[part 19 of 22: packages /TPConfig to /ComponentTypes]
AUTOSAR XML (schema 4-3-0)
package /TPConfig
  can tp config CanTPConfig_E3V_K2CANFD: communication-cluster=E3V_K2CANFD, can-tp-ecu=SAM
    33 x can tp address:
      TA_0x17FC00A5: tp-address=402391205
      TA_0x17FC030E: tp-address=402391822
      TA_0x17FC1601: tp-address=402396673
      TA_0x17FC176E: tp-address=402397038
      TA_0x17FE00A5: tp-address=402522277
      TA_0x17FE030E: tp-address=402522894
      TA_0x17FE1601: tp-address=402527745
      TA_0x17FE176E: tp-address=402528110
      TA_0x1C40000E: tp-address=473956366
      TA_0x1C40002C: tp-address=473956396
      TA_0x1C400031: tp-address=473956401
      TA_0x1C4000A5: tp-address=473956517
      TA_0x1C40020E: tp-address=473956878
      TA_0x1C40022C: tp-address=473956908
      TA_0x1C400231: tp-address=473956913
      TA_0x1C4002A5: tp-address=473957029
      TA_0x1C410000: tp-address=474021888
      TA_0x1C410200: tp-address=474022400
      TA_0x1C42000E: tp-address=474087438
      TA_0x1C42002C: tp-address=474087468
      TA_0x1C420031: tp-address=474087473
      TA_0x1C4200A5: tp-address=474087589
      TA_0x1C42020E: tp-address=474087950
      TA_0x1C42022C: tp-address=474087980
      TA_0x1C420231: tp-address=474087985
      TA_0x1C4202A5: tp-address=474088101
      TA_0x700: tp-address=1792
      TA_0x70E: tp-address=1806
      TA_0x72C: tp-address=1836
      TA_0x731: tp-address=1841
      TA_0x778: tp-address=1912
      TA_0x796: tp-address=1942
      TA_0x79B: tp-address=1947
    9 x can tp channel, all with channel-mode=HALF-DUPLEX-MODE:
      TPC_E3V_K2CANFD_XIX_TPCHType_CANFD_ISO_Diagnose_XIX_0x1C40000E_XIX_0x1C42000E_XIX_Physical: channel-id=292018242
      TPC_E3V_K2CANFD_XIX_TPCHType_CANFD_ISO_Diagnose_XIX_0x1C410000_XIX_Functional: channel-id=1297027718
      TPC_E3V_K2CANFD_XIX_TPCHType_CANFD_OBDC_Diagnose_XIX_0x1C40020E_XIX_0x1C42020E_XIX_Physical: channel-id=1588766103
      TPC_E3V_K2CANFD_XIX_TPCHType_CANFD_OBDC_Diagnose_XIX_0x1C410200_XIX_Functional: channel-id=763241601
      TPC_E3V_K2CANFD_XIX_TPCHType_CANHS_Flash_DIA_XIX_0x17FC1601_XIX_0x17FE1601_XIX_Physical: channel-id=602316840
      TPC_E3V_K2CANFD_XIX_TPCHType_CANHS_Flash_DIA_XIX_0x17FC176E_XIX_0x17FE176E_XIX_Physical: channel-id=421749768
      TPC_E3V_K2CANFD_XIX_TPCHType_CANHS_FoD_Master_XIX_0x17FC030E_XIX_0x17FE030E_XIX_Physical: channel-id=1065783997
      TPC_E3V_K2CANFD_XIX_TPCHType_CANHS_ISO_Diagnose_XIX_0x700_XIX_Functional: channel-id=299429439
      TPC_E3V_K2CANFD_XIX_TPCHType_CANHS_ISO_Diagnose_XIX_0x70E_XIX_0x778_XIX_Physical: channel-id=794831463
    can-tp-connection addressing-format=STANDARD, can-tp-channel=TPC_E3V_K2CANFD_XIX_TPCHType_CANFD_ISO_Diagnose_XIX_0x1C40000E_XIX_0x1C42000E_XIX_Physical, cancellation=true, data-pdu=ISOx_BCM1_Req_FD_XIX_E3V_K2CANFD, flow-control-pdu=ISOx_BCM1_Resp_FD_XIX_E3V_K2CANFD, max-block-size=15, padding-activation=true, receiver=TPN_BCM1_XIX_E3V_K2CANFD_XIX_474087438, ta-type=PHYSICAL, timeout-br=0.1, timeout-bs=1.0, timeout-cr=1.0, timeout-cs=0.2, tp-sdu=DCM_E3V_K2CANFD_XIX_TPCHType_CANFD_ISO_Diagnose_XIX_0x1C40000E_XIX_0x1C42000E_XIX_Physical, transmitter=TPN_Gateway_XIX_E3V_K2CANFD_XIX_473956366:
      ident TPCN_E3V_K2CANFD_XIX_TPCHType_CANFD_ISO_Diagnose_XIX_0x1C40000E_Gateway_XIX_0x1C42000E_BCM1_XIX_Physical
    can-tp-connection addressing-format=STANDARD, can-tp-channel=TPC_E3V_K2CANFD_XIX_TPCHType_CANFD_ISO_Diagnose_XIX_0x1C410000_XIX_Functional, cancellation=true, data-pdu=ISOx_Funkt_Req_All_FD_XIX_E3V_K2CANFD, max-block-size=15, multicast=TA_0x1C410000, padding-activation=true, receiver=[TPN_ELV_XIX_E3V_K2CANFD_XIX_474087473, TPN_MFG_XIX_E3V_K2CANFD_XIX_474087468, TPN_BCM1_XIX_E3V_K2CANFD_XIX_474087438, TPN_WLC1_XIX_E3V_K2CANFD_XIX_474087589], ta-type=FUNCTIONAL, timeout-br=0.1, timeout-bs=1.0, timeout-cr=1.0, timeout-cs=0.2, tp-sdu=DCM_E3V_K2CANFD_XIX_TPCHType_CANFD_ISO_Diagnose_XIX_0x1C410000_XIX_Functional, transmitter=TPN_Gateway_XIX_E3V_K2CANFD_XIX_473956366:
      ident TPCN_E3V_K2CANFD_XIX_TPCHType_CANFD_ISO_Diagnose_XIX_0x1C410000_Gateway_XIX_Functional
    can-tp-connection addressing-format=STANDARD, can-tp-channel=TPC_E3V_K2CANFD_XIX_TPCHType_CANFD_ISO_Diagnose_XIX_0x1C40000E_XIX_0x1C42000E_XIX_Physical, cancellation=true, data-pdu=ISOx_BCM1_Resp_FD_XIX_E3V_K2CANFD, flow-control-pdu=ISOx_BCM1_Req_FD_XIX_E3V_K2CANFD, max-block-size=15, padding-activation=true, receiver=TPN_Gateway_XIX_E3V_K2CANFD_XIX_473956366, ta-type=PHYSICAL, timeout-br=0.1, timeout-bs=1.0, timeout-cr=1.0, timeout-cs=0.2, tp-sdu=DCM_E3V_K2CANFD_XIX_TPCHType_CANFD_ISO_Diagnose_XIX_0x1C42000E_XIX_0x1C40000E_XIX_Physical, transmitter=TPN_BCM1_XIX_E3V_K2CANFD_XIX_474087438:
      ident TPCN_E3V_K2CANFD_XIX_TPCHType_CANFD_ISO_Diagnose_XIX_0x1C42000E_BCM1_XIX_0x1C40000E_Gateway_XIX_Physical
    can-tp-connection addressing-format=STANDARD, can-tp-channel=TPC_E3V_K2CANFD_XIX_TPCHType_CANFD_OBDC_Diagnose_XIX_0x1C40020E_XIX_0x1C42020E_XIX_Physical, cancellation=true, data-pdu=OBDC_BCM1_Req_FD_XIX_E3V_K2CANFD, flow-control-pdu=OBDC_BCM1_Resp_FD_XIX_E3V_K2CANFD, max-block-size=15, padding-activation=true, receiver=TPN_BCM1_XIX_E3V_K2CANFD_XIX_474087950, ta-type=PHYSICAL, timeout-br=0.1, timeout-bs=1.0, timeout-cr=1.0, timeout-cs=0.2, tp-sdu=DCM_E3V_K2CANFD_XIX_TPCHType_CANFD_OBDC_Diagnose_XIX_0x1C40020E_XIX_0x1C42020E_XIX_Physical, transmitter=TPN_Gateway_XIX_E3V_K2CANFD_XIX_473956878:
      ident TPCN_E3V_K2CANFD_XIX_TPCHType_CANFD_OBDC_Diagnose_XIX_0x1C40020E_Gateway_XIX_0x1C42020E_BCM1_XIX_Physical
    can-tp-connection addressing-format=STANDARD, can-tp-channel=TPC_E3V_K2CANFD_XIX_TPCHType_CANFD_OBDC_Diagnose_XIX_0x1C410200_XIX_Functional, cancellation=true, data-pdu=OBDC_Funktionaler_Req_All_FD_XIX_E3V_K2CANFD, max-block-size=15, multicast=TA_0x1C410200, padding-activation=true, receiver=[TPN_ELV_XIX_E3V_K2CANFD_XIX_474087985, TPN_MFG_XIX_E3V_K2CANFD_XIX_474087980, TPN_BCM1_XIX_E3V_K2CANFD_XIX_474087950, TPN_WLC1_XIX_E3V_K2CANFD_XIX_474088101], ta-type=FUNCTIONAL, timeout-br=0.1, timeout-bs=1.0, timeout-cr=1.0, timeout-cs=0.2, tp-sdu=DCM_E3V_K2CANFD_XIX_TPCHType_CANFD_OBDC_Diagnose_XIX_0x1C410200_XIX_Functional, transmitter=TPN_Gateway_XIX_E3V_K2CANFD_XIX_473956878:
      ident TPCN_E3V_K2CANFD_XIX_TPCHType_CANFD_OBDC_Diagnose_XIX_0x1C410200_Gateway_XIX_Functional
    can-tp-connection addressing-format=STANDARD, can-tp-channel=TPC_E3V_K2CANFD_XIX_TPCHType_CANFD_OBDC_Diagnose_XIX_0x1C40020E_XIX_0x1C42020E_XIX_Physical, cancellation=true, data-pdu=OBDC_BCM1_Resp_FD_XIX_E3V_K2CANFD, flow-control-pdu=OBDC_BCM1_Req_FD_XIX_E3V_K2CANFD, max-block-size=15, padding-activation=true, receiver=TPN_Gateway_XIX_E3V_K2CANFD_XIX_473956878, ta-type=PHYSICAL, timeout-br=0.1, timeout-bs=1.0, timeout-cr=1.0, timeout-cs=0.2, tp-sdu=DCM_E3V_K2CANFD_XIX_TPCHType_CANFD_OBDC_Diagnose_XIX_0x1C42020E_XIX_0x1C40020E_XIX_Physical, transmitter=TPN_BCM1_XIX_E3V_K2CANFD_XIX_474087950:
      ident TPCN_E3V_K2CANFD_XIX_TPCHType_CANFD_OBDC_Diagnose_XIX_0x1C42020E_BCM1_XIX_0x1C40020E_Gateway_XIX_Physical
    can-tp-connection addressing-format=STANDARD, can-tp-channel=TPC_E3V_K2CANFD_XIX_TPCHType_CANHS_Flash_DIA_XIX_0x17FC1601_XIX_0x17FE1601_XIX_Physical, cancellation=true, data-pdu=DIA_WWS_Req_XIX_E3V_K2CANFD, flow-control-pdu=DIA_WWS_Resp_XIX_E3V_K2CANFD, max-block-size=15, padding-activation=true, receiver=TPN_BCM1_XIX_E3V_K2CANFD_XIX_402527745, ta-type=PHYSICAL, timeout-br=0.1, timeout-bs=1.0, timeout-cr=1.0, timeout-cs=0.2, tp-sdu=DCM_E3V_K2CANFD_XIX_TPCHType_CANHS_Flash_DIA_XIX_0x17FC1601_XIX_0x17FE1601_XIX_Physical, transmitter=TPN_Gateway_XIX_E3V_K2CANFD_XIX_402396673:
      ident TPCN_E3V_K2CANFD_XIX_TPCHType_CANHS_Flash_DIA_XIX_0x17FC1601_Gateway_XIX_0x17FE1601_BCM1_XIX_Physical
    can-tp-connection addressing-format=STANDARD, can-tp-channel=TPC_E3V_K2CANFD_XIX_TPCHType_CANHS_Flash_DIA_XIX_0x17FC176E_XIX_0x17FE176E_XIX_Physical, cancellation=true, data-pdu=DIA_WWS2_Req_XIX_E3V_K2CANFD, flow-control-pdu=DIA_WWS2_Resp_XIX_E3V_K2CANFD, max-block-size=15, padding-activation=true, receiver=TPN_BCM1_XIX_E3V_K2CANFD_XIX_402528110, ta-type=PHYSICAL, timeout-br=0.1, timeout-bs=1.0, timeout-cr=1.0, timeout-cs=0.2, tp-sdu=DCM_E3V_K2CANFD_XIX_TPCHType_CANHS_Flash_DIA_XIX_0x17FC176E_XIX_0x17FE176E_XIX_Physical, transmitter=TPN_Gateway_XIX_E3V_K2CANFD_XIX_402397038:
      ident TPCN_E3V_K2CANFD_XIX_TPCHType_CANHS_Flash_DIA_XIX_0x17FC176E_Gateway_XIX_0x17FE176E_BCM1_XIX_Physical
    can-tp-connection addressing-format=STANDARD, can-tp-channel=TPC_E3V_K2CANFD_XIX_TPCHType_CANHS_Flash_DIA_XIX_0x17FC1601_XIX_0x17FE1601_XIX_Physical, cancellation=true, data-pdu=DIA_WWS_Resp_XIX_E3V_K2CANFD, flow-control-pdu=DIA_WWS_Req_XIX_E3V_K2CANFD, max-block-size=15, padding-activation=true, receiver=TPN_Gateway_XIX_E3V_K2CANFD_XIX_402396673, ta-type=PHYSICAL, timeout-br=0.1, timeout-bs=1.0, timeout-cr=1.0, timeout-cs=0.2, tp-sdu=DCM_E3V_K2CANFD_XIX_TPCHType_CANHS_Flash_DIA_XIX_0x17FE1601_XIX_0x17FC1601_XIX_Physical, transmitter=TPN_BCM1_XIX_E3V_K2CANFD_XIX_402527745:
      ident TPCN_E3V_K2CANFD_XIX_TPCHType_CANHS_Flash_DIA_XIX_0x17FE1601_BCM1_XIX_0x17FC1601_Gateway_XIX_Physical
    can-tp-connection addressing-format=STANDARD, can-tp-channel=TPC_E3V_K2CANFD_XIX_TPCHType_CANHS_Flash_DIA_XIX_0x17FC176E_XIX_0x17FE176E_XIX_Physical, cancellation=true, data-pdu=DIA_WWS2_Resp_XIX_E3V_K2CANFD, flow-control-pdu=DIA_WWS2_Req_XIX_E3V_K2CANFD, max-block-size=15, padding-activation=true, receiver=TPN_Gateway_XIX_E3V_K2CANFD_XIX_402397038, ta-type=PHYSICAL, timeout-br=0.1, timeout-bs=1.0, timeout-cr=1.0, timeout-cs=0.2, tp-sdu=DCM_E3V_K2CANFD_XIX_TPCHType_CANHS_Flash_DIA_XIX_0x17FE176E_XIX_0x17FC176E_XIX_Physical, transmitter=TPN_BCM1_XIX_E3V_K2CANFD_XIX_402528110:
      ident TPCN_E3V_K2CANFD_XIX_TPCHType_CANHS_Flash_DIA_XIX_0x17FE176E_BCM1_XIX_0x17FC176E_Gateway_XIX_Physical
    can-tp-connection addressing-format=STANDARD, can-tp-channel=TPC_E3V_K2CANFD_XIX_TPCHType_CANHS_FoD_Master_XIX_0x17FC030E_XIX_0x17FE030E_XIX_Physical, cancellation=true, data-pdu=FoD_BCM1_Req_XIX_E3V_K2CANFD, flow-control-pdu=FoD_BCM1_Resp_XIX_E3V_K2CANFD, max-block-size=15, padding-activation=true, receiver=TPN_BCM1_XIX_E3V_K2CANFD_XIX_402522894, ta-type=PHYSICAL, timeout-br=0.1, timeout-bs=1.0, timeout-cr=1.0, timeout-cs=0.2, tp-sdu=SOK_E3V_K2CANFD_XIX_TPCHType_CANHS_FoD_Master_XIX_0x17FC030E_XIX_0x17FE030E_XIX_Physical, transmitter=TPN_Gateway_XIX_E3V_K2CANFD_XIX_402391822:
      ident TPCN_E3V_K2CANFD_XIX_TPCHType_CANHS_FoD_Master_XIX_0x17FC030E_Gateway_XIX_0x17FE030E_BCM1_XIX_Physical
    can-tp-connection addressing-format=STANDARD, can-tp-channel=TPC_E3V_K2CANFD_XIX_TPCHType_CANHS_FoD_Master_XIX_0x17FC030E_XIX_0x17FE030E_XIX_Physical, cancellation=true, data-pdu=FoD_BCM1_Resp_XIX_E3V_K2CANFD, flow-control-pdu=FoD_BCM1_Req_XIX_E3V_K2CANFD, max-block-size=15, padding-activation=true, receiver=TPN_Gateway_XIX_E3V_K2CANFD_XIX_402391822, ta-type=PHYSICAL, timeout-br=0.1, timeout-bs=1.0, timeout-cr=1.0, timeout-cs=0.2, tp-sdu=SOK_E3V_K2CANFD_XIX_TPCHType_CANHS_FoD_Master_XIX_0x17FE030E_XIX_0x17FC030E_XIX_Physical, transmitter=TPN_BCM1_XIX_E3V_K2CANFD_XIX_402522894:
      ident TPCN_E3V_K2CANFD_XIX_TPCHType_CANHS_FoD_Master_XIX_0x17FE030E_BCM1_XIX_0x17FC030E_Gateway_XIX_Physical
    can-tp-connection addressing-format=STANDARD, can-tp-channel=TPC_E3V_K2CANFD_XIX_TPCHType_CANHS_ISO_Diagnose_XIX_0x700_XIX_Functional, cancellation=true, data-pdu=ISO_Funktionaler_Req_All_XIX_E3V_K2CANFD, max-block-size=15, multicast=TA_0x700, padding-activation=true, receiver=[TPN_ELV_XIX_E3V_K2CANFD_XIX_1947, TPN_MFG_XIX_E3V_K2CANFD_XIX_1942, TPN_BCM1_XIX_E3V_K2CANFD_XIX_1912, TPN_WLC1_XIX_E3V_K2CANFD_XIX_402522277], ta-type=FUNCTIONAL, timeout-br=0.1, timeout-bs=1.0, timeout-cr=1.0, timeout-cs=0.2, tp-sdu=DCM_E3V_K2CANFD_XIX_TPCHType_CANHS_ISO_Diagnose_XIX_0x700_XIX_Functional, transmitter=TPN_Gateway_XIX_E3V_K2CANFD_XIX_1806:
      ident TPCN_E3V_K2CANFD_XIX_TPCHType_CANHS_ISO_Diagnose_XIX_0x700_Gateway_XIX_Functional
    can-tp-connection addressing-format=STANDARD, can-tp-channel=TPC_E3V_K2CANFD_XIX_TPCHType_CANHS_ISO_Diagnose_XIX_0x70E_XIX_0x778_XIX_Physical, cancellation=true, data-pdu=ISO_BCM1_Req_XIX_E3V_K2CANFD, flow-control-pdu=ISO_BCM1_Resp_XIX_E3V_K2CANFD, max-block-size=15, padding-activation=true, receiver=TPN_BCM1_XIX_E3V_K2CANFD_XIX_1912, ta-type=PHYSICAL, timeout-br=0.1, timeout-bs=1.0, timeout-cr=1.0, timeout-cs=0.2, tp-sdu=DCM_E3V_K2CANFD_XIX_TPCHType_CANHS_ISO_Diagnose_XIX_0x70E_XIX_0x778_XIX_Physical, transmitter=TPN_Gateway_XIX_E3V_K2CANFD_XIX_1806:
      ident TPCN_E3V_K2CANFD_XIX_TPCHType_CANHS_ISO_Diagnose_XIX_0x70E_Gateway_XIX_0x778_BCM1_XIX_Physical
    can-tp-connection addressing-format=STANDARD, can-tp-channel=TPC_E3V_K2CANFD_XIX_TPCHType_CANHS_ISO_Diagnose_XIX_0x70E_XIX_0x778_XIX_Physical, cancellation=true, data-pdu=ISO_BCM1_Resp_XIX_E3V_K2CANFD, flow-control-pdu=ISO_BCM1_Req_XIX_E3V_K2CANFD, max-block-size=15, padding-activation=true, receiver=TPN_Gateway_XIX_E3V_K2CANFD_XIX_1806, ta-type=PHYSICAL, timeout-br=0.1, timeout-bs=1.0, timeout-cr=1.0, timeout-cs=0.2, tp-sdu=DCM_E3V_K2CANFD_XIX_TPCHType_CANHS_ISO_Diagnose_XIX_0x778_XIX_0x70E_XIX_Physical, transmitter=TPN_BCM1_XIX_E3V_K2CANFD_XIX_1912:
      ident TPCN_E3V_K2CANFD_XIX_TPCHType_CANHS_ISO_Diagnose_XIX_0x778_BCM1_XIX_0x70E_Gateway_XIX_Physical
    30 x can tp node, all with max-fc-wait=15, st-min=0.005, timeout-ar=1.0, timeout-as=1.0:
      TPN_ELV_XIX_E3V_K2CANFD_XIX_1947: tp-address=TA_0x79B
      TPN_ELV_XIX_E3V_K2CANFD_XIX_474087473: tp-address=TA_0x1C420031
      TPN_ELV_XIX_E3V_K2CANFD_XIX_474087985: tp-address=TA_0x1C420231
      TPN_Gateway_XIX_E3V_K2CANFD_XIX_1806: tp-address=TA_0x70E
      TPN_Gateway_XIX_E3V_K2CANFD_XIX_1836: tp-address=TA_0x72C
      TPN_Gateway_XIX_E3V_K2CANFD_XIX_1841: tp-address=TA_0x731
      TPN_Gateway_XIX_E3V_K2CANFD_XIX_402391205: tp-address=TA_0x17FC00A5
      TPN_Gateway_XIX_E3V_K2CANFD_XIX_402391822: tp-address=TA_0x17FC030E
      TPN_Gateway_XIX_E3V_K2CANFD_XIX_402396673: tp-address=TA_0x17FC1601
      TPN_Gateway_XIX_E3V_K2CANFD_XIX_402397038: tp-address=TA_0x17FC176E
      TPN_Gateway_XIX_E3V_K2CANFD_XIX_473956366: tp-address=TA_0x1C40000E
      TPN_Gateway_XIX_E3V_K2CANFD_XIX_473956396: tp-address=TA_0x1C40002C
      TPN_Gateway_XIX_E3V_K2CANFD_XIX_473956401: tp-address=TA_0x1C400031
      TPN_Gateway_XIX_E3V_K2CANFD_XIX_473956517: tp-address=TA_0x1C4000A5
      TPN_Gateway_XIX_E3V_K2CANFD_XIX_473956878: tp-address=TA_0x1C40020E
      TPN_Gateway_XIX_E3V_K2CANFD_XIX_473956908: tp-address=TA_0x1C40022C
      TPN_Gateway_XIX_E3V_K2CANFD_XIX_473956913: tp-address=TA_0x1C400231
      TPN_Gateway_XIX_E3V_K2CANFD_XIX_473957029: tp-address=TA_0x1C4002A5
      TPN_MFG_XIX_E3V_K2CANFD_XIX_1942: tp-address=TA_0x796
      TPN_MFG_XIX_E3V_K2CANFD_XIX_474087468: tp-address=TA_0x1C42002C
      TPN_MFG_XIX_E3V_K2CANFD_XIX_474087980: tp-address=TA_0x1C42022C
      TPN_BCM1_XIX_E3V_K2CANFD_XIX_1912: connector=CN_E3V_K2CANFD, tp-address=TA_0x778
      TPN_BCM1_XIX_E3V_K2CANFD_XIX_402522894: connector=CN_E3V_K2CANFD, tp-address=TA_0x17FE030E
      TPN_BCM1_XIX_E3V_K2CANFD_XIX_402527745: connector=CN_E3V_K2CANFD, tp-address=TA_0x17FE1601
      TPN_BCM1_XIX_E3V_K2CANFD_XIX_402528110: connector=CN_E3V_K2CANFD, tp-address=TA_0x17FE176E
      TPN_BCM1_XIX_E3V_K2CANFD_XIX_474087438: connector=CN_E3V_K2CANFD, tp-address=TA_0x1C42000E
      TPN_BCM1_XIX_E3V_K2CANFD_XIX_474087950: connector=CN_E3V_K2CANFD, tp-address=TA_0x1C42020E
      TPN_WLC1_XIX_E3V_K2CANFD_XIX_402522277: tp-address=TA_0x17FE00A5
      TPN_WLC1_XIX_E3V_K2CANFD_XIX_474087589: tp-address=TA_0x1C4200A5
      TPN_WLC1_XIX_E3V_K2CANFD_XIX_474088101: tp-address=TA_0x1C4202A5
  6 x lin tp config:
    LinTPConfig_E3V_SAM_LIN1: communication-cluster=E3V_SAM_LIN1
      4 x tp address:
        TA_0x0: tp-address=0
        TA_0x2: tp-address=2
        TA_0x59: tp-address=89
        TA_0xB: tp-address=11
      lin-tp-connection data-pdu=MasterReq_XIX_E3V_SAM_LIN1, flow-control=SlaveResp_XIX_E3V_SAM_LIN1, lin-tp-n-sdu=DCM_E3V_SAM_LIN1_XIX_TPCHType_LIN_Diagnose_XIX_0x0_XIX_0x2_XIX_Physical, receiver=TPN_RLF_XIX_E3V_SAM_LIN1_XIX_2, timeout-as=1.0, timeout-cr=1.0, transmitter=TPN_SAM_XIX_E3V_SAM_LIN1_XIX_0:
        ident TPCN_E3V_SAM_LIN1_XIX_TPCHType_LIN_Diagnose_XIX_0x0_BCM1_XIX_0x2_RLS_XIX_Physical
      lin-tp-connection data-pdu=SlaveResp_XIX_E3V_SAM_LIN1, flow-control=MasterReq_XIX_E3V_SAM_LIN1, lin-tp-n-sdu=DCM_E3V_SAM_LIN1_XIX_TPCHType_LIN_Diagnose_XIX_0x2_XIX_0x0_XIX_Physical, receiver=TPN_SAM_XIX_E3V_SAM_LIN1_XIX_0, timeout-as=1.0, timeout-cr=1.0, transmitter=TPN_RLF_XIX_E3V_SAM_LIN1_XIX_2:
        ident TPCN_E3V_SAM_LIN1_XIX_TPCHType_LIN_Diagnose_XIX_0x2_RLS_XIX_0x0_BCM1_XIX_Physical
      lin-tp-connection data-pdu=MasterReq_XIX_E3V_SAM_LIN1, flow-control=SlaveResp_XIX_E3V_SAM_LIN1, lin-tp-n-sdu=DCM_E3V_SAM_LIN1_XIX_TPCHType_LIN_Diagnose_XIX_0x0_XIX_0x59_XIX_Physical, receiver=TPN_WWS2_XIX_E3V_SAM_LIN1_XIX_89, timeout-as=1.0, timeout-cr=1.0, transmitter=TPN_SAM_XIX_E3V_SAM_LIN1_XIX_0:
        ident TPCN_E3V_SAM_LIN1_XIX_TPCHType_LIN_Diagnose_XIX_0x0_BCM1_XIX_0x59_WWS2_XIX_Physical
      lin-tp-connection data-pdu=SlaveResp_XIX_E3V_SAM_LIN1, flow-control=MasterReq_XIX_E3V_SAM_LIN1, lin-tp-n-sdu=DCM_E3V_SAM_LIN1_XIX_TPCHType_LIN_Diagnose_XIX_0x59_XIX_0x0_XIX_Physical, receiver=TPN_SAM_XIX_E3V_SAM_LIN1_XIX_0, timeout-as=1.0, timeout-cr=1.0, transmitter=TPN_WWS2_XIX_E3V_SAM_LIN1_XIX_89:
        ident TPCN_E3V_SAM_LIN1_XIX_TPCHType_LIN_Diagnose_XIX_0x59_WWS2_XIX_0x0_BCM1_XIX_Physical
      lin-tp-connection data-pdu=MasterReq_XIX_E3V_SAM_LIN1, flow-control=SlaveResp_XIX_E3V_SAM_LIN1, lin-tp-n-sdu=DCM_E3V_SAM_LIN1_XIX_TPCHType_LIN_Diagnose_XIX_0x0_XIX_0xB_XIX_Physical, receiver=TPN_WWS_XIX_E3V_SAM_LIN1_XIX_11, timeout-as=1.0, timeout-cr=1.0, transmitter=TPN_SAM_XIX_E3V_SAM_LIN1_XIX_0:
        ident TPCN_E3V_SAM_LIN1_XIX_TPCHType_LIN_Diagnose_XIX_0x0_BCM1_XIX_0xB_WWS_XIX_Physical
      lin-tp-connection data-pdu=SlaveResp_XIX_E3V_SAM_LIN1, flow-control=MasterReq_XIX_E3V_SAM_LIN1, lin-tp-n-sdu=DCM_E3V_SAM_LIN1_XIX_TPCHType_LIN_Diagnose_XIX_0xB_XIX_0x0_XIX_Physical, receiver=TPN_SAM_XIX_E3V_SAM_LIN1_XIX_0, timeout-as=1.0, timeout-cr=1.0, transmitter=TPN_WWS_XIX_E3V_SAM_LIN1_XIX_11:
        ident TPCN_E3V_SAM_LIN1_XIX_TPCHType_LIN_Diagnose_XIX_0xB_WWS_XIX_0x0_BCM1_XIX_Physical
      4 x lin tp node, all with p-2-max=2.0, p-2-timing=0.5:
        TPN_SAM_XIX_E3V_SAM_LIN1_XIX_0: connector=CN_E3V_SAM_LIN1, tp-address=LinTPConfig_E3V_SAM_LIN1/TA_0x0
        TPN_RLF_XIX_E3V_SAM_LIN1_XIX_2: tp-address=TA_0x2
        TPN_WWS2_XIX_E3V_SAM_LIN1_XIX_89: tp-address=TA_0x59
        TPN_WWS_XIX_E3V_SAM_LIN1_XIX_11: tp-address=TA_0xB
    LinTPConfig_E3V_SAM_LIN6: communication-cluster=E3V_SAM_LIN6
      tp address TA_0x0: tp-address=0
      tp address TA_0x1C: tp-address=28
      lin-tp-connection data-pdu=MasterReq_XIX_E3V_SAM_LIN6, flow-control=SlaveResp_XIX_E3V_SAM_LIN6, lin-tp-n-sdu=DCM_E3V_SAM_LIN6_XIX_TPCHType_LIN_Diagnose_XIX_0x0_XIX_0x1C_XIX_Physical, receiver=TPN_LIN_SMLS_XIX_E3V_SAM_LIN6_XIX_28, timeout-as=1.0, timeout-cr=1.0, transmitter=TPN_SAM_XIX_E3V_SAM_LIN6_XIX_0:
        ident TPCN_E3V_SAM_LIN6_XIX_TPCHType_LIN_Diagnose_XIX_0x0_BCM1_XIX_0x1C_LIN_SMLS_XIX_Physical
      lin-tp-connection data-pdu=SlaveResp_XIX_E3V_SAM_LIN6, flow-control=MasterReq_XIX_E3V_SAM_LIN6, lin-tp-n-sdu=DCM_E3V_SAM_LIN6_XIX_TPCHType_LIN_Diagnose_XIX_0x1C_XIX_0x0_XIX_Physical, receiver=TPN_SAM_XIX_E3V_SAM_LIN6_XIX_0, timeout-as=1.0, timeout-cr=1.0, transmitter=TPN_LIN_SMLS_XIX_E3V_SAM_LIN6_XIX_28:
        ident TPCN_E3V_SAM_LIN6_XIX_TPCHType_LIN_Diagnose_XIX_0x1C_LIN_SMLS_XIX_0x0_BCM1_XIX_Physical
      lin tp node TPN_SAM_XIX_E3V_SAM_LIN6_XIX_0: connector=CN_E3V_SAM_LIN6, p-2-max=2.0, p-2-timing=0.5, tp-address=LinTPConfig_E3V_SAM_LIN6/TA_0x0
      lin tp node TPN_LIN_SMLS_XIX_E3V_SAM_LIN6_XIX_28: p-2-max=2.0, p-2-timing=0.5, tp-address=TA_0x1C
    LinTPConfig_E3V_SAM_LIN3: communication-cluster=E3V_SAM_LIN3
      tp address TA_0x0: tp-address=0
      tp address TA_0x5E: tp-address=94
      tp address TA_0x1E: tp-address=30
      lin-tp-connection data-pdu=MasterReq_XIX_E3V_SAM_LIN3, flow-control=SlaveResp_XIX_E3V_SAM_LIN3, lin-tp-n-sdu=DCM_E3V_SAM_LIN3_XIX_TPCHType_LIN_Diagnose_XIX_0x0_XIX_0x5E_XIX_Physical, receiver=TPN_LINDa_XIX_E3V_SAM_LIN3_XIX_94, timeout-as=1.0, timeout-cr=1.0, transmitter=TPN_SAM_XIX_E3V_SAM_LIN3_XIX_0:
        ident TPCN_E3V_SAM_LIN3_XIX_TPCHType_LIN_Diagnose_XIX_0x0_BCM1_XIX_0x5E_Dachkonsole_XIX_Physical
      lin-tp-connection data-pdu=SlaveResp_XIX_E3V_SAM_LIN3, flow-control=MasterReq_XIX_E3V_SAM_LIN3, lin-tp-n-sdu=DCM_E3V_SAM_LIN3_XIX_TPCHType_LIN_Diagnose_XIX_0x5E_XIX_0x0_XIX_Physical, receiver=TPN_SAM_XIX_E3V_SAM_LIN3_XIX_0, timeout-as=1.0, timeout-cr=1.0, transmitter=TPN_LINDa_XIX_E3V_SAM_LIN3_XIX_94:
        ident TPCN_E3V_SAM_LIN3_XIX_TPCHType_LIN_Diagnose_XIX_0x5E_Dachkonsole_XIX_0x0_BCM1_XIX_Physical
      lin-tp-connection data-pdu=MasterReq_XIX_E3V_SAM_LIN3, flow-control=SlaveResp_XIX_E3V_SAM_LIN3, lin-tp-n-sdu=DCM_E3V_SAM_LIN3_XIX_TPCHType_LIN_Diagnose_XIX_0x0_XIX_0x1E_XIX_Physical, receiver=TPN_FS_XIX_E3V_SAM_LIN3_XIX_30, timeout-as=1.0, timeout-cr=1.0, transmitter=TPN_SAM_XIX_E3V_SAM_LIN3_XIX_0:
        ident TPCN_E3V_SAM_LIN3_XIX_TPCHType_LIN_Diagnose_XIX_0x0_BCM1_XIX_0x1E_FS_XIX_Physical
      lin-tp-connection data-pdu=SlaveResp_XIX_E3V_SAM_LIN3, flow-control=MasterReq_XIX_E3V_SAM_LIN3, lin-tp-n-sdu=DCM_E3V_SAM_LIN3_XIX_TPCHType_LIN_Diagnose_XIX_0x1E_XIX_0x0_XIX_Physical, receiver=TPN_SAM_XIX_E3V_SAM_LIN3_XIX_0, timeout-as=1.0, timeout-cr=1.0, transmitter=TPN_FS_XIX_E3V_SAM_LIN3_XIX_30:
        ident TPCN_E3V_SAM_LIN3_XIX_TPCHType_LIN_Diagnose_XIX_0x1E_FS_XIX_0x0_BCM1_XIX_Physical
      lin tp node TPN_SAM_XIX_E3V_SAM_LIN3_XIX_0: connector=CN_E3V_SAM_LIN3, p-2-max=2.0, p-2-timing=0.5, tp-address=LinTPConfig_E3V_SAM_LIN3/TA_0x0
      lin tp node TPN_LINDa_XIX_E3V_SAM_LIN3_XIX_94: p-2-max=2.0, p-2-timing=0.5, tp-address=TA_0x5E
      lin tp node TPN_FS_XIX_E3V_SAM_LIN3_XIX_30: p-2-max=2.0, p-2-timing=0.5, tp-address=TA_0x1E
    LinTPConfig_E3V_SAM_LIN11: communication-cluster=E3V_SAM_LIN11
      4 x tp address:
        TA_0x0: tp-address=0
        TA_0x1D: tp-address=29
        TA_0x6C: tp-address=108
        TA_0x4E: tp-address=78
      lin-tp-connection data-pdu=MasterReq_XIX_E3V_SAM_LIN11, flow-control=SlaveResp_XIX_E3V_SAM_LIN11, lin-tp-n-sdu=DCM_E3V_SAM_LIN11_XIX_TPCHType_LIN_Diagnose_XIX_0x0_XIX_0x1D_XIX_Physical, receiver=TPN_LiSi_XIX_E3V_SAM_LIN11_XIX_29, timeout-as=1.0, timeout-cr=1.0, transmitter=TPN_SAM_XIX_E3V_SAM_LIN11_XIX_0:
        ident TPCN_E3V_SAM_LIN11_XIX_TPCHType_LIN_Diagnose_XIX_0x0_BCM1_XIX_0x1D_LDS_XIX_Physical
      lin-tp-connection data-pdu=SlaveResp_XIX_E3V_SAM_LIN11, flow-control=MasterReq_XIX_E3V_SAM_LIN11, lin-tp-n-sdu=DCM_E3V_SAM_LIN11_XIX_TPCHType_LIN_Diagnose_XIX_0x1D_XIX_0x0_XIX_Physical, receiver=TPN_SAM_XIX_E3V_SAM_LIN11_XIX_0, timeout-as=1.0, timeout-cr=1.0, transmitter=TPN_LiSi_XIX_E3V_SAM_LIN11_XIX_29:
        ident TPCN_E3V_SAM_LIN11_XIX_TPCHType_LIN_Diagnose_XIX_0x1D_LDS_XIX_0x0_BCM1_XIX_Physical
      lin-tp-connection data-pdu=MasterReq_XIX_E3V_SAM_LIN11, flow-control=SlaveResp_XIX_E3V_SAM_LIN11, lin-tp-n-sdu=DCM_E3V_SAM_LIN11_XIX_TPCHType_LIN_Diagnose_XIX_0x0_XIX_0x6C_XIX_Physical, receiver=TPN_DiETa_XIX_E3V_SAM_LIN11_XIX_108, timeout-as=1.0, timeout-cr=1.0, transmitter=TPN_SAM_XIX_E3V_SAM_LIN11_XIX_0:
        ident TPCN_E3V_SAM_LIN11_XIX_TPCHType_LIN_Diagnose_XIX_0x0_BCM1_XIX_0x6C_SL_1_XIX_Physical
      lin-tp-connection data-pdu=SlaveResp_XIX_E3V_SAM_LIN11, flow-control=MasterReq_XIX_E3V_SAM_LIN11, lin-tp-n-sdu=DCM_E3V_SAM_LIN11_XIX_TPCHType_LIN_Diagnose_XIX_0x6C_XIX_0x0_XIX_Physical, receiver=TPN_SAM_XIX_E3V_SAM_LIN11_XIX_0, timeout-as=1.0, timeout-cr=1.0, transmitter=TPN_DiETa_XIX_E3V_SAM_LIN11_XIX_108:
        ident TPCN_E3V_SAM_LIN11_XIX_TPCHType_LIN_Diagnose_XIX_0x6C_SL_1_XIX_0x0_BCM1_XIX_Physical
      lin-tp-connection data-pdu=MasterReq_XIX_E3V_SAM_LIN11, flow-control=SlaveResp_XIX_E3V_SAM_LIN11, lin-tp-n-sdu=DCM_E3V_SAM_LIN11_XIX_TPCHType_LIN_Diagnose_XIX_0x0_XIX_0x4E_XIX_Physical, receiver=TPN_SL_2_MEB_XIX_E3V_SAM_LIN11_XIX_78, timeout-as=1.0, timeout-cr=1.0, transmitter=TPN_SAM_XIX_E3V_SAM_LIN11_XIX_0:
        ident TPCN_E3V_SAM_LIN11_XIX_TPCHType_LIN_Diagnose_XIX_0x0_BCM1_XIX_0x4E_SL_2_XIX_Physical
      lin-tp-connection data-pdu=SlaveResp_XIX_E3V_SAM_LIN11, flow-control=MasterReq_XIX_E3V_SAM_LIN11, lin-tp-n-sdu=DCM_E3V_SAM_LIN11_XIX_TPCHType_LIN_Diagnose_XIX_0x4E_XIX_0x0_XIX_Physical, receiver=TPN_SAM_XIX_E3V_SAM_LIN11_XIX_0, timeout-as=1.0, timeout-cr=1.0, transmitter=TPN_SL_2_MEB_XIX_E3V_SAM_LIN11_XIX_78:
        ident TPCN_E3V_SAM_LIN11_XIX_TPCHType_LIN_Diagnose_XIX_0x4E_SL_2_XIX_0x0_BCM1_XIX_Physical
      4 x lin tp node, all with p-2-max=2.0, p-2-timing=0.5:
        TPN_SAM_XIX_E3V_SAM_LIN11_XIX_0: connector=CN_E3V_SAM_LIN11, tp-address=LinTPConfig_E3V_SAM_LIN11/TA_0x0
        TPN_LiSi_XIX_E3V_SAM_LIN11_XIX_29: tp-address=TA_0x1D
        TPN_DiETa_XIX_E3V_SAM_LIN11_XIX_108: tp-address=TA_0x6C
        TPN_SL_2_MEB_XIX_E3V_SAM_LIN11_XIX_78: tp-address=TA_0x4E
    LinTPConfig_E3V_SAM_LIN4: communication-cluster=E3V_SAM_LIN4
      8 x tp address:
        TA_0x0: tp-address=0
        TA_0x15: tp-address=21
        TA_0x17: tp-address=23
        TA_0xD: tp-address=13
        TA_0xF: tp-address=15
        TA_0x41: tp-address=65
        TA_0x40: tp-address=64
        TA_0x1: tp-address=1
      lin-tp-connection data-pdu=MasterReq_XIX_E3V_SAM_LIN4, flow-control=SlaveResp_XIX_E3V_SAM_LIN4, lin-tp-n-sdu=DCM_E3V_SAM_LIN4_XIX_TPCHType_LIN_Diagnose_XIX_0x0_XIX_0x15_XIX_Physical, receiver=TPN_LLR_LL1_XIX_E3V_SAM_LIN4_XIX_21, timeout-as=1.0, timeout-cr=1.0, transmitter=TPN_SAM_XIX_E3V_SAM_LIN4_XIX_0:
        ident TPCN_E3V_SAM_LIN4_XIX_TPCHType_LIN_Diagnose_XIX_0x0_BCM1_XIX_0x15_LLR_LL1_XIX_Physical
      lin-tp-connection data-pdu=SlaveResp_XIX_E3V_SAM_LIN4, flow-control=MasterReq_XIX_E3V_SAM_LIN4, lin-tp-n-sdu=DCM_E3V_SAM_LIN4_XIX_TPCHType_LIN_Diagnose_XIX_0x15_XIX_0x0_XIX_Physical, receiver=TPN_SAM_XIX_E3V_SAM_LIN4_XIX_0, timeout-as=1.0, timeout-cr=1.0, transmitter=TPN_LLR_LL1_XIX_E3V_SAM_LIN4_XIX_21:
        ident TPCN_E3V_SAM_LIN4_XIX_TPCHType_LIN_Diagnose_XIX_0x15_LLR_LL1_XIX_0x0_BCM1_XIX_Physical
      lin-tp-connection data-pdu=MasterReq_XIX_E3V_SAM_LIN4, flow-control=SlaveResp_XIX_E3V_SAM_LIN4, lin-tp-n-sdu=DCM_E3V_SAM_LIN4_XIX_TPCHType_LIN_Diagnose_XIX_0x0_XIX_0x17_XIX_Physical, receiver=TPN_LLR_LS1_XIX_E3V_SAM_LIN4_XIX_23, timeout-as=1.0, timeout-cr=1.0, transmitter=TPN_SAM_XIX_E3V_SAM_LIN4_XIX_0:
        ident TPCN_E3V_SAM_LIN4_XIX_TPCHType_LIN_Diagnose_XIX_0x0_BCM1_XIX_0x17_LLR_LS1_XIX_Physical
      lin-tp-connection data-pdu=SlaveResp_XIX_E3V_SAM_LIN4, flow-control=MasterReq_XIX_E3V_SAM_LIN4, lin-tp-n-sdu=DCM_E3V_SAM_LIN4_XIX_TPCHType_LIN_Diagnose_XIX_0x17_XIX_0x0_XIX_Physical, receiver=TPN_SAM_XIX_E3V_SAM_LIN4_XIX_0, timeout-as=1.0, timeout-cr=1.0, transmitter=TPN_LLR_LS1_XIX_E3V_SAM_LIN4_XIX_23:
        ident TPCN_E3V_SAM_LIN4_XIX_TPCHType_LIN_Diagnose_XIX_0x17_LLR_LS1_XIX_0x0_BCM1_XIX_Physical
      lin-tp-connection data-pdu=MasterReq_XIX_E3V_SAM_LIN4, flow-control=SlaveResp_XIX_E3V_SAM_LIN4, lin-tp-n-sdu=DCM_E3V_SAM_LIN4_XIX_TPCHType_LIN_Diagnose_XIX_0x0_XIX_0xD_XIX_Physical, receiver=TPN_LLR_RL1_XIX_E3V_SAM_LIN4_XIX_13, timeout-as=1.0, timeout-cr=1.0, transmitter=TPN_SAM_XIX_E3V_SAM_LIN4_XIX_0:
        ident TPCN_E3V_SAM_LIN4_XIX_TPCHType_LIN_Diagnose_XIX_0x0_BCM1_XIX_0xD_LLR_RL1_XIX_Physical
      lin-tp-connection data-pdu=SlaveResp_XIX_E3V_SAM_LIN4, flow-control=MasterReq_XIX_E3V_SAM_LIN4, lin-tp-n-sdu=DCM_E3V_SAM_LIN4_XIX_TPCHType_LIN_Diagnose_XIX_0xD_XIX_0x0_XIX_Physical, receiver=TPN_SAM_XIX_E3V_SAM_LIN4_XIX_0, timeout-as=1.0, timeout-cr=1.0, transmitter=TPN_LLR_RL1_XIX_E3V_SAM_LIN4_XIX_13:
        ident TPCN_E3V_SAM_LIN4_XIX_TPCHType_LIN_Diagnose_XIX_0xD_LLR_RL1_XIX_0x0_BCM1_XIX_Physical
      lin-tp-connection data-pdu=MasterReq_XIX_E3V_SAM_LIN4, flow-control=SlaveResp_XIX_E3V_SAM_LIN4, lin-tp-n-sdu=DCM_E3V_SAM_LIN4_XIX_TPCHType_LIN_Diagnose_XIX_0x0_XIX_0xF_XIX_Physical, receiver=TPN_LLR_RS1_XIX_E3V_SAM_LIN4_XIX_15, timeout-as=1.0, timeout-cr=1.0, transmitter=TPN_SAM_XIX_E3V_SAM_LIN4_XIX_0:
        ident TPCN_E3V_SAM_LIN4_XIX_TPCHType_LIN_Diagnose_XIX_0x0_BCM1_XIX_0xF_LLR_RS1_XIX_Physical
      lin-tp-connection data-pdu=SlaveResp_XIX_E3V_SAM_LIN4, flow-control=MasterReq_XIX_E3V_SAM_LIN4, lin-tp-n-sdu=DCM_E3V_SAM_LIN4_XIX_TPCHType_LIN_Diagnose_XIX_0xF_XIX_0x0_XIX_Physical, receiver=TPN_SAM_XIX_E3V_SAM_LIN4_XIX_0, timeout-as=1.0, timeout-cr=1.0, transmitter=TPN_LLR_RS1_XIX_E3V_SAM_LIN4_XIX_15:
        ident TPCN_E3V_SAM_LIN4_XIX_TPCHType_LIN_Diagnose_XIX_0xF_LLR_RS1_XIX_0x0_BCM1_XIX_Physical
      lin-tp-connection data-pdu=MasterReq_XIX_E3V_SAM_LIN4, flow-control=SlaveResp_XIX_E3V_SAM_LIN4, lin-tp-n-sdu=DCM_E3V_SAM_LIN4_XIX_TPCHType_LIN_Diagnose_XIX_0x0_XIX_0x41_XIX_Physical, receiver=TPN_SPR_BFS_XIX_E3V_SAM_LIN4_XIX_65, timeout-as=1.0, timeout-cr=1.0, transmitter=TPN_SAM_XIX_E3V_SAM_LIN4_XIX_0:
        ident TPCN_E3V_SAM_LIN4_XIX_TPCHType_LIN_Diagnose_XIX_0x0_BCM1_XIX_0x41_SPR_BFS_XIX_Physical
      lin-tp-connection data-pdu=SlaveResp_XIX_E3V_SAM_LIN4, flow-control=MasterReq_XIX_E3V_SAM_LIN4, lin-tp-n-sdu=DCM_E3V_SAM_LIN4_XIX_TPCHType_LIN_Diagnose_XIX_0x41_XIX_0x0_XIX_Physical, receiver=TPN_SAM_XIX_E3V_SAM_LIN4_XIX_0, timeout-as=1.0, timeout-cr=1.0, transmitter=TPN_SPR_BFS_XIX_E3V_SAM_LIN4_XIX_65:
        ident TPCN_E3V_SAM_LIN4_XIX_TPCHType_LIN_Diagnose_XIX_0x41_SPR_BFS_XIX_0x0_BCM1_XIX_Physical
      lin-tp-connection data-pdu=MasterReq_XIX_E3V_SAM_LIN4, flow-control=SlaveResp_XIX_E3V_SAM_LIN4, lin-tp-n-sdu=DCM_E3V_SAM_LIN4_XIX_TPCHType_LIN_Diagnose_XIX_0x0_XIX_0x40_XIX_Physical, receiver=TPN_SPR_FS_XIX_E3V_SAM_LIN4_XIX_64, timeout-as=1.0, timeout-cr=1.0, transmitter=TPN_SAM_XIX_E3V_SAM_LIN4_XIX_0:
        ident TPCN_E3V_SAM_LIN4_XIX_TPCHType_LIN_Diagnose_XIX_0x0_BCM1_XIX_0x40_SPR_FS_XIX_Physical
      lin-tp-connection data-pdu=SlaveResp_XIX_E3V_SAM_LIN4, flow-control=MasterReq_XIX_E3V_SAM_LIN4, lin-tp-n-sdu=DCM_E3V_SAM_LIN4_XIX_TPCHType_LIN_Diagnose_XIX_0x40_XIX_0x0_XIX_Physical, receiver=TPN_SAM_XIX_E3V_SAM_LIN4_XIX_0, timeout-as=1.0, timeout-cr=1.0, transmitter=TPN_SPR_FS_XIX_E3V_SAM_LIN4_XIX_64:
        ident TPCN_E3V_SAM_LIN4_XIX_TPCHType_LIN_Diagnose_XIX_0x40_SPR_FS_XIX_0x0_BCM1_XIX_Physical
      lin-tp-connection data-pdu=MasterReq_XIX_E3V_SAM_LIN4, flow-control=SlaveResp_XIX_E3V_SAM_LIN4, lin-tp-n-sdu=DCM_E3V_SAM_LIN4_XIX_TPCHType_LIN_Diagnose_XIX_0x0_XIX_0x1_XIX_Physical, receiver=TPN_UGDO_S_XIX_E3V_SAM_LIN4_XIX_1, timeout-as=1.0, timeout-cr=1.0, transmitter=TPN_SAM_XIX_E3V_SAM_LIN4_XIX_0:
        ident TPCN_E3V_SAM_LIN4_XIX_TPCHType_LIN_Diagnose_XIX_0x0_BCM1_XIX_0x1_UGDO_XIX_Physical
      lin-tp-connection data-pdu=SlaveResp_XIX_E3V_SAM_LIN4, flow-control=MasterReq_XIX_E3V_SAM_LIN4, lin-tp-n-sdu=DCM_E3V_SAM_LIN4_XIX_TPCHType_LIN_Diagnose_XIX_0x1_XIX_0x0_XIX_Physical, receiver=TPN_SAM_XIX_E3V_SAM_LIN4_XIX_0, timeout-as=1.0, timeout-cr=1.0, transmitter=TPN_UGDO_S_XIX_E3V_SAM_LIN4_XIX_1:
        ident TPCN_E3V_SAM_LIN4_XIX_TPCHType_LIN_Diagnose_XIX_0x1_UGDO_XIX_0x0_BCM1_XIX_Physical
      8 x lin tp node, all with p-2-max=2.0, p-2-timing=0.5:
        TPN_SAM_XIX_E3V_SAM_LIN4_XIX_0: connector=CN_E3V_SAM_LIN4, tp-address=LinTPConfig_E3V_SAM_LIN4/TA_0x0
        TPN_LLR_LL1_XIX_E3V_SAM_LIN4_XIX_21: tp-address=TA_0x15
        TPN_LLR_LS1_XIX_E3V_SAM_LIN4_XIX_23: tp-address=TA_0x17
        TPN_LLR_RL1_XIX_E3V_SAM_LIN4_XIX_13: tp-address=TA_0xD
        TPN_LLR_RS1_XIX_E3V_SAM_LIN4_XIX_15: tp-address=TA_0xF
        TPN_SPR_BFS_XIX_E3V_SAM_LIN4_XIX_65: tp-address=TA_0x41
        TPN_SPR_FS_XIX_E3V_SAM_LIN4_XIX_64: tp-address=TA_0x40
        TPN_UGDO_S_XIX_E3V_SAM_LIN4_XIX_1: tp-address=TA_0x1
    LinTPConfig_E3V_SAM_LIN12: communication-cluster=E3V_SAM_LIN12
      tp address TA_0x0: tp-address=0
      tp address TA_0x53: tp-address=83
      tp address TA_0x52: tp-address=82
      lin-tp-connection data-pdu=MasterReq_XIX_E3V_SAM_LIN12, flow-control=SlaveResp_XIX_E3V_SAM_LIN12, lin-tp-n-sdu=DCM_E3V_SAM_LIN12_XIX_TPCHType_LIN_Diagnose_XIX_0x0_XIX_0x53_XIX_Physical, receiver=TPN_FHSG_HBFS_XIX_E3V_SAM_LIN12_XIX_83, timeout-as=1.0, timeout-cr=1.0, transmitter=TPN_SAM_XIX_E3V_SAM_LIN12_XIX_0:
        ident TPCN_E3V_SAM_LIN12_XIX_TPCHType_LIN_Diagnose_XIX_0x0_BCM1_XIX_0x53_FHSG_HBFS_XIX_Physical
      lin-tp-connection data-pdu=SlaveResp_XIX_E3V_SAM_LIN12, flow-control=MasterReq_XIX_E3V_SAM_LIN12, lin-tp-n-sdu=DCM_E3V_SAM_LIN12_XIX_TPCHType_LIN_Diagnose_XIX_0x53_XIX_0x0_XIX_Physical, receiver=TPN_SAM_XIX_E3V_SAM_LIN12_XIX_0, timeout-as=1.0, timeout-cr=1.0, transmitter=TPN_FHSG_HBFS_XIX_E3V_SAM_LIN12_XIX_83:
        ident TPCN_E3V_SAM_LIN12_XIX_TPCHType_LIN_Diagnose_XIX_0x53_FHSG_HBFS_XIX_0x0_BCM1_XIX_Physical
      lin-tp-connection data-pdu=MasterReq_XIX_E3V_SAM_LIN12, flow-control=SlaveResp_XIX_E3V_SAM_LIN12, lin-tp-n-sdu=DCM_E3V_SAM_LIN12_XIX_TPCHType_LIN_Diagnose_XIX_0x0_XIX_0x52_XIX_Physical, receiver=TPN_FHSG_HFS_XIX_E3V_SAM_LIN12_XIX_82, timeout-as=1.0, timeout-cr=1.0, transmitter=TPN_SAM_XIX_E3V_SAM_LIN12_XIX_0:
        ident TPCN_E3V_SAM_LIN12_XIX_TPCHType_LIN_Diagnose_XIX_0x0_BCM1_XIX_0x52_FHSG_HFS_XIX_Physical
      lin-tp-connection data-pdu=SlaveResp_XIX_E3V_SAM_LIN12, flow-control=MasterReq_XIX_E3V_SAM_LIN12, lin-tp-n-sdu=DCM_E3V_SAM_LIN12_XIX_TPCHType_LIN_Diagnose_XIX_0x52_XIX_0x0_XIX_Physical, receiver=TPN_SAM_XIX_E3V_SAM_LIN12_XIX_0, timeout-as=1.0, timeout-cr=1.0, transmitter=TPN_FHSG_HFS_XIX_E3V_SAM_LIN12_XIX_82:
        ident TPCN_E3V_SAM_LIN12_XIX_TPCHType_LIN_Diagnose_XIX_0x52_FHSG_HFS_XIX_0x0_BCM1_XIX_Physical
      lin tp node TPN_SAM_XIX_E3V_SAM_LIN12_XIX_0: connector=CN_E3V_SAM_LIN12, p-2-max=2.0, p-2-timing=0.5, tp-address=LinTPConfig_E3V_SAM_LIN12/TA_0x0
      lin tp node TPN_FHSG_HBFS_XIX_E3V_SAM_LIN12_XIX_83: p-2-max=2.0, p-2-timing=0.5, tp-address=TA_0x53
      lin tp node TPN_FHSG_HFS_XIX_E3V_SAM_LIN12_XIX_82: p-2-max=2.0, p-2-timing=0.5, tp-address=TA_0x52
package /SecureCommunication
  secure communication props set SecureCommunicationPropsSet
    secure communication authentication props SecureCommunicationAuthenticationProps_XIX_32: category=VW_PROFILE, auth-algorithm=SipHash24, auth-info-tx-length=32
    secure communication authentication props SecureCommunicationAuthenticationProps_Aes128_XIX_32: category=VW_PROFILE, auth-algorithm=AES128, auth-info-tx-length=32
    secure communication authentication props SecureCommunicationAuthenticationProps_XIX_64: category=VW_PROFILE, auth-algorithm=SipHash24, auth-info-tx-length=64
    secure communication freshness props SecureCommunicationFreshnessProps: category=VW_PROFILE, freshness-value-length=64, freshness-value-tx-length=0
package /DiagnosticServices
  5 x diagnostic connection:
    DC_SAM_XIX_TPCHType_CANFD_ISO_Diagnose: functional-request=TPCN_E3V_K2CANFD_XIX_TPCHType_CANFD_ISO_Diagnose_XIX_0x1C410000_Gateway_XIX_Functional, physical-request=TPCN_E3V_K2CANFD_XIX_TPCHType_CANFD_ISO_Diagnose_XIX_0x1C40000E_Gateway_XIX_0x1C42000E_BCM1_XIX_Physical, response=TPCN_E3V_K2CANFD_XIX_TPCHType_CANFD_ISO_Diagnose_XIX_0x1C42000E_BCM1_XIX_0x1C40000E_Gateway_XIX_Physical
    DC_SAM_XIX_TPCHType_CANFD_OBDC_Diagnose: functional-request=TPCN_E3V_K2CANFD_XIX_TPCHType_CANFD_OBDC_Diagnose_XIX_0x1C410200_Gateway_XIX_Functional, physical-request=TPCN_E3V_K2CANFD_XIX_TPCHType_CANFD_OBDC_Diagnose_XIX_0x1C40020E_Gateway_XIX_0x1C42020E_BCM1_XIX_Physical, response=TPCN_E3V_K2CANFD_XIX_TPCHType_CANFD_OBDC_Diagnose_XIX_0x1C42020E_BCM1_XIX_0x1C40020E_Gateway_XIX_Physical
    DC_SAM_XIX_TPCHType_CANHS_Flash_DIA: physical-request=TPCN_E3V_K2CANFD_XIX_TPCHType_CANHS_Flash_DIA_XIX_0x17FC1601_Gateway_XIX_0x17FE1601_BCM1_XIX_Physical, response=TPCN_E3V_K2CANFD_XIX_TPCHType_CANHS_Flash_DIA_XIX_0x17FE1601_BCM1_XIX_0x17FC1601_Gateway_XIX_Physical
    DC_SAM_XIX_TPCHType_CANHS_ISO_Diagnose: functional-request=TPCN_E3V_K2CANFD_XIX_TPCHType_CANHS_ISO_Diagnose_XIX_0x700_Gateway_XIX_Functional, physical-request=TPCN_E3V_K2CANFD_XIX_TPCHType_CANHS_ISO_Diagnose_XIX_0x70E_Gateway_XIX_0x778_BCM1_XIX_Physical, response=TPCN_E3V_K2CANFD_XIX_TPCHType_CANHS_ISO_Diagnose_XIX_0x778_BCM1_XIX_0x70E_Gateway_XIX_Physical
    DC_SAM_XIX_TPCHType_LIN_Diagnose: physical-request=TPCN_E3V_SAM_LIN11_XIX_TPCHType_LIN_Diagnose_XIX_0x0_BCM1_XIX_0x1D_LDS_XIX_Physical, response=TPCN_E3V_SAM_LIN11_XIX_TPCHType_LIN_Diagnose_XIX_0x1D_LDS_XIX_0x0_BCM1_XIX_Physical
  diagnostic service table DST_SAM: ecu-instance=SAM
    diagnostic-connections:
      DC_SAM_XIX_TPCHType_CANFD_ISO_Diagnose
      DC_SAM_XIX_TPCHType_CANFD_OBDC_Diagnose
      DC_SAM_XIX_TPCHType_CANHS_Flash_DIA
      DC_SAM_XIX_TPCHType_CANHS_ISO_Diagnose
      DC_SAM_XIX_TPCHType_LIN_Diagnose
package /Interfaces
  1599 x sender receiver interface:
    IF_AAG_Anhaenger_erkannt
      data DE_AAG_Anhaenger_erkannt: type=boolean
    IF_AAG_ORUData
      data DE_AAG_ORUData: type=uint64
    IF_AAG_ORUDataIndex
      data DE_AAG_ORUDataIndex: type=uint8
    IF_AB_Belegung_VB
      data DE_AB_Belegung_VB: type=uint8
    IF_AB_Crash_Int
      data DE_AB_Crash_Int: type=uint8
    IF_AB_Deaktivierung_HV
      data DE_AB_Deaktivierung_HV: type=uint8
    IF_AB_Front_Crash
      data DE_AB_Front_Crash: type=boolean
    IF_AB_Gurtschloss_BF
      data DE_AB_Gurtschloss_BF: type=uint8
    IF_AB_Gurtschloss_FA
      data DE_AB_Gurtschloss_FA: type=uint8
    IF_AB_Heck_Crash
      data DE_AB_Heck_Crash: type=boolean
    IF_AB_Rollover_Crash
      data DE_AB_Rollover_Crash: type=boolean
    IF_AB_SB_Crash
      data DE_AB_SB_Crash: type=boolean
    IF_AB_SF_Crash
      data DE_AB_SF_Crash: type=boolean
    IF_ADecu1_01_BZ
      data DE_ADecu1_01_BZ: type=uint8
    IF_ADecu1_01_CRC
      data DE_ADecu1_01_CRC: type=uint8
    IF_ADecu1_ORUData
      data DE_ADecu1_ORUData: type=uint64
    IF_ADecu1_ORUDataIndex
      data DE_ADecu1_ORUDataIndex: type=uint8
    IF_ADecu2_01_BZ
      data DE_ADecu2_01_BZ: type=uint8
    IF_ADecu2_01_CRC
      data DE_ADecu2_01_CRC: type=uint8
    IF_ADecu2_ORUData
      data DE_ADecu2_ORUData: type=uint64
    IF_ADecu2_ORUDataIndex
      data DE_ADecu2_ORUDataIndex: type=uint8
    IF_Airbag_01_BZ
      data DE_Airbag_01_BZ: type=uint8
    IF_Airbag_01_CRC
      data DE_Airbag_01_CRC: type=uint8
    IF_Airbag_02_alt
      data DE_Airbag_02_alt: type=boolean
    IF_Airbag_02_BZ
      data DE_Airbag_02_BZ: type=uint8
    IF_Airbag_02_CRC
      data DE_Airbag_02_CRC: type=uint8
    IF_Airbag_ORUData
      data DE_Airbag_ORUData: type=uint64
    IF_Airbag_ORUDataIndex
      data DE_Airbag_ORUDataIndex: type=uint8
    IF_AMBEX_CH_aktiv
      data DE_AMBEX_CH_aktiv: type=boolean
    IF_AMBEX_CH_Trigger
      data DE_AMBEX_CH_Trigger: type=boolean
    IF_Ambex_DLI_InszStatus
      data DE_Ambex_DLI_InszStatus: type=uint8
    IF_Ambex_DLI_Soll_Horizontal_L
      data DE_Ambex_DLI_Soll_Horizontal_L: type=uint16
    IF_Ambex_DLI_Soll_Horizontal_R
      data DE_Ambex_DLI_Soll_Horizontal_R: type=uint16
    IF_Ambex_DLI_Soll_Vertikal_L
      data DE_Ambex_DLI_Soll_Vertikal_L: type=uint16
    IF_Ambex_DLI_Soll_Vertikal_R
      data DE_Ambex_DLI_Soll_Vertikal_R: type=uint16
    IF_Ambex_KY_Anforderung_Zonenortung
      data DE_Ambex_KY_Anforderung_Zonenortung: type=boolean
    IF_AMBEX_LH_aktiv
      data DE_AMBEX_LH_aktiv: type=boolean
    IF_AMBEX_LH_Trigger
      data DE_AMBEX_LH_Trigger: type=boolean
    IF_Ambex_SAL_Abl_Vorne
      data DE_Ambex_SAL_Abl_Vorne: type=boolean
    IF_Ambex_SAL_animprofil
      data DE_Ambex_SAL_animprofil: type=uint8
    IF_Ambex_SAL_Bgr_Vorne
      data DE_Ambex_SAL_Bgr_Vorne: type=boolean
    IF_Ambex_SAL_Design1
      data DE_Ambex_SAL_Design1: type=boolean
    IF_AMBEX_SAL_Design10_L
      data DE_AMBEX_SAL_Design10_L: type=boolean
    IF_AMBEX_SAL_Design10_R
      data DE_AMBEX_SAL_Design10_R: type=boolean
    IF_AMBEX_SAL_Design11_L
      data DE_AMBEX_SAL_Design11_L: type=boolean
    IF_AMBEX_SAL_Design11_R
      data DE_AMBEX_SAL_Design11_R: type=boolean
    IF_AMBEX_SAL_Design12_L
      data DE_AMBEX_SAL_Design12_L: type=boolean
    IF_AMBEX_SAL_Design12_R
      data DE_AMBEX_SAL_Design12_R: type=boolean
    IF_Ambex_SAL_Design2
      data DE_Ambex_SAL_Design2: type=boolean
    IF_AMBEX_SAL_Design3
      data DE_AMBEX_SAL_Design3: type=boolean
    IF_AMBEX_SAL_Design4
      data DE_AMBEX_SAL_Design4: type=boolean
    IF_AMBEX_SAL_Design5
      data DE_AMBEX_SAL_Design5: type=boolean
    IF_AMBEX_SAL_Design6
      data DE_AMBEX_SAL_Design6: type=boolean
    IF_AMBEX_SAL_Design7
      data DE_AMBEX_SAL_Design7: type=boolean
    IF_AMBEX_SAL_Design8
      data DE_AMBEX_SAL_Design8: type=boolean
    IF_AMBEX_SAL_Design9
      data DE_AMBEX_SAL_Design9: type=boolean
    IF_Ambex_SAL_Kzl
      data DE_Ambex_SAL_Kzl: type=boolean
    IF_Ambex_SAL_Schlusslicht
      data DE_Ambex_SAL_Schlusslicht: type=boolean
    IF_Anlernen_LLR_li
      data DE_Anlernen_LLR_li: type=boolean
    IF_Anlernen_LLR_re
      data DE_Anlernen_LLR_re: type=boolean
    IF_APS_Taster
      data DE_APS_Taster: type=uint8
    IF_ASW_Warnung_aktiv_BFS
      data DE_ASW_Warnung_aktiv_BFS: type=boolean
    IF_ASW_Warnung_aktiv_FS
      data DE_ASW_Warnung_aktiv_FS: type=boolean
    IF_ASW_Warnung_aktiv_HBFS
      data DE_ASW_Warnung_aktiv_HBFS: type=boolean
    IF_ASW_Warnung_aktiv_HFS
      data DE_ASW_Warnung_aktiv_HFS: type=boolean
    IF_Aussentemp_gef
      data DE_Aussentemp_gef: type=uint8
    IF_BAPe_Data_Byte_1
      data DE_BAPe_Data_Byte_1: type=uint8
    IF_BAPe_Data_Byte_2
      data DE_BAPe_Data_Byte_2: type=uint8
    IF_BAPe_Data_Byte_3
      data DE_BAPe_Data_Byte_3: type=uint8
    IF_BAPe_Data_Byte_4
      data DE_BAPe_Data_Byte_4: type=uint8
    IF_BAPe_Data_Byte_5
      data DE_BAPe_Data_Byte_5: type=uint8
    IF_BAPe_Data_Byte_6
      data DE_BAPe_Data_Byte_6: type=uint8
    IF_BAPe_FCT_ID
      data DE_BAPe_FCT_ID: type=uint8
    IF_BAPe_LSG_ID1
      data DE_BAPe_LSG_ID1: type=uint8
    IF_BAPe_LSG_ID2
      data DE_BAPe_LSG_ID2: type=uint8
    IF_BAPe_Opcode
      data DE_BAPe_Opcode: type=uint8
    IF_BAPe_Segment
      data DE_BAPe_Segment: type=boolean
    IF_BAPs_Data_Byte_1
      data DE_BAPs_Data_Byte_1: type=uint8
    IF_BAPs_Data_Byte_2
      data DE_BAPs_Data_Byte_2: type=uint8
    IF_BAPs_Data_Byte_3
      data DE_BAPs_Data_Byte_3: type=uint8
    IF_BAPs_Data_Byte_4
      data DE_BAPs_Data_Byte_4: type=uint8
    IF_BAPs_Data_Byte_5
      data DE_BAPs_Data_Byte_5: type=uint8
    IF_BAPs_Data_Byte_6
      data DE_BAPs_Data_Byte_6: type=uint8
    IF_BAPs_FCT_ID
      data DE_BAPs_FCT_ID: type=uint8
    IF_BAPs_LSG_ID1
      data DE_BAPs_LSG_ID1: type=uint8
    IF_BAPs_LSG_ID2
      data DE_BAPs_LSG_ID2: type=uint8
    IF_BAPs_Opcode
      data DE_BAPs_Opcode: type=uint8
    IF_BAPs_Segment
      data DE_BAPs_Segment: type=boolean
    IF_BCM1_Abschaltstufe
      data DE_BCM1_Abschaltstufe: type=boolean
    IF_BCM1_Aussen_Temp_ungef
      data DE_BCM1_Aussen_Temp_ungef: type=uint8
    IF_BCM1_CH_LH_aktiv
      data DE_BCM1_CH_LH_aktiv: type=boolean
    IF_BCM1_EasyEntry_Status
      data DE_BCM1_EasyEntry_Status: type=boolean
    IF_BCM1_FStatus_Aussentemp_ungef
      data DE_BCM1_FStatus_Aussentemp_ungef: type=boolean
    IF_BCM1_KD_Fehler
      data DE_BCM1_KD_Fehler: type=boolean
    IF_BCM1_MH_Schalter
      data DE_BCM1_MH_Schalter: type=boolean
    IF_BCM1_Nachlauftyp
      data DE_BCM1_Nachlauftyp: type=uint8
    IF_BCM1_Nebelschluss_Fzg_Anf
      data DE_BCM1_Nebelschluss_Fzg_Anf: type=boolean
    IF_BCM1_OBD_FStatus_ATemp
      data DE_BCM1_OBD_FStatus_ATemp: type=uint8
    IF_BCM1_Parklicht_li_Anf
      data DE_BCM1_Parklicht_li_Anf: type=boolean
    IF_BCM1_Parklicht_re_Anf
      data DE_BCM1_Parklicht_re_Anf: type=boolean
    IF_BCM1_Schlusslicht_Anf
      data DE_BCM1_Schlusslicht_Anf: type=boolean
    IF_BCM1_SRA_aktiv
      data DE_BCM1_SRA_aktiv: type=boolean
    IF_BCM1_Standlicht_Anf
      data DE_BCM1_Standlicht_Anf: type=boolean
    IF_BCM1_Transport_Mode
      data DE_BCM1_Transport_Mode: type=boolean
    IF_BCM1_Umfeldleuchten_Anf
      data DE_BCM1_Umfeldleuchten_Anf: type=boolean
    IF_BCM1_Warnblink_Taster
      data DE_BCM1_Warnblink_Taster: type=boolean
    IF_BCM_01_BZ
      data DE_BCM_01_BZ: type=uint8
    IF_BCM_01_CRC
      data DE_BCM_01_CRC: type=uint8
    IF_BCM_BFS_aktive_MuFu_Fkt
      data DE_BCM_BFS_aktive_MuFu_Fkt: type=uint8
    IF_BCM_BFS_Fernsteuerung_aktiv
      data DE_BCM_BFS_Fernsteuerung_aktiv: type=boolean
    IF_BCM_BFS_Lordose_ab
      data DE_BCM_BFS_Lordose_ab: type=boolean
    IF_BCM_BFS_Lordose_auf
      data DE_BCM_BFS_Lordose_auf: type=boolean
    IF_BCM_BFS_Lordose_vor
      data DE_BCM_BFS_Lordose_vor: type=boolean
    IF_BCM_BFS_Lordose_zurueck
      data DE_BCM_BFS_Lordose_zurueck: type=boolean
    IF_BCM_BFS_Massage_Dauer
      data DE_BCM_BFS_Massage_Dauer: type=uint8
    IF_BCM_BFS_Massage_Intens_Lehne
      data DE_BCM_BFS_Massage_Intens_Lehne: type=uint8
    IF_BCM_BFS_Massage_Intens_Sitz
      data DE_BCM_BFS_Massage_Intens_Sitz: type=uint8
    IF_BCM_BFS_Massage_Intensitaet
      data DE_BCM_BFS_Massage_Intensitaet: type=uint8
    IF_BCM_BFS_Massage_Prg
      data DE_BCM_BFS_Massage_Prg: type=uint8
    IF_BCM_BFS_Massage_Prg_erweitert
      data DE_BCM_BFS_Massage_Prg_erweitert: type=uint8
    IF_BCM_BFS_Massage_Taster
      data DE_BCM_BFS_Massage_Taster: type=boolean
    IF_BCM_BFS_Memory_Abbruch
      data DE_BCM_BFS_Memory_Abbruch: type=boolean
    IF_BCM_BFS_Memory_Pos
      data DE_BCM_BFS_Memory_Pos: type=uint8
    IF_BCM_BFS_Memory_Save_Recall
      data DE_BCM_BFS_Memory_Save_Recall: type=boolean
    IF_BCM_BFS_MSG_Status
      data DE_BCM_BFS_MSG_Status: type=boolean
    IF_BCM_BFS_Multif_Taster
      data DE_BCM_BFS_Multif_Taster: type=boolean
    IF_BCM_BFS_Pneumatik_Verstellung
      data DE_BCM_BFS_Pneumatik_Verstellung: type=boolean
    IF_BCM_BFS_PreCrash
      data DE_BCM_BFS_PreCrash: type=boolean
    IF_BCM_BFS_Programmwippe
      data DE_BCM_BFS_Programmwippe: type=boolean
    IF_BCM_BFS_SW_eng
      data DE_BCM_BFS_SW_eng: type=boolean
    IF_BCM_BFS_SW_weit
      data DE_BCM_BFS_SW_weit: type=boolean
    IF_BCM_BFS_Wellness_Status
      data DE_BCM_BFS_Wellness_Status: type=boolean
    IF_BCM_BFT_geoeffnet_plaus
      data DE_BCM_BFT_geoeffnet_plaus: type=boolean
    IF_BCM_Bremsbelag_Sensor
      data DE_BCM_Bremsbelag_Sensor: type=boolean
    IF_BCM_Bremsbelag_Sensor_CND
      data DE_BCM_Bremsbelag_Sensor_CND: type=boolean
    IF_BCM_Bremsbelag_Sensor_NAR
      data DE_BCM_Bremsbelag_Sensor_NAR: type=boolean
    IF_BCM_Bremsbelag_Sensor_Rdw
      data DE_BCM_Bremsbelag_Sensor_Rdw: type=uint8
    IF_BCM_Bremsfluessigkeit_Sensor
      data DE_BCM_Bremsfluessigkeit_Sensor: type=boolean
    IF_BCM_Drehwinkel_HL
      data DE_BCM_Drehwinkel_HL: type=uint16
    IF_BCM_Drehwinkel_VL
      data DE_BCM_Drehwinkel_VL: type=uint16
    IF_BCM_Drehwinkelsensortausch_HL
      data DE_BCM_Drehwinkelsensortausch_HL: type=uint8
    IF_BCM_Drehwinkelsensortausch_VL
      data DE_BCM_Drehwinkelsensortausch_VL: type=uint8
    IF_BCM_Eco_Charisma_Taste
      data DE_BCM_Eco_Charisma_Taste: type=boolean
    IF_BCM_Fehlerspeicher_loeschen
      data DE_BCM_Fehlerspeicher_loeschen: type=boolean
    IF_BCM_FH_Freigabe
      data DE_BCM_FH_Freigabe: type=boolean
    IF_BCM_FS_aktive_MuFu_Fkt
      data DE_BCM_FS_aktive_MuFu_Fkt: type=uint8
    IF_BCM_FS_Lordose_ab
      data DE_BCM_FS_Lordose_ab: type=boolean
    IF_BCM_FS_Lordose_auf
      data DE_BCM_FS_Lordose_auf: type=boolean
    IF_BCM_FS_Lordose_vor
      data DE_BCM_FS_Lordose_vor: type=boolean
    IF_BCM_FS_Lordose_zurueck
      data DE_BCM_FS_Lordose_zurueck: type=boolean
    IF_BCM_FS_Massage_Dauer
      data DE_BCM_FS_Massage_Dauer: type=uint8
    IF_BCM_FS_Massage_Intens_Lehne
      data DE_BCM_FS_Massage_Intens_Lehne: type=uint8
    IF_BCM_FS_Massage_Intens_Sitz
      data DE_BCM_FS_Massage_Intens_Sitz: type=uint8
    IF_BCM_FS_Massage_Intensitaet
      data DE_BCM_FS_Massage_Intensitaet: type=uint8
    IF_BCM_FS_Massage_Prg
      data DE_BCM_FS_Massage_Prg: type=uint8
    IF_BCM_FS_Massage_Prg_erweitert
      data DE_BCM_FS_Massage_Prg_erweitert: type=uint8
    IF_BCM_FS_Massage_Taster
      data DE_BCM_FS_Massage_Taster: type=boolean
    IF_BCM_FS_Memory_Abbruch
      data DE_BCM_FS_Memory_Abbruch: type=boolean
    IF_BCM_FS_Memory_Pos
      data DE_BCM_FS_Memory_Pos: type=uint8
    IF_BCM_FS_Memory_Save_Recall
      data DE_BCM_FS_Memory_Save_Recall: type=boolean
    IF_BCM_FS_MSG_Status
      data DE_BCM_FS_MSG_Status: type=boolean
    IF_BCM_FS_Multif_Taster
      data DE_BCM_FS_Multif_Taster: type=boolean
    IF_BCM_FS_Pneumatik_Verstellung
      data DE_BCM_FS_Pneumatik_Verstellung: type=boolean
    IF_BCM_FS_PreCrash
      data DE_BCM_FS_PreCrash: type=boolean
    IF_BCM_FS_Programmwippe
      data DE_BCM_FS_Programmwippe: type=boolean
    IF_BCM_FS_SW_eng
      data DE_BCM_FS_SW_eng: type=boolean
    IF_BCM_FS_SW_weit
      data DE_BCM_FS_SW_weit: type=boolean
    IF_BCM_FS_Wellness_Status
      data DE_BCM_FS_Wellness_Status: type=boolean
    IF_BCM_FT_geoeffnet_plaus
      data DE_BCM_FT_geoeffnet_plaus: type=boolean
    IF_BCM_Kennung_RL_Fzg
      data DE_BCM_Kennung_RL_Fzg: type=boolean
    IF_BCM_KiSi_Umschalt_gesperrt
      data DE_BCM_KiSi_Umschalt_gesperrt: type=boolean
    IF_BCM_Komfortfkt_Freigabe
      data DE_BCM_Komfortfkt_Freigabe: type=boolean
    IF_BCM_Kuehlmittel_Sensor
      data DE_BCM_Kuehlmittel_Sensor: type=boolean
    IF_BCM_LINDa_Toggle
      data DE_BCM_LINDa_Toggle: type=boolean
    IF_BCM_LRH_Taster
      data DE_BCM_LRH_Taster: type=boolean
    IF_BCM_P_Mode_aktiv
      data DE_BCM_P_Mode_aktiv: type=boolean
    IF_BCM_P_Mode_FH_Kl15_aus_aktiv
      data DE_BCM_P_Mode_FH_Kl15_aus_aktiv: type=boolean
    IF_BCM_P_Mode_FH_Reversierschwelle
      data DE_BCM_P_Mode_FH_Reversierschwelle: type=boolean
    IF_BCM_RACE_Mode_aktiv
      data DE_BCM_RACE_Mode_aktiv: type=boolean
    IF_BCM_RGB_Adressierungsart
      data DE_BCM_RGB_Adressierungsart: type=boolean
    IF_BCM_RGB_Bewertung_Dimmzeit
      data DE_BCM_RGB_Bewertung_Dimmzeit: type=boolean
    IF_BCM_RGB_Blau
      data DE_BCM_RGB_Blau: type=uint8
    IF_BCM_RGB_Dimmrampe
      data DE_BCM_RGB_Dimmrampe: type=uint8
    IF_BCM_RGB_Dimmzeit_Zeitbasis
      data DE_BCM_RGB_Dimmzeit_Zeitbasis: type=boolean
    IF_BCM_RGB_Gruen
      data DE_BCM_RGB_Gruen: type=uint8
    IF_BCM_RGB_Gueltigkeit
      data DE_BCM_RGB_Gueltigkeit: type=boolean
    IF_BCM_RGB_Intensitaet
      data DE_BCM_RGB_Intensitaet: type=uint8
    IF_BCM_RGB_Normierung_Intensitaet
      data DE_BCM_RGB_Normierung_Intensitaet: type=boolean
    IF_BCM_RGB_Rot
      data DE_BCM_RGB_Rot: type=uint8
    IF_BCM_RGB_Slave_Adresse
      data DE_BCM_RGB_Slave_Adresse: type=uint16
    IF_BCM_RGB_Sonderfunktion
      data DE_BCM_RGB_Sonderfunktion: type=uint8
    IF_BCM_Rueckfahrlicht_Anf
      data DE_BCM_Rueckfahrlicht_Anf: type=boolean
    IF_BCM_SBE
      data DE_BCM_SBE: type=uint8
    IF_BCM_SGT_Pumpe_BFS
      data DE_BCM_SGT_Pumpe_BFS: type=boolean
    IF_BCM_SGT_Pumpe_FS
      data DE_BCM_SGT_Pumpe_FS: type=boolean
    IF_BCM_SPR_Nachregelung_Freigabe
      data DE_BCM_SPR_Nachregelung_Freigabe: type=boolean
    IF_BCM_Systemfunkionstest_BFS
      data DE_BCM_Systemfunkionstest_BFS: type=boolean
    IF_BCM_Systemfunkionstest_FS
      data DE_BCM_Systemfunkionstest_FS: type=boolean
    IF_BCM_Tankklappensteller_Fehler
      data DE_BCM_Tankklappensteller_Fehler: type=boolean
    IF_BCM_Waschwasser_Sensor
      data DE_BCM_Waschwasser_Sensor: type=boolean
    IF_BCM_Wischer_Parklage
      data DE_BCM_Wischer_Parklage: type=boolean
    IF_Bel_DiETa_Car
      data DE_Bel_DiETa_Car: type=uint8
    IF_Bel_DiETa_Lock_Unlock
      data DE_Bel_DiETa_Lock_Unlock: type=uint8
    IF_Bel_DiETa_Mode
      data DE_Bel_DiETa_Mode: type=uint8
    IF_Bel_DiETa_Parken
      data DE_Bel_DiETa_Parken: type=uint8
    IF_Bel_DiETa_Warnblinken
      data DE_Bel_DiETa_Warnblinken: type=boolean
    IF_Bel_LiSi_Defrost
      data DE_Bel_LiSi_Defrost: type=boolean
    IF_Bel_LiSi_FSH
      data DE_Bel_LiSi_FSH: type=boolean
    IF_Bel_LiSi_HSH
      data DE_Bel_LiSi_HSH: type=boolean
    IF_BFS_MMB_glob_stop
      data DE_BFS_MMB_glob_stop: type=boolean
    IF_BFS_MMB_storage
      data DE_BFS_MMB_storage: type=uint8
    IF_BFS_MMB_tast
      data DE_BFS_MMB_tast: type=boolean
    IF_BFS_MMB_tipp
      data DE_BFS_MMB_tipp: type=boolean
    IF_BH_Blinker_Fehler
      data DE_BH_Blinker_Fehler: type=boolean
    IF_BH_Blinker_li
      data DE_BH_Blinker_li: type=boolean
    IF_BH_Blinker_li_invers
      data DE_BH_Blinker_li_invers: type=boolean
    IF_BH_Blinker_re
      data DE_BH_Blinker_re: type=boolean
    IF_BH_Blinker_re_invers
      data DE_BH_Blinker_re_invers: type=boolean
    IF_BH_Fernlicht
      data DE_BH_Fernlicht: type=boolean
    IF_BH_Lichthupe
      data DE_BH_Lichthupe: type=boolean
    IF_BM_Warnblinken
      data DE_BM_Warnblinken: type=boolean
    IF_BM_WBT_Beleuchtung
      data DE_BM_WBT_Beleuchtung: type=boolean
    IF_BM_ZV_auf
      data DE_BM_ZV_auf: type=boolean
    IF_BM_ZV_zu
      data DE_BM_ZV_zu: type=boolean
    IF_BMCe_ORUData
      data DE_BMCe_ORUData: type=uint64
    IF_BMCe_ORUDataIndex
      data DE_BMCe_ORUDataIndex: type=uint8
    IF_BMS_KundenWarnung
      data DE_BMS_KundenWarnung: type=uint8
    IF_BRL_Bremslicht_Schalter
      data DE_BRL_Bremslicht_Schalter: type=boolean
    IF_BT_FH_Bew_hoch
      data DE_BT_FH_Bew_hoch: type=boolean
    IF_BT_FH_Bew_tief
      data DE_BT_FH_Bew_tief: type=boolean
    IF_BT_Oben_Block_erw
      data DE_BT_Oben_Block_erw: type=boolean
    IF_BT_Sp_Blk_def
      data DE_BT_Sp_Blk_def: type=boolean
    IF_BT_Tuer_geoeffnet
      data DE_BT_Tuer_geoeffnet: type=boolean
    IF_BT_Unten_Block_erw
      data DE_BT_Unten_Block_erw: type=boolean
    IF_CHA_Fahrer_Umschaltung
      data DE_CHA_Fahrer_Umschaltung: type=boolean
    IF_CHA_Ziel_FahrPr_AMB
      data DE_CHA_Ziel_FahrPr_AMB: type=uint8
    IF_CPDFct_FlashAndHonk
      data DE_CPDFct_FlashAndHonk: type=uint8
    IF_DCDC_HR_ORUData
      data DE_DCDC_HR_ORUData: type=uint64
    IF_DCDC_HR_ORUDataIndex
      data DE_DCDC_HR_ORUDataIndex: type=uint8
    IF_DCDC_NV_ORUDataIndex
      data DE_DCDC_NV_ORUDataIndex: type=uint8
    IF_DCDC_ORUData
      data DE_DCDC_ORUData: type=uint64
    IF_Deaktivierung_RS
      data DE_Deaktivierung_RS: type=boolean
    IF_DGN_Verlernzaehler
      data DE_DGN_Verlernzaehler: type=uint8
    IF_DI_KL_58xd
      data DE_DI_KL_58xd: type=uint8
    IF_DI_KL_58xs
      data DE_DI_KL_58xs: type=uint8
    IF_DI_KL_58xt
      data DE_DI_KL_58xt: type=uint8
    IF_DiETa_Car
      data DE_DiETa_Car: type=uint8
    IF_DiETa_Defrost_Taste
      data DE_DiETa_Defrost_Taste: type=uint8
    IF_DiETa_FAS_Stufe
      data DE_DiETa_FAS_Stufe: type=uint8
    IF_DiETa_FSH_Taste
      data DE_DiETa_FSH_Taste: type=uint8
    IF_DiETa_HSH_Taste
      data DE_DiETa_HSH_Taste: type=uint8
    IF_DiETa_Klima
      data DE_DiETa_Klima: type=uint8
    IF_DiETa_Lock_Unlock_Taste
      data DE_DiETa_Lock_Unlock_Taste: type=uint8
    IF_DiETa_Mode
      data DE_DiETa_Mode: type=uint8
    IF_DiETa_Parken
      data DE_DiETa_Parken: type=uint8
    IF_DiETa_ResponseError
      data DE_DiETa_ResponseError: type=boolean
    IF_DiETa_Status
      data DE_DiETa_Status: type=uint8
    IF_DiETa_Warnblink_Taste
      data DE_DiETa_Warnblink_Taste: type=uint8
    IF_DLI_Ambex_RefStatus
      data DE_DLI_Ambex_RefStatus: type=uint8
    IF_DRB1_01_BZ
      data DE_DRB1_01_BZ: type=uint8
    IF_DRB1_01_CRC
      data DE_DRB1_01_CRC: type=uint8
    IF_DRB1_ORUData
      data DE_DRB1_ORUData: type=uint64
    IF_DRB1_ORUDataIndex
      data DE_DRB1_ORUDataIndex: type=uint8
    IF_DRB2_01_BZ
      data DE_DRB2_01_BZ: type=uint8
    IF_DRB2_01_CRC
      data DE_DRB2_01_CRC: type=uint8
    IF_DRB2_ORUData
      data DE_DRB2_ORUData: type=uint64
    IF_DRB2_ORUDataIndex
      data DE_DRB2_ORUDataIndex: type=uint8
    IF_EA_Fahrzeughupe_Anf
      data DE_EA_Fahrzeughupe_Anf: type=boolean
    IF_EA_Innenraumlicht_Anf
      data DE_EA_Innenraumlicht_Anf: type=boolean
    IF_EBKV_2Box_ORUDataIndex
      data DE_EBKV_2Box_ORUDataIndex: type=uint8
    IF_EBKV_ORUData
      data DE_EBKV_ORUData: type=uint64
    IF_eFuse1_ORUData
      data DE_eFuse1_ORUData: type=uint64
    IF_eFuse1_ORUDataIndex
      data DE_eFuse1_ORUDataIndex: type=uint8
    IF_eFuse3_ORUData
      data DE_eFuse3_ORUData: type=uint64
    IF_eFuse3_ORUDataIndex
      data DE_eFuse3_ORUDataIndex: type=uint8
    IF_EM1_HYB_13_BZ
      data DE_EM1_HYB_13_BZ: type=uint8
    IF_EM1_HYB_13_CRC
      data DE_EM1_HYB_13_CRC: type=uint8
    IF_EM2_HYB_13_BZ
      data DE_EM2_HYB_13_BZ: type=uint8
    IF_EM2_HYB_13_CRC
      data DE_EM2_HYB_13_CRC: type=uint8
    IF_Empfindlichkeit_LS
      data DE_Empfindlichkeit_LS: type=uint8
    IF_Empfindlichkeit_RS
      data DE_Empfindlichkeit_RS: type=uint8
    IF_EPB_Status_02
      data DE_EPB_Status_02: type=uint8
    IF_EPH_ORUData
      data DE_EPH_ORUData: type=uint64
    IF_EPH_ORUDataIndex
      data DE_EPH_ORUDataIndex: type=uint8
    IF_eRWK_AD_oeffnen_Anf
      data DE_eRWK_AD_oeffnen_Anf: type=boolean
    IF_eRWK_AD_schliessen_Anf
      data DE_eRWK_AD_schliessen_Anf: type=boolean
    IF_ESC_Bremsfluessigkeits_Sensor
      data DE_ESC_Bremsfluessigkeits_Sensor: type=boolean
    IF_ESC_ORUData
      data DE_ESC_ORUData: type=uint64
    IF_ESC_ORUDataIndex
      data DE_ESC_ORUDataIndex: type=uint8
    IF_ESC_v_Signal_Qualifier_High_Low
      data DE_ESC_v_Signal_Qualifier_High_Low: type=uint8
    IF_ESP_21_BZ
      data DE_ESP_21_BZ: type=uint8
    IF_ESP_21_CRC
      data DE_ESP_21_CRC: type=uint8
    IF_ESP_Laengsbeschl
      data DE_ESP_Laengsbeschl: type=uint16
    IF_ESP_m_Raddrehz
      data DE_ESP_m_Raddrehz: type=uint16
    IF_ESP_QBit_v_Signal
      data DE_ESP_QBit_v_Signal: type=boolean
    IF_ESP_Querbeschleunigung
      data DE_ESP_Querbeschleunigung: type=uint8
    IF_ESP_Status_Bremsentemp_02
      data DE_ESP_Status_Bremsentemp_02: type=uint8
    IF_ESP_v_Signal
      data DE_ESP_v_Signal: type=uint16
    IF_ESP_v_Signal_8Bit
      data DE_ESP_v_Signal_8Bit: type=uint8
    IF_Fahrerdisplay_Kombi_ORUData
      data DE_Fahrerdisplay_Kombi_ORUData: type=uint64
    IF_Fahrerdisplay_Kombi_ORUDataIndex
      data DE_Fahrerdisplay_Kombi_ORUDataIndex: type=uint8
    IF_FAS_Profile_Taster
      data DE_FAS_Profile_Taster: type=uint8
    IF_FAS_Taster
      data DE_FAS_Taster: type=boolean
    IF_FAS_Taster_Fehler
      data DE_FAS_Taster_Fehler: type=boolean
    IF_FASFrontradar_ORUData
      data DE_FASFrontradar_ORUData: type=uint64
    IF_FASFrontradar_ORUDataIndex
      data DE_FASFrontradar_ORUDataIndex: type=uint8
    IF_FFB_HDF_Taste
      data DE_FFB_HDF_Taste: type=boolean
    IF_FH_HBFS_hoch
      data DE_FH_HBFS_hoch: type=boolean
    IF_FH_HBFS_tief
      data DE_FH_HBFS_tief: type=boolean
    IF_FH_HFS_hoch
      data DE_FH_HFS_hoch: type=boolean
    IF_FH_HFS_tief
      data DE_FH_HFS_tief: type=boolean
    IF_FHSG_MST_Architektur
      data DE_FHSG_MST_Architektur: type=boolean
    IF_FHSG_MST_Aussentemp_ungefiltert
      data DE_FHSG_MST_Aussentemp_ungefiltert: type=uint8
    IF_FHSG_MST_BT_Blockerwartung
      data DE_FHSG_MST_BT_Blockerwartung: type=boolean
    IF_FHSG_MST_Crashfall_erkannt
      data DE_FHSG_MST_Crashfall_erkannt: type=boolean
    IF_FHSG_MST_FH_HBFS_AutoHoch
      data DE_FHSG_MST_FH_HBFS_AutoHoch: type=boolean
    IF_FHSG_MST_FH_HBFS_AutoTief
      data DE_FHSG_MST_FH_HBFS_AutoTief: type=boolean
    IF_FHSG_MST_FH_HBFS_ManHoch
      data DE_FHSG_MST_FH_HBFS_ManHoch: type=boolean
    IF_FHSG_MST_FH_HBFS_ManTief
      data DE_FHSG_MST_FH_HBFS_ManTief: type=boolean
    IF_FHSG_MST_FH_HFS_AutoHoch
      data DE_FHSG_MST_FH_HFS_AutoHoch: type=boolean
    IF_FHSG_MST_FH_HFS_AutoTief
      data DE_FHSG_MST_FH_HFS_AutoTief: type=boolean
    IF_FHSG_MST_FH_HFS_ManHoch
      data DE_FHSG_MST_FH_HFS_ManHoch: type=boolean
    IF_FHSG_MST_FH_HFS_ManTief
      data DE_FHSG_MST_FH_HFS_ManTief: type=boolean
    IF_FHSG_MST_FH_KomfortHoch
      data DE_FHSG_MST_FH_KomfortHoch: type=boolean
    IF_FHSG_MST_FH_Komforttief
      data DE_FHSG_MST_FH_Komforttief: type=boolean
    IF_FHSG_MST_FT_Blockerwartung
      data DE_FHSG_MST_FT_Blockerwartung: type=boolean
    IF_FHSG_MST_FT_FH_H_Kisi_ein
      data DE_FHSG_MST_FT_FH_H_Kisi_ein: type=boolean
    IF_FHSG_MST_HBFS_Blockerwartung
      data DE_FHSG_MST_HBFS_Blockerwartung: type=boolean
    IF_FHSG_MST_HFS_Blockerwartung
      data DE_FHSG_MST_HFS_Blockerwartung: type=boolean
    IF_FHSG_MST_Lenkigkeit
      data DE_FHSG_MST_Lenkigkeit: type=boolean
    IF_FHSG_MST_Precrash
      data DE_FHSG_MST_Precrash: type=boolean
    IF_FHSG_void_1
      data DE_FHSG_void_1: type=uint8
    IF_FHSG_void_3
      data DE_FHSG_void_3: type=uint8
    IF_FHSG_void_4
      data DE_FHSG_void_4: type=uint8
    IF_FHSG_void_5
      data DE_FHSG_void_5: type=uint8
    IF_FHSG_void_6
      data DE_FHSG_void_6: type=uint8
    IF_FHSG_void_7
      data DE_FHSG_void_7: type=uint8
    IF_FHSG_void_8
      data DE_FHSG_void_8: type=boolean
    IF_FoD_Transmission_Info
      data DE_FoD_Transmission_Info: type=uint8
    IF_Fronthaube_geoeffnet
      data DE_Fronthaube_geoeffnet: type=boolean
    IF_FS_Luftfeuchte_rel
      data DE_FS_Luftfeuchte_rel: type=uint8
    IF_FS_MMB_glob_stop
      data DE_FS_MMB_glob_stop: type=boolean
    IF_FS_MMB_storage
      data DE_FS_MMB_storage: type=uint8
    IF_FS_MMB_tast
      data DE_FS_MMB_tast: type=boolean
    IF_FS_MMB_tipp
      data DE_FS_MMB_tipp: type=boolean
    IF_FS_ResponseError
      data DE_FS_ResponseError: type=boolean
    IF_FS_Taupunkt
      data DE_FS_Taupunkt: type=uint16
    IF_FS_Temp_Scheibe
      data DE_FS_Temp_Scheibe: type=uint16
    IF_FS_Temp_Sensor
      data DE_FS_Temp_Sensor: type=uint8
    IF_FT_FH_Bew_hoch
      data DE_FT_FH_Bew_hoch: type=boolean
    IF_FT_FH_Bew_tief
      data DE_FT_FH_Bew_tief: type=boolean
    IF_FT_Kisi_li_aktiv
      data DE_FT_Kisi_li_aktiv: type=boolean
    IF_FT_Kisi_re_aktiv
      data DE_FT_Kisi_re_aktiv: type=boolean
    IF_FT_Kisi_Taster_li
      data DE_FT_Kisi_Taster_li: type=boolean
    IF_FT_Kisi_Taster_li_02
      data DE_FT_Kisi_Taster_li_02: type=boolean
    IF_FT_Kisi_Taster_re
      data DE_FT_Kisi_Taster_re: type=boolean
    IF_FT_Kisi_Taster_re_02
      data DE_FT_Kisi_Taster_re_02: type=boolean
    IF_FT_Oben_Block_erw
      data DE_FT_Oben_Block_erw: type=boolean
    IF_FT_Sp_Blk_def
      data DE_FT_Sp_Blk_def: type=boolean
    IF_FT_Tuer_geoeffnet
      data DE_FT_Tuer_geoeffnet: type=boolean
    IF_FT_Unten_Block_erw
      data DE_FT_Unten_Block_erw: type=boolean
    IF_GE_Fahrstufe
      data DE_GE_Fahrstufe: type=uint8
    IF_HBFS_Fehler_Beleuchtung
      data DE_HBFS_Fehler_Beleuchtung: type=boolean
    IF_HBFS_Fehler_FH_Normierung
      data DE_HBFS_Fehler_FH_Normierung: type=boolean
    IF_HBFS_Fehler_FH_Schalter
      data DE_HBFS_Fehler_FH_Schalter: type=boolean
    IF_HBFS_Fehler_Hallsensor
      data DE_HBFS_Fehler_Hallsensor: type=boolean
    IF_HBFS_Fehler_Kodierdaten
      data DE_HBFS_Fehler_Kodierdaten: type=boolean
    IF_HBFS_Fehler_Parameter
      data DE_HBFS_Fehler_Parameter: type=boolean
    IF_HBFS_Fehler_SG
      data DE_HBFS_Fehler_SG: type=boolean
    IF_HBFS_FH_Bew_hoch
      data DE_HBFS_FH_Bew_hoch: type=boolean
    IF_HBFS_FH_Bew_tief
      data DE_HBFS_FH_Bew_tief: type=boolean
    IF_HBFS_FH_Block
      data DE_HBFS_FH_Block: type=boolean
    IF_HBFS_FH_Fang
      data DE_HBFS_FH_Fang: type=boolean
    IF_HBFS_FH_normiert
      data DE_HBFS_FH_normiert: type=boolean
    IF_HBFS_FH_Oeffnung
      data DE_HBFS_FH_Oeffnung: type=uint8
    IF_HBFS_FH_S_AutoHoch
      data DE_HBFS_FH_S_AutoHoch: type=boolean
    IF_HBFS_FH_S_AutoTief
      data DE_HBFS_FH_S_AutoTief: type=boolean
    IF_HBFS_FH_S_ManHoch
      data DE_HBFS_FH_S_ManHoch: type=boolean
    IF_HBFS_FH_S_ManTief
      data DE_HBFS_FH_S_ManTief: type=boolean
    IF_HBFS_FH_Thermo
      data DE_HBFS_FH_Thermo: type=boolean
    IF_HBFS_FH_Ueberspannung
      data DE_HBFS_FH_Ueberspannung: type=boolean
    IF_HBFS_FH_Unterspannung
      data DE_HBFS_FH_Unterspannung: type=boolean
    IF_HBFS_gesafet
      data DE_HBFS_gesafet: type=boolean
    IF_HBFS_Heckrollotaster_betaetigt
      data DE_HBFS_Heckrollotaster_betaetigt: type=boolean
    IF_HBFS_KiSi_Fehler
      data DE_HBFS_KiSi_Fehler: type=boolean
    IF_HBFS_Lock_Taster_inv
      data DE_HBFS_Lock_Taster_inv: type=boolean
    IF_HBFS_Oben_Block_erw
      data DE_HBFS_Oben_Block_erw: type=boolean
    IF_HBFS_RelaisFehler
      data DE_HBFS_RelaisFehler: type=boolean
    IF_HBFS_ResponseError
      data DE_HBFS_ResponseError: type=boolean
    IF_HBFS_Seitenrollo_hoch
      data DE_HBFS_Seitenrollo_hoch: type=boolean
    IF_HBFS_Seitenrollo_tief
      data DE_HBFS_Seitenrollo_tief: type=boolean
    IF_HBFS_SK_betaetigt
      data DE_HBFS_SK_betaetigt: type=boolean
    IF_HBFS_SleepIndication
      data DE_HBFS_SleepIndication: type=boolean
    IF_HBFS_Sperrklinke
      data DE_HBFS_Sperrklinke: type=boolean
    IF_HBFS_Status_KiSi
      data DE_HBFS_Status_KiSi: type=boolean
    IF_HBFS_Status_KiSi_inv
      data DE_HBFS_Status_KiSi_inv: type=boolean
    IF_HBFS_Status_Routine
      data DE_HBFS_Status_Routine: type=uint8
    IF_HBFS_Status_Stellgliedtest
      data DE_HBFS_Status_Stellgliedtest: type=uint8
    IF_HBFS_TAG_betaetigt
      data DE_HBFS_TAG_betaetigt: type=boolean
    IF_HBFS_TCR_Mode_aktiv
      data DE_HBFS_TCR_Mode_aktiv: type=boolean
    IF_HBFS_TIG_betaetigt
      data DE_HBFS_TIG_betaetigt: type=boolean
    IF_HBFS_TIG_betaetigt_oeffnen
      data DE_HBFS_TIG_betaetigt_oeffnen: type=boolean
    IF_HBFS_TIG_betaetigt_schliessen
      data DE_HBFS_TIG_betaetigt_schliessen: type=boolean
    IF_HBFS_Tuer_geoeffnet
      data DE_HBFS_Tuer_geoeffnet: type=boolean
    IF_HBFS_Tuer_Status
      data DE_HBFS_Tuer_Status: type=uint8
    IF_HBFS_Tueroeffnen_Warnung
      data DE_HBFS_Tueroeffnen_Warnung: type=boolean
    IF_HBFS_Tuerschloss_defekt
      data DE_HBFS_Tuerschloss_defekt: type=boolean
    IF_HBFS_UEKB_aktiviert
      data DE_HBFS_UEKB_aktiviert: type=boolean
    IF_HBFS_Unten_Block_erw
      data DE_HBFS_Unten_Block_erw: type=boolean
    IF_HBFS_verriegelt
      data DE_HBFS_verriegelt: type=boolean
    IF_HBFS_Vorraste_betaetigt
      data DE_HBFS_Vorraste_betaetigt: type=boolean
    IF_HD_Hauptraste
      data DE_HD_Hauptraste: type=boolean
    IF_HD_Hauptraste_Auth
      data DE_HD_Hauptraste_Auth: type=boolean
    IF_HD_Vorraste
      data DE_HD_Vorraste: type=boolean
    IF_HD_Vorraste_Auth
      data DE_HD_Vorraste_Auth: type=boolean
    IF_HFS_Fehler_Beleuchtung
      data DE_HFS_Fehler_Beleuchtung: type=boolean
    IF_HFS_Fehler_FH_Normierung
      data DE_HFS_Fehler_FH_Normierung: type=boolean
    IF_HFS_Fehler_FH_Schalter
      data DE_HFS_Fehler_FH_Schalter: type=boolean
    IF_HFS_Fehler_Hallsensor
      data DE_HFS_Fehler_Hallsensor: type=boolean
    IF_HFS_Fehler_Kodierdaten
      data DE_HFS_Fehler_Kodierdaten: type=boolean
    IF_HFS_Fehler_Parameter
      data DE_HFS_Fehler_Parameter: type=boolean
    IF_HFS_Fehler_SG
      data DE_HFS_Fehler_SG: type=boolean
    IF_HFS_FH_Bew_hoch
      data DE_HFS_FH_Bew_hoch: type=boolean
    IF_HFS_FH_Bew_tief
      data DE_HFS_FH_Bew_tief: type=boolean
    IF_HFS_FH_Block
      data DE_HFS_FH_Block: type=boolean
    IF_HFS_FH_Fang
      data DE_HFS_FH_Fang: type=boolean
    IF_HFS_FH_normiert
      data DE_HFS_FH_normiert: type=boolean
    IF_HFS_FH_Oeffnung
      data DE_HFS_FH_Oeffnung: type=uint8
    IF_HFS_FH_S_AutoHoch
      data DE_HFS_FH_S_AutoHoch: type=boolean
    IF_HFS_FH_S_AutoTief
      data DE_HFS_FH_S_AutoTief: type=boolean
    IF_HFS_FH_S_ManHoch
      data DE_HFS_FH_S_ManHoch: type=boolean
    IF_HFS_FH_S_ManTief
      data DE_HFS_FH_S_ManTief: type=boolean
    IF_HFS_FH_Thermo
      data DE_HFS_FH_Thermo: type=boolean
    IF_HFS_FH_Ueberspannung
      data DE_HFS_FH_Ueberspannung: type=boolean
    IF_HFS_FH_Unterspannung
      data DE_HFS_FH_Unterspannung: type=boolean
    IF_HFS_gesafet
      data DE_HFS_gesafet: type=boolean
    IF_HFS_Heckrollotaster_betaetigt
      data DE_HFS_Heckrollotaster_betaetigt: type=boolean
    IF_HFS_KiSi_Fehler
      data DE_HFS_KiSi_Fehler: type=boolean
    IF_HFS_Lock_Taster_inv
      data DE_HFS_Lock_Taster_inv: type=boolean
    IF_HFS_Oben_Block_erw
      data DE_HFS_Oben_Block_erw: type=boolean
    IF_HFS_RelaisFehler
      data DE_HFS_RelaisFehler: type=boolean
    IF_HFS_ResponseError
      data DE_HFS_ResponseError: type=boolean
    IF_HFS_Seitenrollo_hoch
      data DE_HFS_Seitenrollo_hoch: type=boolean
    IF_HFS_Seitenrollo_tief
      data DE_HFS_Seitenrollo_tief: type=boolean
    IF_HFS_SK_betaetigt
      data DE_HFS_SK_betaetigt: type=boolean
    IF_HFS_SleepIndication
      data DE_HFS_SleepIndication: type=boolean
    IF_HFS_Status_KiSi
      data DE_HFS_Status_KiSi: type=boolean
    IF_HFS_Status_Routine
      data DE_HFS_Status_Routine: type=uint8
    IF_HFS_Status_Stellgliedtest
      data DE_HFS_Status_Stellgliedtest: type=uint8
    IF_HFS_TAG_betaetigt
      data DE_HFS_TAG_betaetigt: type=boolean
    IF_HFS_TCR_Mode_aktiv
      data DE_HFS_TCR_Mode_aktiv: type=boolean
    IF_HFS_TIG_betaetigt
      data DE_HFS_TIG_betaetigt: type=boolean
    IF_HFS_TIG_betaetigt_oeffnen
      data DE_HFS_TIG_betaetigt_oeffnen: type=boolean
    IF_HFS_TIG_betaetigt_schliessen
      data DE_HFS_TIG_betaetigt_schliessen: type=boolean
    IF_HFS_Tuer_geoeffnet
      data DE_HFS_Tuer_geoeffnet: type=boolean
    IF_HFS_Tuer_Status
      data DE_HFS_Tuer_Status: type=uint8
    IF_HFS_Tuer_Status_QBit
      data DE_HFS_Tuer_Status_QBit: type=boolean
    IF_HFS_Tueroeffnen_Warnung
      data DE_HFS_Tueroeffnen_Warnung: type=boolean
    IF_HFS_Tuerschloss_defekt
      data DE_HFS_Tuerschloss_defekt: type=boolean
    IF_HFS_UEKB_aktiviert
      data DE_HFS_UEKB_aktiviert: type=boolean
    IF_HFS_Unten_Block_erw
      data DE_HFS_Unten_Block_erw: type=boolean
    IF_HFS_verriegelt
      data DE_HFS_verriegelt: type=boolean
    IF_HFS_Vorraste_betaetigt
      data DE_HFS_Vorraste_betaetigt: type=boolean
    IF_HLR_LRH_Freigabe
      data DE_HLR_LRH_Freigabe: type=boolean
    IF_HMS_aktives_System
      data DE_HMS_aktives_System: type=uint8
    IF_HMS_Fehlerstatus
      data DE_HMS_Fehlerstatus: type=uint8
    IF_HMS_parken_nicht_verfuegbar
      data DE_HMS_parken_nicht_verfuegbar: type=boolean
    IF_HMS_Stillstand
      data DE_HMS_Stillstand: type=uint8
    IF_HMS_Systemstatus
      data DE_HMS_Systemstatus: type=uint8
    IF_HSH_Relais_Anf
      data DE_HSH_Relais_Anf: type=boolean
    IF_HSH_Status
      data DE_HSH_Status: type=uint8
    IF_HUD_ORUData
      data DE_HUD_ORUData: type=uint64
    IF_HUD_ORUDataIndex
      data DE_HUD_ORUDataIndex: type=uint8
    IF_HVL_01_BZ
      data DE_HVL_01_BZ: type=uint8
    IF_HVL_01_CRC
      data DE_HVL_01_CRC: type=uint8
    IF_HVL_Steckerstatus
      data DE_HVL_Steckerstatus: type=uint8
    IF_HVLS_Ladedose_SG1_alt
      data DE_HVLS_Ladedose_SG1_alt: type=boolean
    IF_HVLS_Ladedose_SG2_alt
      data DE_HVLS_Ladedose_SG2_alt: type=boolean
    IF_HVLS_Steckerstatus_SG1
      data DE_HVLS_Steckerstatus_SG1: type=uint8
    IF_HVLS_Steckerstatus_SG2
      data DE_HVLS_Steckerstatus_SG2: type=uint8
    IF_HW_Drehfalle_Tuer_HL
      data DE_HW_Drehfalle_Tuer_HL: type=boolean
    IF_HW_Drehfalle_Tuer_HL_Auth
      data DE_HW_Drehfalle_Tuer_HL_Auth: type=boolean
    IF_HW_Drehfalle_Tuer_HR
      data DE_HW_Drehfalle_Tuer_HR: type=boolean
    IF_HW_Drehfalle_Tuer_HR_Auth
      data DE_HW_Drehfalle_Tuer_HR_Auth: type=boolean
    IF_HW_HD_Taste_Innenraum
      data DE_HW_HD_Taste_Innenraum: type=boolean
    IF_HW_HSB_erkannt
      data DE_HW_HSB_erkannt: type=boolean
    IF_HW_Softtouch_betaetigt
      data DE_HW_Softtouch_betaetigt: type=boolean
    IF_HW_Status_Schloss_gesafet_HL
      data DE_HW_Status_Schloss_gesafet_HL: type=boolean
    IF_HW_Status_Schloss_gesafet_HR
      data DE_HW_Status_Schloss_gesafet_HR: type=boolean
    IF_HW_Status_Schloss_safed_HL_Auth
      data DE_HW_Status_Schloss_safed_HL_Auth: type=boolean
    IF_HW_Status_Schloss_safed_HR_Auth
      data DE_HW_Status_Schloss_safed_HR_Auth: type=boolean
    IF_HW_Status_Schloss_verr_HL_Auth
      data DE_HW_Status_Schloss_verr_HL_Auth: type=boolean
    IF_HW_Status_Schloss_verr_HR_Auth
      data DE_HW_Status_Schloss_verr_HR_Auth: type=boolean
    IF_HW_Status_Schloss_verriegelt_HL
      data DE_HW_Status_Schloss_verriegelt_HL: type=boolean
    IF_HW_Status_Schloss_verriegelt_HR
      data DE_HW_Status_Schloss_verriegelt_HR: type=boolean
    IF_HW_Tankdeckel_offen
      data DE_HW_Tankdeckel_offen: type=boolean
    IF_ICAS1_X_ORUData
      data DE_ICAS1_X_ORUData: type=uint64
    IF_ICAS1_X_ORUDataIndex
      data DE_ICAS1_X_ORUDataIndex: type=uint8
    IF_ICC_eKiSi_Unterdrueck
      data DE_ICC_eKiSi_Unterdrueck: type=uint8
    IF_ICC_Fernbed_ein
      data DE_ICC_Fernbed_ein: type=uint8
    IF_ICC_Innenraumbel_Unterdrueck
      data DE_ICC_Innenraumbel_Unterdrueck: type=uint8
    IF_IL_Dachkonsole_Adressat
      data DE_IL_Dachkonsole_Adressat: type=uint8
    IF_IL_Dachkonsole_Dimmzeit
      data DE_IL_Dachkonsole_Dimmzeit: type=uint8
    IF_IL_Dachkonsole_Zeitbasis
      data DE_IL_Dachkonsole_Zeitbasis: type=boolean
    IF_IL_Dachkonsole_Zielhelligkeit
      data DE_IL_Dachkonsole_Zielhelligkeit: type=uint8
    IF_IL_Innenlicht_aktiv
      data DE_IL_Innenlicht_aktiv: type=boolean
    IF_IL_Klemme_30G_aktiv
      data DE_IL_Klemme_30G_aktiv: type=boolean
    IF_IL_TSG_BFS_Dimmzeit_1
      data DE_IL_TSG_BFS_Dimmzeit_1: type=uint8
    IF_IL_TSG_BFS_Dimmzeit_2
      data DE_IL_TSG_BFS_Dimmzeit_2: type=uint8
    IF_IL_TSG_BFS_Dimmzeit_3
      data DE_IL_TSG_BFS_Dimmzeit_3: type=uint8
    IF_IL_TSG_BFS_Dimmzeit_4
      data DE_IL_TSG_BFS_Dimmzeit_4: type=uint8
    IF_IL_TSG_BFS_Dimmzeit_Basis_1
      data DE_IL_TSG_BFS_Dimmzeit_Basis_1: type=boolean
    IF_IL_TSG_BFS_Dimmzeit_Basis_2
      data DE_IL_TSG_BFS_Dimmzeit_Basis_2: type=boolean
    IF_IL_TSG_BFS_Dimmzeit_Basis_3
      data DE_IL_TSG_BFS_Dimmzeit_Basis_3: type=boolean
    IF_IL_TSG_BFS_Dimmzeit_Basis_4
      data DE_IL_TSG_BFS_Dimmzeit_Basis_4: type=boolean
    IF_IL_TSG_BFS_Zielhelligkeit_1
      data DE_IL_TSG_BFS_Zielhelligkeit_1: type=uint8
    IF_IL_TSG_BFS_Zielhelligkeit_2
      data DE_IL_TSG_BFS_Zielhelligkeit_2: type=uint8
    IF_IL_TSG_BFS_Zielhelligkeit_3
      data DE_IL_TSG_BFS_Zielhelligkeit_3: type=uint8
    IF_IL_TSG_BFS_Zielhelligkeit_4
      data DE_IL_TSG_BFS_Zielhelligkeit_4: type=uint8
    IF_IL_TSG_FS_Dimmzeit_1
      data DE_IL_TSG_FS_Dimmzeit_1: type=uint8
    IF_IL_TSG_FS_Dimmzeit_2
      data DE_IL_TSG_FS_Dimmzeit_2: type=uint8
    IF_IL_TSG_FS_Dimmzeit_3
      data DE_IL_TSG_FS_Dimmzeit_3: type=uint8
    IF_IL_TSG_FS_Dimmzeit_4
      data DE_IL_TSG_FS_Dimmzeit_4: type=uint8
    IF_IL_TSG_FS_Dimmzeit_Basis_1
      data DE_IL_TSG_FS_Dimmzeit_Basis_1: type=boolean
    IF_IL_TSG_FS_Dimmzeit_Basis_2
      data DE_IL_TSG_FS_Dimmzeit_Basis_2: type=boolean
    IF_IL_TSG_FS_Dimmzeit_Basis_3
      data DE_IL_TSG_FS_Dimmzeit_Basis_3: type=boolean
    IF_IL_TSG_FS_Dimmzeit_Basis_4
      data DE_IL_TSG_FS_Dimmzeit_Basis_4: type=boolean
    IF_IL_TSG_FS_Zielhelligkeit_1
      data DE_IL_TSG_FS_Zielhelligkeit_1: type=uint8
    IF_IL_TSG_FS_Zielhelligkeit_2
      data DE_IL_TSG_FS_Zielhelligkeit_2: type=uint8
    IF_IL_TSG_FS_Zielhelligkeit_3
      data DE_IL_TSG_FS_Zielhelligkeit_3: type=uint8
    IF_IL_TSG_FS_Zielhelligkeit_4
      data DE_IL_TSG_FS_Zielhelligkeit_4: type=uint8
    IF_IL_TSG_HBFS_Dimmzeit_1
      data DE_IL_TSG_HBFS_Dimmzeit_1: type=uint8
    IF_IL_TSG_HBFS_Dimmzeit_2
      data DE_IL_TSG_HBFS_Dimmzeit_2: type=uint8
    IF_IL_TSG_HBFS_Dimmzeit_3
      data DE_IL_TSG_HBFS_Dimmzeit_3: type=uint8
    IF_IL_TSG_HBFS_Dimmzeit_4
      data DE_IL_TSG_HBFS_Dimmzeit_4: type=uint8
    IF_IL_TSG_HBFS_Dimmzeit_Basis_1
      data DE_IL_TSG_HBFS_Dimmzeit_Basis_1: type=boolean
    IF_IL_TSG_HBFS_Dimmzeit_Basis_2
      data DE_IL_TSG_HBFS_Dimmzeit_Basis_2: type=boolean
    IF_IL_TSG_HBFS_Dimmzeit_Basis_3
      data DE_IL_TSG_HBFS_Dimmzeit_Basis_3: type=boolean
    IF_IL_TSG_HBFS_Dimmzeit_Basis_4
      data DE_IL_TSG_HBFS_Dimmzeit_Basis_4: type=boolean
    IF_IL_TSG_HBFS_Zielhelligkeit_1
      data DE_IL_TSG_HBFS_Zielhelligkeit_1: type=uint8
    IF_IL_TSG_HBFS_Zielhelligkeit_2
      data DE_IL_TSG_HBFS_Zielhelligkeit_2: type=uint8
    IF_IL_TSG_HBFS_Zielhelligkeit_3
      data DE_IL_TSG_HBFS_Zielhelligkeit_3: type=uint8
    IF_IL_TSG_HBFS_Zielhelligkeit_4
      data DE_IL_TSG_HBFS_Zielhelligkeit_4: type=uint8
    IF_IL_TSG_HFS_Dimmzeit_1
      data DE_IL_TSG_HFS_Dimmzeit_1: type=uint8
    IF_IL_TSG_HFS_Dimmzeit_2
      data DE_IL_TSG_HFS_Dimmzeit_2: type=uint8
    IF_IL_TSG_HFS_Dimmzeit_3
      data DE_IL_TSG_HFS_Dimmzeit_3: type=uint8
    IF_IL_TSG_HFS_Dimmzeit_4
      data DE_IL_TSG_HFS_Dimmzeit_4: type=uint8
    IF_IL_TSG_HFS_Dimmzeit_Basis_1
      data DE_IL_TSG_HFS_Dimmzeit_Basis_1: type=boolean
    IF_IL_TSG_HFS_Dimmzeit_Basis_2
      data DE_IL_TSG_HFS_Dimmzeit_Basis_2: type=boolean
    IF_IL_TSG_HFS_Dimmzeit_Basis_3
      data DE_IL_TSG_HFS_Dimmzeit_Basis_3: type=boolean
    IF_IL_TSG_HFS_Dimmzeit_Basis_4
      data DE_IL_TSG_HFS_Dimmzeit_Basis_4: type=boolean
    IF_IL_TSG_HFS_Zielhelligkeit_1
      data DE_IL_TSG_HFS_Zielhelligkeit_1: type=uint8
    IF_IL_TSG_HFS_Zielhelligkeit_2
      data DE_IL_TSG_HFS_Zielhelligkeit_2: type=uint8
    IF_IL_TSG_HFS_Zielhelligkeit_3
      data DE_IL_TSG_HFS_Zielhelligkeit_3: type=uint8
    IF_IL_TSG_HFS_Zielhelligkeit_4
      data DE_IL_TSG_HFS_Zielhelligkeit_4: type=uint8
    IF_KBI_Aussen_Temp_gef
      data DE_KBI_Aussen_Temp_gef: type=uint8
    IF_KBI_Kilometerstand
      data DE_KBI_Kilometerstand: type=uint32
    IF_KFG_ORUData
      data DE_KFG_ORUData: type=uint64
    IF_KFG_ORUDataIndex
      data DE_KFG_ORUDataIndex: type=uint8
    IF_KL_AL_HL_Anf
      data DE_KL_AL_HL_Anf: type=uint8
    IF_KL_AL_HR_Anf
      data DE_KL_AL_HR_Anf: type=uint8
    IF_KL_AL_VL_Anf
      data DE_KL_AL_VL_Anf: type=uint8
    IF_KL_AL_VR_Anf
      data DE_KL_AL_VR_Anf: type=uint8
    IF_KL_Defrost_LED
      data DE_KL_Defrost_LED: type=boolean
    IF_KL_FSH_LED
      data DE_KL_FSH_LED: type=boolean
    IF_KL_HSH_LED
      data DE_KL_HSH_LED: type=boolean
    IF_KL_LRH_Stufe
      data DE_KL_LRH_Stufe: type=uint8
    IF_KL_LRH_Taster
      data DE_KL_LRH_Taster: type=boolean
    IF_KL_SIL_Soll_li
      data DE_KL_SIL_Soll_li: type=uint8
    IF_KL_SIL_Soll_re
      data DE_KL_SIL_Soll_re: type=uint8
    IF_Klemme_15
      data DE_Klemme_15: type=boolean
    IF_Klemme_X_WWS
      data DE_Klemme_X_WWS: type=boolean
    IF_Klemmen_Status_01_BZ
      data DE_Klemmen_Status_01_BZ: type=uint8
    IF_Klemmen_Status_01_CRC
      data DE_Klemmen_Status_01_CRC: type=uint8
    IF_Klemmen_Steuerung_01_BZ
      data DE_Klemmen_Steuerung_01_BZ: type=uint8
    IF_Klemmen_Steuerung_01_CRC
      data DE_Klemmen_Steuerung_01_CRC: type=uint8
    IF_KN_BCM1_DiagPfad
      data DE_KN_BCM1_DiagPfad: type=boolean
    IF_KST_Anf_Klemme_15_Auth
      data DE_KST_Anf_Klemme_15_Auth: type=boolean
    IF_KST_Anf_Klemme_S
      data DE_KST_Anf_Klemme_S: type=boolean
    IF_KST_BSW_Fehlermode2
      data DE_KST_BSW_Fehlermode2: type=boolean
    IF_KST_BSW_Klemme_15_HW_Ist
      data DE_KST_BSW_Klemme_15_HW_Ist: type=uint8
    IF_KST_BSW_Klemmenhochschalten_Sper
      data DE_KST_BSW_Klemmenhochschalten_Sper: type=boolean
    IF_KST_BSW_Not_Taster_betaetigt
      data DE_KST_BSW_Not_Taster_betaetigt: type=boolean
    IF_KST_BSW_ZAT_betaetigt
      data DE_KST_BSW_ZAT_betaetigt: type=boolean
    IF_KST_KL15LockStatus
      data DE_KST_KL15LockStatus: type=uint8
    IF_KST_Sonderzustand_Anforderung
      data DE_KST_Sonderzustand_Anforderung: type=uint8
    IF_KST_Sonderzustand_Status
      data DE_KST_Sonderzustand_Status: type=uint8
    IF_KY_Ambex_Entfernung_Delta_IDG_01
      data DE_KY_Ambex_Entfernung_Delta_IDG_01: type=uint8
    IF_KY_Ambex_Entfernung_Delta_IDG_02
      data DE_KY_Ambex_Entfernung_Delta_IDG_02: type=uint8
    IF_KY_Ambex_Entfernung_Delta_IDG_03
      data DE_KY_Ambex_Entfernung_Delta_IDG_03: type=uint8
    IF_KY_Ambex_Entfernung_Delta_IDG_04
      data DE_KY_Ambex_Entfernung_Delta_IDG_04: type=uint8
    IF_KY_Ambex_Entfernung_Delta_IDG_05
      data DE_KY_Ambex_Entfernung_Delta_IDG_05: type=uint8
    IF_KY_Ambex_Entfernung_Delta_IDG_06
      data DE_KY_Ambex_Entfernung_Delta_IDG_06: type=uint8
    IF_KY_Ambex_Entfernung_Delta_IDG_07
      data DE_KY_Ambex_Entfernung_Delta_IDG_07: type=uint8
    IF_KY_Ambex_Entfernung_Delta_IDG_08
      data DE_KY_Ambex_Entfernung_Delta_IDG_08: type=uint8
    IF_KY_Ambex_Entfernung_IDG_01
      data DE_KY_Ambex_Entfernung_IDG_01: type=uint8
    IF_KY_Ambex_Entfernung_IDG_02
      data DE_KY_Ambex_Entfernung_IDG_02: type=uint8
    IF_KY_Ambex_Entfernung_IDG_03
      data DE_KY_Ambex_Entfernung_IDG_03: type=uint8
    IF_KY_Ambex_Entfernung_IDG_04
      data DE_KY_Ambex_Entfernung_IDG_04: type=uint8
    IF_KY_Ambex_Entfernung_IDG_05
      data DE_KY_Ambex_Entfernung_IDG_05: type=uint8
    IF_KY_Ambex_Entfernung_IDG_06
      data DE_KY_Ambex_Entfernung_IDG_06: type=uint8
    IF_KY_Ambex_Entfernung_IDG_07
      data DE_KY_Ambex_Entfernung_IDG_07: type=uint8
    IF_KY_Ambex_Entfernung_IDG_08
      data DE_KY_Ambex_Entfernung_IDG_08: type=uint8
    IF_KY_Ambex_Richtung_Delta_IDG_01
      data DE_KY_Ambex_Richtung_Delta_IDG_01: type=uint8
    IF_KY_Ambex_Richtung_Delta_IDG_02
      data DE_KY_Ambex_Richtung_Delta_IDG_02: type=uint8
    IF_KY_Ambex_Richtung_Delta_IDG_03
      data DE_KY_Ambex_Richtung_Delta_IDG_03: type=uint8
    IF_KY_Ambex_Richtung_Delta_IDG_04
      data DE_KY_Ambex_Richtung_Delta_IDG_04: type=uint8
    IF_KY_Ambex_Richtung_Delta_IDG_05
      data DE_KY_Ambex_Richtung_Delta_IDG_05: type=uint8
    IF_KY_Ambex_Richtung_Delta_IDG_06
      data DE_KY_Ambex_Richtung_Delta_IDG_06: type=uint8
    IF_KY_Ambex_Richtung_Delta_IDG_07
      data DE_KY_Ambex_Richtung_Delta_IDG_07: type=uint8
    IF_KY_Ambex_Richtung_Delta_IDG_08
      data DE_KY_Ambex_Richtung_Delta_IDG_08: type=uint8
    IF_KY_Ambex_Richtung_IDG_01
      data DE_KY_Ambex_Richtung_IDG_01: type=uint8
    IF_KY_Ambex_Richtung_IDG_02
      data DE_KY_Ambex_Richtung_IDG_02: type=uint8
    IF_KY_Ambex_Richtung_IDG_03
      data DE_KY_Ambex_Richtung_IDG_03: type=uint8
    IF_KY_Ambex_Richtung_IDG_04
      data DE_KY_Ambex_Richtung_IDG_04: type=uint8
    IF_KY_Ambex_Richtung_IDG_05
      data DE_KY_Ambex_Richtung_IDG_05: type=uint8
    IF_KY_Ambex_Richtung_IDG_06
      data DE_KY_Ambex_Richtung_IDG_06: type=uint8
    IF_KY_Ambex_Richtung_IDG_07
      data DE_KY_Ambex_Richtung_IDG_07: type=uint8
    IF_KY_Ambex_Richtung_IDG_08
      data DE_KY_Ambex_Richtung_IDG_08: type=uint8
    IF_KY_UHF_aktiver_Scantyp
      data DE_KY_UHF_aktiver_Scantyp: type=uint8
    IF_KY_UHF_Bitrate
      data DE_KY_UHF_Bitrate: type=boolean
    IF_KY_UHF_Telegramm_CRCStatus
      data DE_KY_UHF_Telegramm_CRCStatus: type=boolean
    IF_KY_UHF_Transceiver_Modus
      data DE_KY_UHF_Transceiver_Modus: type=boolean
    IF_LE1_ORUData
      data DE_LE1_ORUData: type=uint64
    IF_LE1_ORUDataIndex
      data DE_LE1_ORUDataIndex: type=uint8
    IF_LE1_TorqueLockStatus
      data DE_LE1_TorqueLockStatus: type=uint8
    IF_LE2_ORUData
      data DE_LE2_ORUData: type=uint64
    IF_LE2_ORUDataIndex
      data DE_LE2_ORUDataIndex: type=uint8
    IF_LE2_TorqueLockStatus
      data DE_LE2_TorqueLockStatus: type=uint8
    IF_Lenkhilfe_EPS_ORUData
      data DE_Lenkhilfe_EPS_ORUData: type=uint64
    IF_Lenkhilfe_EPS_ORUDataIndex
      data DE_Lenkhilfe_EPS_ORUDataIndex: type=uint8
    IF_Leselicht_hi_li_LED_defekt
      data DE_Leselicht_hi_li_LED_defekt: type=boolean
    IF_Leselicht_hi_li_SR3_LED_defekt
      data DE_Leselicht_hi_li_SR3_LED_defekt: type=boolean
    IF_Leselicht_hi_li_SR3_Taste_defekt
      data DE_Leselicht_hi_li_SR3_Taste_defekt: type=boolean
    IF_Leselicht_hi_li_Taste_defekt
      data DE_Leselicht_hi_li_Taste_defekt: type=boolean
    IF_Leselicht_hi_re_LED_defekt
      data DE_Leselicht_hi_re_LED_defekt: type=boolean
    IF_Leselicht_hi_re_SR3_LED_defekt
      data DE_Leselicht_hi_re_SR3_LED_defekt: type=boolean
    IF_Leselicht_hi_re_SR3_Taste_defekt
      data DE_Leselicht_hi_re_SR3_Taste_defekt: type=boolean
    IF_Leselicht_hi_re_Taste_defekt
      data DE_Leselicht_hi_re_Taste_defekt: type=boolean
    IF_Leselicht_vo_defekt
      data DE_Leselicht_vo_defekt: type=boolean
    IF_LH_S_3_Bremsl_def
      data DE_LH_S_3_Bremsl_def: type=boolean
    IF_LH_S_Aussenlicht_def
      data DE_LH_S_Aussenlicht_def: type=boolean
    IF_LH_S_Blinker_li_def
      data DE_LH_S_Blinker_li_def: type=boolean
    IF_LH_S_Blinker_re_def
      data DE_LH_S_Blinker_re_def: type=boolean
    IF_LH_S_Brems_Blk_li_def
      data DE_LH_S_Brems_Blk_li_def: type=boolean
    IF_LH_S_Brems_Blk_re_def
      data DE_LH_S_Brems_Blk_re_def: type=boolean
    IF_LH_S_Bremsl_li_def
      data DE_LH_S_Bremsl_li_def: type=boolean
    IF_LH_S_Bremsl_li_ges_def
      data DE_LH_S_Bremsl_li_ges_def: type=boolean
    IF_LH_S_Bremsl_re_def
      data DE_LH_S_Bremsl_re_def: type=boolean
    IF_LH_S_Bremsl_re_ges_def
      data DE_LH_S_Bremsl_re_ges_def: type=boolean
    IF_LH_S_Bremslicht_H_aktiv
      data DE_LH_S_Bremslicht_H_aktiv: type=boolean
    IF_LH_S_Kennzl_def
      data DE_LH_S_Kennzl_def: type=boolean
    IF_LH_S_Nebel_li_def
      data DE_LH_S_Nebel_li_def: type=boolean
    IF_LH_S_Nebel_mi_def
      data DE_LH_S_Nebel_mi_def: type=boolean
    IF_LH_S_Nebel_re_def
      data DE_LH_S_Nebel_re_def: type=boolean
    IF_LH_S_Rueckf_li_def
      data DE_LH_S_Rueckf_li_def: type=boolean
    IF_LH_S_Rueckf_mi_def
      data DE_LH_S_Rueckf_mi_def: type=boolean
    IF_LH_S_Rueckf_re_def
      data DE_LH_S_Rueckf_re_def: type=boolean
    IF_LH_S_Schluss_Brems_li_def
      data DE_LH_S_Schluss_Brems_li_def: type=boolean
    IF_LH_S_Schluss_Brems_mi_def
      data DE_LH_S_Schluss_Brems_mi_def: type=boolean
    IF_LH_S_Schluss_Brems_Nebel_li_def
      data DE_LH_S_Schluss_Brems_Nebel_li_def: type=boolean
    IF_LH_S_Schluss_Brems_Nebel_re_def
      data DE_LH_S_Schluss_Brems_Nebel_re_def: type=boolean
    IF_LH_S_Schluss_Brems_re_def
      data DE_LH_S_Schluss_Brems_re_def: type=boolean
    IF_LH_S_Schluss_Nebel_li_def
      data DE_LH_S_Schluss_Nebel_li_def: type=boolean
    IF_LH_S_Schluss_Nebel_re_def
      data DE_LH_S_Schluss_Nebel_re_def: type=boolean
    IF_LH_S_Schlusslicht_li_def
      data DE_LH_S_Schlusslicht_li_def: type=boolean
    IF_LH_S_Schlusslicht_mi_def
      data DE_LH_S_Schlusslicht_mi_def: type=boolean
    IF_LH_S_Schlusslicht_re_def
      data DE_LH_S_Schlusslicht_re_def: type=boolean
    IF_LH_S_SL_BRL_BLK_li_def
      data DE_LH_S_SL_BRL_BLK_li_def: type=boolean
    IF_LH_S_SL_BRL_BLK_re_def
      data DE_LH_S_SL_BRL_BLK_re_def: type=boolean
    IF_LIM_P_Mode
      data DE_LIM_P_Mode: type=boolean
    IF_LIM_S_Rollo_vo
      data DE_LIM_S_Rollo_vo: type=uint8
    IF_LIM_Tasten_Innenlicht_V_def
      data DE_LIM_Tasten_Innenlicht_V_def: type=boolean
    IF_LIN_SMLS_ECU_defekt
      data DE_LIN_SMLS_ECU_defekt: type=boolean
    IF_LIN_SMLS_elektrischer_Fehler
      data DE_LIN_SMLS_elektrischer_Fehler: type=boolean
    IF_LIN_SMLS_mechanischer_Fehler
      data DE_LIN_SMLS_mechanischer_Fehler: type=boolean
    IF_LIN_SMLS_RAM_ROM_Fehler
      data DE_LIN_SMLS_RAM_ROM_Fehler: type=boolean
    IF_LIN_SMLS_ResponseError
      data DE_LIN_SMLS_ResponseError: type=boolean
    IF_LIN_SMLS_Ueberspannung
      data DE_LIN_SMLS_Ueberspannung: type=boolean
    IF_LIN_SMLS_Unterspannung
      data DE_LIN_SMLS_Unterspannung: type=boolean
    IF_LIN_SMLS_Zaehler
      data DE_LIN_SMLS_Zaehler: type=uint8
    IF_LINDa_defekt
      data DE_LINDa_defekt: type=boolean
    IF_LINDa_ResponseError
      data DE_LINDa_ResponseError: type=boolean
    IF_LINDa_S_Rollo_vo
      data DE_LINDa_S_Rollo_vo: type=uint8
    IF_LINDae_Dummy_4_7
      data DE_LINDae_Dummy_4_7: type=boolean
    IF_LLP_L_ORUData
      data DE_LLP_L_ORUData: type=uint64
    IF_LLP_L_ORUDataIndex
      data DE_LLP_L_ORUDataIndex: type=uint8
    IF_LLP_R_ORUData
      data DE_LLP_R_ORUData: type=uint64
    IF_LLP_R_ORUDataIndex
      data DE_LLP_R_ORUDataIndex: type=uint8
    IF_LLR_LL1_Blockierung
      data DE_LLR_LL1_Blockierung: type=boolean
    IF_LLR_LL1_CodierPinError
      data DE_LLR_LL1_CodierPinError: type=boolean
    IF_LLR_LL1_Ist_Drehzahl
      data DE_LLR_LL1_Ist_Drehzahl: type=uint8
    IF_LLR_LL1_Lokalaktiv
      data DE_LLR_LL1_Lokalaktiv: type=boolean
    IF_LLR_LL1_Luefter_defekt
      data DE_LLR_LL1_Luefter_defekt: type=boolean
    IF_LLR_LL1_ResponseError
      data DE_LLR_LL1_ResponseError: type=boolean
    IF_LLR_LL1_Ueberspannung
      data DE_LLR_LL1_Ueberspannung: type=boolean
    IF_LLR_LL1_Uebertemperatur
      data DE_LLR_LL1_Uebertemperatur: type=boolean
    IF_LLR_LL1_Unterspannung
      data DE_LLR_LL1_Unterspannung: type=boolean
    IF_LLR_LS1_Blockierung
      data DE_LLR_LS1_Blockierung: type=boolean
    IF_LLR_LS1_CodierPinError
      data DE_LLR_LS1_CodierPinError: type=boolean
    IF_LLR_LS1_Ist_Drehzahl
      data DE_LLR_LS1_Ist_Drehzahl: type=uint8
    IF_LLR_LS1_Lokalaktiv
      data DE_LLR_LS1_Lokalaktiv: type=boolean
    IF_LLR_LS1_Luefter_defekt
      data DE_LLR_LS1_Luefter_defekt: type=boolean
    IF_LLR_LS1_ResponseError
      data DE_LLR_LS1_ResponseError: type=boolean
    IF_LLR_LS1_Ueberspannung
      data DE_LLR_LS1_Ueberspannung: type=boolean
    IF_LLR_LS1_Uebertemperatur
      data DE_LLR_LS1_Uebertemperatur: type=boolean
    IF_LLR_LS1_Unterspannung
      data DE_LLR_LS1_Unterspannung: type=boolean
    IF_LLR_RL1_Blockierung
      data DE_LLR_RL1_Blockierung: type=boolean
    IF_LLR_RL1_CodierPinError
      data DE_LLR_RL1_CodierPinError: type=boolean
    IF_LLR_RL1_Ist_Drehzahl
      data DE_LLR_RL1_Ist_Drehzahl: type=uint8
    IF_LLR_RL1_Lokalaktiv
      data DE_LLR_RL1_Lokalaktiv: type=boolean
    IF_LLR_RL1_Luefter_defekt
      data DE_LLR_RL1_Luefter_defekt: type=boolean
    IF_LLR_RL1_ResponseError
      data DE_LLR_RL1_ResponseError: type=boolean
    IF_LLR_RL1_Ueberspannung
      data DE_LLR_RL1_Ueberspannung: type=boolean
    IF_LLR_RL1_Uebertemperatur
      data DE_LLR_RL1_Uebertemperatur: type=boolean
    IF_LLR_RL1_Unterspannung
      data DE_LLR_RL1_Unterspannung: type=boolean
    IF_LLR_RS1_Blockierung
      data DE_LLR_RS1_Blockierung: type=boolean
    IF_LLR_RS1_CodierPinError
      data DE_LLR_RS1_CodierPinError: type=boolean
    IF_LLR_RS1_Ist_Drehzahl
      data DE_LLR_RS1_Ist_Drehzahl: type=uint8
    IF_LLR_RS1_Lokalaktiv
      data DE_LLR_RS1_Lokalaktiv: type=boolean
    IF_LLR_RS1_Luefter_defekt
      data DE_LLR_RS1_Luefter_defekt: type=boolean
    IF_LLR_RS1_ResponseError
      data DE_LLR_RS1_ResponseError: type=boolean
    IF_LLR_RS1_Ueberspannung
      data DE_LLR_RS1_Ueberspannung: type=boolean
    IF_LLR_RS1_Uebertemperatur
      data DE_LLR_RS1_Uebertemperatur: type=boolean
    IF_LLR_RS1_Unterspannung
      data DE_LLR_RS1_Unterspannung: type=boolean
    IF_LnchCtl_StReq
      data DE_LnchCtl_StReq: type=uint8
    IF_LR_HZG_01_alt
      data DE_LR_HZG_01_alt: type=boolean
    IF_LR_HZG_Konfiguration
      data DE_LR_HZG_Konfiguration: type=uint8
    IF_LR_HZG_Taster_on_off
      data DE_LR_HZG_Taster_on_off: type=boolean
    IF_LR_HZG_Temp_Sensor
      data DE_LR_HZG_Temp_Sensor: type=uint8
    IF_LRH_aktiv
      data DE_LRH_aktiv: type=boolean
    IF_LRH_On_Off
      data DE_LRH_On_Off: type=uint8
    IF_LRH_Stellglied_aktiv
      data DE_LRH_Stellglied_aktiv: type=boolean
    IF_LRL1_ORUData
      data DE_LRL1_ORUData: type=uint64
    IF_LRL1_ORUDataIndex
      data DE_LRL1_ORUDataIndex: type=uint8
    IF_LRL2_ORUData
      data DE_LRL2_ORUData: type=uint64
    IF_LRL2_ORUDataIndex
      data DE_LRL2_ORUDataIndex: type=uint8
    IF_LRL3_ORUData
      data DE_LRL3_ORUData: type=uint64
    IF_LRL3_ORUDataIndex
      data DE_LRL3_ORUDataIndex: type=uint8
    IF_LRL_L_01_BZ
      data DE_LRL_L_01_BZ: type=uint8
    IF_LRL_L_01_CRC
      data DE_LRL_L_01_CRC: type=uint8
    IF_LRL_M_01_BZ
      data DE_LRL_M_01_BZ: type=uint8
    IF_LRL_M_01_CRC
      data DE_LRL_M_01_CRC: type=uint8
    IF_LRL_R_01_BZ
      data DE_LRL_R_01_BZ: type=uint8
    IF_LRL_R_01_CRC
      data DE_LRL_R_01_CRC: type=uint8
    IF_LS_defekt
      data DE_LS_defekt: type=boolean
    IF_LS_Dunkel
      data DE_LS_Dunkel: type=boolean
    IF_LS_Error
      data DE_LS_Error: type=boolean
    IF_LS_Helligkeit_FW
      data DE_LS_Helligkeit_FW: type=uint16
    IF_LS_Helligkeit_IR
      data DE_LS_Helligkeit_IR: type=uint8
    IF_LS_Licht_ein
      data DE_LS_Licht_ein: type=boolean
    IF_LS_Licht_ein_invers
      data DE_LS_Licht_ein_invers: type=boolean
    IF_LS_TFL_mit_SL_ein
      data DE_LS_TFL_mit_SL_ein: type=boolean
    IF_LS_Verbau
      data DE_LS_Verbau: type=boolean
    IF_LSS_Tastencode
      data DE_LSS_Tastencode: type=uint8
    IF_LTM_ResponseError
      data DE_LTM_ResponseError: type=boolean
    IF_LTM_StatusLichttastenmodul
      data DE_LTM_StatusLichttastenmodul: type=uint8
    IF_LV_Abblendlicht_Anzeige
      data DE_LV_Abblendlicht_Anzeige: type=boolean
    IF_LWR_SollDC
      data DE_LWR_SollDC: type=uint8
    IF_MaaSBladeMyc_ORUData
      data DE_MaaSBladeMyc_ORUData: type=uint64
    IF_MaaSBladeMyc_ORUDataIndex
      data DE_MaaSBladeMyc_ORUDataIndex: type=uint8
    IF_MainBlade_ORUData
      data DE_MainBlade_ORUData: type=uint64
    IF_MainBlade_ORUDataIndex
      data DE_MainBlade_ORUDataIndex: type=uint8
    IF_Master_Zaehler
      data DE_Master_Zaehler: type=uint8
    IF_MF_DCDC_Istmodus
      data DE_MF_DCDC_Istmodus: type=uint8
    IF_MF_Fahrlicht
      data DE_MF_Fahrlicht: type=boolean
    IF_MF_Fernbed_ein
      data DE_MF_Fernbed_ein: type=boolean
    IF_MF_Frontintervall
      data DE_MF_Frontintervall: type=boolean
    IF_MF_Frontwaschen
      data DE_MF_Frontwaschen: type=boolean
    IF_MF_Fussraumbel
      data DE_MF_Fussraumbel: type=boolean
    IF_MF_Heckintervall
      data DE_MF_Heckintervall: type=boolean
    IF_MF_Heckwaschen
      data DE_MF_Heckwaschen: type=boolean
    IF_MF_Innenraumbel
      data DE_MF_Innenraumbel: type=boolean
    IF_MF_Innenraumbel_Unterdrueck
      data DE_MF_Innenraumbel_Unterdrueck: type=boolean
    IF_MF_Motorweiterlauf
      data DE_MF_Motorweiterlauf: type=boolean
    IF_MF_Signalhorn
      data DE_MF_Signalhorn: type=boolean
    IF_MF_Tippwischen
      data DE_MF_Tippwischen: type=boolean
    IF_MF_Variante
      data DE_MF_Variante: type=uint8
    IF_MF_Wischerstufe_1
      data DE_MF_Wischerstufe_1: type=boolean
    IF_MF_Wischerstufe_2
      data DE_MF_Wischerstufe_2: type=boolean
    IF_MFG_01_BZ
      data DE_MFG_01_BZ: type=uint8
    IF_MFG_01_CRC
      data DE_MFG_01_CRC: type=uint8
    IF_MFK_ORUData
      data DE_MFK_ORUData: type=uint64
    IF_MFK_ORUDataIndex
      data DE_MFK_ORUDataIndex: type=uint8
    IF_MFL_CAN_ORUData
      data DE_MFL_CAN_ORUData: type=uint64
    IF_MFL_CAN_ORUDataIndex
      data DE_MFL_CAN_ORUDataIndex: type=uint8
    IF_MFL_Signalhorn
      data DE_MFL_Signalhorn: type=boolean
    IF_MO_Fahrbereitschaft
      data DE_MO_Fahrbereitschaft: type=uint8
    IF_MO_Fahrpedalrohwert_01
      data DE_MO_Fahrpedalrohwert_01: type=uint8
    IF_MO_HYB_Fahrbereitschaft
      data DE_MO_HYB_Fahrbereitschaft: type=boolean
    IF_MO_Kl_75
      data DE_MO_Kl_75: type=boolean
    IF_Motor_BEV_ORUData
      data DE_Motor_BEV_ORUData: type=uint64
    IF_Motor_BEV_ORUDataIndex
      data DE_Motor_BEV_ORUDataIndex: type=uint8
    IF_NM_BCM1_CAB_V15
      data DE_NM_BCM1_CAB_V15: type=uint32
    IF_NM_BCM1_Car_Wakeup
      data DE_NM_BCM1_Car_Wakeup: type=boolean
    IF_NM_BCM1_CBV_AWB
      data DE_NM_BCM1_CBV_AWB: type=boolean
    IF_NM_BCM1_CBV_CRI
      data DE_NM_BCM1_CBV_CRI: type=boolean
    IF_NM_BCM1_NM_aktiv_Applikation
      data DE_NM_BCM1_NM_aktiv_Applikation: type=boolean
    IF_NM_BCM1_NM_aktiv_Aussenlicht
      data DE_NM_BCM1_NM_aktiv_Aussenlicht: type=boolean
    IF_NM_BCM1_NM_aktiv_Diagnose
      data DE_NM_BCM1_NM_aktiv_Diagnose: type=boolean
    IF_NM_BCM1_NM_aktiv_DWA
      data DE_NM_BCM1_NM_aktiv_DWA: type=boolean
    IF_NM_BCM1_NM_aktiv_Funk
      data DE_NM_BCM1_NM_aktiv_Funk: type=boolean
    IF_NM_BCM1_NM_aktiv_Heizung
      data DE_NM_BCM1_NM_aktiv_Heizung: type=boolean
    IF_NM_BCM1_NM_aktiv_Innenlicht
      data DE_NM_BCM1_NM_aktiv_Innenlicht: type=boolean
    IF_NM_BCM1_NM_aktiv_Kessy
      data DE_NM_BCM1_NM_aktiv_Kessy: type=boolean
    IF_NM_BCM1_NM_aktiv_KL15
      data DE_NM_BCM1_NM_aktiv_KL15: type=boolean
    IF_NM_BCM1_NM_aktiv_Remotestart
      data DE_NM_BCM1_NM_aktiv_Remotestart: type=boolean
    IF_NM_BCM1_NM_aktiv_TK_geschlossen
      data DE_NM_BCM1_NM_aktiv_TK_geschlossen: type=boolean
    IF_NM_BCM1_NM_aktiv_Tmin
      data DE_NM_BCM1_NM_aktiv_Tmin: type=boolean
    IF_NM_BCM1_NM_aktiv_ZV
      data DE_NM_BCM1_NM_aktiv_ZV: type=boolean
    IF_NM_BCM1_NM_State
      data DE_NM_BCM1_NM_State: type=uint8
    IF_NM_BCM1_UDS_CC
      data DE_NM_BCM1_UDS_CC: type=boolean
    IF_NM_BCM1_Wakeup
      data DE_NM_BCM1_Wakeup: type=uint8
    IF_NM_eCall_NM_State
      data DE_NM_eCall_NM_State: type=uint8
    IF_NM_ELV_NM_State
      data DE_NM_ELV_NM_State: type=uint8
    IF_NM_Gateway_NM_State
      data DE_NM_Gateway_NM_State: type=uint8
    IF_NM_Kessy2_NM_State
      data DE_NM_Kessy2_NM_State: type=uint8
    IF_NM_Kessy_NM_State
      data DE_NM_Kessy_NM_State: type=uint8
    IF_NM_MFG_NM_State
      data DE_NM_MFG_NM_State: type=uint8
    IF_NM_NFC_TGS_NM_State
      data DE_NM_NFC_TGS_NM_State: type=uint8
    IF_NM_RSAD_HL_NM_State
      data DE_NM_RSAD_HL_NM_State: type=uint8
    IF_NM_RSAD_HR_NM_State
      data DE_NM_RSAD_HR_NM_State: type=uint8
    IF_NM_RSAD_IN_NM_State
      data DE_NM_RSAD_IN_NM_State: type=uint8
    IF_NM_RSAD_VL_NM_State
      data DE_NM_RSAD_VL_NM_State: type=uint8
    IF_NM_RSAD_VR_NM_State
      data DE_NM_RSAD_VR_NM_State: type=uint8
    IF_NM_WLC1_NM_State
      data DE_NM_WLC1_NM_State: type=uint8
    IF_NR1_ORUData
      data DE_NR1_ORUData: type=uint64
    IF_NR1_ORUDataIndex
      data DE_NR1_ORUDataIndex: type=uint8
    IF_NR2_ORUData
      data DE_NR2_ORUData: type=uint64
    IF_NR2_ORUDataIndex
      data DE_NR2_ORUDataIndex: type=uint8
    IF_NR3_ORUData
      data DE_NR3_ORUData: type=uint64
    IF_NR3_ORUDataIndex
      data DE_NR3_ORUDataIndex: type=uint8
    IF_NR4_ORUData
      data DE_NR4_ORUData: type=uint64
    IF_NR4_ORUDataIndex
      data DE_NR4_ORUDataIndex: type=uint8
    IF_NVEM_Abschaltstufe
      data DE_NVEM_Abschaltstufe: type=uint8
    IF_OBD_Driving_Cycle
      data DE_OBD_Driving_Cycle: type=boolean
    IF_OBD_Warm_Up_Cycle
      data DE_OBD_Warm_Up_Cycle: type=boolean
    IF_OCC_ORUData
      data DE_OCC_ORUData: type=uint64
    IF_OCC_ORUDataIndex
      data DE_OCC_ORUDataIndex: type=uint8
    IF_OPS_ComfortReadyStatus
      data DE_OPS_ComfortReadyStatus: type=uint8
    IF_OPS_DriverPresenceStatus
      data DE_OPS_DriverPresenceStatus: type=uint8
    IF_ORU_0001_BZ
      data DE_ORU_0001_BZ: type=uint8
    IF_ORU_0001_CRC
      data DE_ORU_0001_CRC: type=uint8
    IF_ORU_0003_BZ
      data DE_ORU_0003_BZ: type=uint8
    IF_ORU_0003_CRC
      data DE_ORU_0003_CRC: type=uint8
    IF_ORU_0006_BZ
      data DE_ORU_0006_BZ: type=uint8
    IF_ORU_0006_CRC
      data DE_ORU_0006_CRC: type=uint8
    IF_ORU_0009_BZ
      data DE_ORU_0009_BZ: type=uint8
    IF_ORU_0009_CRC
      data DE_ORU_0009_CRC: type=uint8
    IF_ORU_0013_BZ
      data DE_ORU_0013_BZ: type=uint8
    IF_ORU_0013_CRC
      data DE_ORU_0013_CRC: type=uint8
    IF_ORU_0015_BZ
      data DE_ORU_0015_BZ: type=uint8
    IF_ORU_0015_CRC
      data DE_ORU_0015_CRC: type=uint8
    IF_ORU_0016_BZ
      data DE_ORU_0016_BZ: type=uint8
    IF_ORU_0016_CRC
      data DE_ORU_0016_CRC: type=uint8
    IF_ORU_0019_BZ
      data DE_ORU_0019_BZ: type=uint8
    IF_ORU_0019_CRC
      data DE_ORU_0019_CRC: type=uint8
    IF_ORU_0023_BZ
      data DE_ORU_0023_BZ: type=uint8
    IF_ORU_0023_CRC
      data DE_ORU_0023_CRC: type=uint8
    IF_ORU_0036_BZ
      data DE_ORU_0036_BZ: type=uint8
    IF_ORU_0036_CRC
      data DE_ORU_0036_CRC: type=uint8
    IF_ORU_003D_BZ
      data DE_ORU_003D_BZ: type=uint8
    IF_ORU_003D_CRC
      data DE_ORU_003D_CRC: type=uint8
    IF_ORU_0042_BZ
      data DE_ORU_0042_BZ: type=uint8
    IF_ORU_0042_CRC
      data DE_ORU_0042_CRC: type=uint8
    IF_ORU_0044_BZ
      data DE_ORU_0044_BZ: type=uint8
    IF_ORU_0044_CRC
      data DE_ORU_0044_CRC: type=uint8
    IF_ORU_0048_BZ
      data DE_ORU_0048_BZ: type=uint8
    IF_ORU_0048_CRC
      data DE_ORU_0048_CRC: type=uint8
    IF_ORU_0051_BZ
      data DE_ORU_0051_BZ: type=uint8
    IF_ORU_0051_CRC
      data DE_ORU_0051_CRC: type=uint8
    IF_ORU_0052_BZ
      data DE_ORU_0052_BZ: type=uint8
    IF_ORU_0052_CRC
      data DE_ORU_0052_CRC: type=uint8
    IF_ORU_005B_BZ
      data DE_ORU_005B_BZ: type=uint8
    IF_ORU_005B_CRC
      data DE_ORU_005B_CRC: type=uint8
    IF_ORU_0069_BZ
      data DE_ORU_0069_BZ: type=uint8
    IF_ORU_0069_CRC
      data DE_ORU_0069_CRC: type=uint8
    IF_ORU_006A_BZ
      data DE_ORU_006A_BZ: type=uint8
    IF_ORU_006A_CRC
      data DE_ORU_006A_CRC: type=uint8
    IF_ORU_0076_BZ
      data DE_ORU_0076_BZ: type=uint8
    IF_ORU_0076_CRC
      data DE_ORU_0076_CRC: type=uint8
    IF_ORU_007A_BZ
      data DE_ORU_007A_BZ: type=uint8
    IF_ORU_007A_CRC
      data DE_ORU_007A_CRC: type=uint8
    IF_ORU_007E_BZ
      data DE_ORU_007E_BZ: type=uint8
    IF_ORU_007E_CRC
      data DE_ORU_007E_CRC: type=uint8
    IF_ORU_0082_BZ
      data DE_ORU_0082_BZ: type=uint8
    IF_ORU_0082_CRC
      data DE_ORU_0082_CRC: type=uint8
    IF_ORU_008C_BZ
      data DE_ORU_008C_BZ: type=uint8
    IF_ORU_008C_CRC
      data DE_ORU_008C_CRC: type=uint8
    IF_ORU_00A5_BZ
      data DE_ORU_00A5_BZ: type=uint8
    IF_ORU_00A5_CRC
      data DE_ORU_00A5_CRC: type=uint8
    IF_ORU_00BB_BZ
      data DE_ORU_00BB_BZ: type=uint8
    IF_ORU_00BB_CRC
      data DE_ORU_00BB_CRC: type=uint8
    IF_ORU_00BC_BZ
      data DE_ORU_00BC_BZ: type=uint8
    IF_ORU_00BC_CRC
      data DE_ORU_00BC_CRC: type=uint8
    IF_ORU_00C6_BZ
      data DE_ORU_00C6_BZ: type=uint8
    IF_ORU_00C6_CRC
      data DE_ORU_00C6_CRC: type=uint8
    IF_ORU_00CE_BZ
      data DE_ORU_00CE_BZ: type=uint8
    IF_ORU_00CE_CRC
      data DE_ORU_00CE_CRC: type=uint8
    IF_ORU_00D6_BZ
      data DE_ORU_00D6_BZ: type=uint8
    IF_ORU_00D6_CRC
      data DE_ORU_00D6_CRC: type=uint8
    IF_ORU_00D7_BZ
      data DE_ORU_00D7_BZ: type=uint8
    IF_ORU_00D7_CRC
      data DE_ORU_00D7_CRC: type=uint8
    IF_ORU_0631_BZ
      data DE_ORU_0631_BZ: type=uint8
    IF_ORU_0631_CRC
      data DE_ORU_0631_CRC: type=uint8
    IF_ORU_8105_BZ
      data DE_ORU_8105_BZ: type=uint8
    IF_ORU_8105_CRC
      data DE_ORU_8105_CRC: type=uint8
    IF_ORU_8109_BZ
      data DE_ORU_8109_BZ: type=uint8
    IF_ORU_8109_CRC
      data DE_ORU_8109_CRC: type=uint8
    IF_ORU_810A_BZ
      data DE_ORU_810A_BZ: type=uint8
    IF_ORU_810A_CRC
      data DE_ORU_810A_CRC: type=uint8
    IF_ORU_810B_BZ
      data DE_ORU_810B_BZ: type=uint8
    IF_ORU_810B_CRC
      data DE_ORU_810B_CRC: type=uint8
    IF_ORU_810C_BZ
      data DE_ORU_810C_BZ: type=uint8
    IF_ORU_810C_CRC
      data DE_ORU_810C_CRC: type=uint8
    IF_ORU_8133_BZ
      data DE_ORU_8133_BZ: type=uint8
    IF_ORU_8133_CRC
      data DE_ORU_8133_CRC: type=uint8
    IF_ORU_8134_BZ
      data DE_ORU_8134_BZ: type=uint8
    IF_ORU_8134_CRC
      data DE_ORU_8134_CRC: type=uint8
    IF_ORU_8179_BZ
      data DE_ORU_8179_BZ: type=uint8
    IF_ORU_8179_CRC
      data DE_ORU_8179_CRC: type=uint8
    IF_ORU_817B_BZ
      data DE_ORU_817B_BZ: type=uint8
    IF_ORU_817B_CRC
      data DE_ORU_817B_CRC: type=uint8
    IF_ORU_8181_BZ
      data DE_ORU_8181_BZ: type=uint8
    IF_ORU_8181_CRC
      data DE_ORU_8181_CRC: type=uint8
    IF_ORU_AP_Mode
      data DE_ORU_AP_Mode: type=uint8
    IF_ORU_DiagAddress
      data DE_ORU_DiagAddress: type=uint16
    IF_ORU_Status
      data DE_ORU_Status: type=uint8
    IF_ORUG01_01_BZ
      data DE_ORUG01_01_BZ: type=uint8
    IF_ORUG01_01_CRC
      data DE_ORUG01_01_CRC: type=uint8
    IF_ORUG02_01_BZ
      data DE_ORUG02_01_BZ: type=uint8
    IF_ORUG02_01_CRC
      data DE_ORUG02_01_CRC: type=uint8
    IF_ORUG1_HVReleased
      data DE_ORUG1_HVReleased: type=boolean
    IF_ORUG1_TargetRelease
      data DE_ORUG1_TargetRelease: type=uint16
    IF_ORUG2_GuardInfo
      data DE_ORUG2_GuardInfo: type=uint16
    IF_ORUG2_GuardState
      data DE_ORUG2_GuardState: type=uint8
    IF_ORUG2_TargetRelease
      data DE_ORUG2_TargetRelease: type=uint16
    IF_ORUG2_TorqueLock
      data DE_ORUG2_TorqueLock: type=uint8
    IF_PAO_OFF_Anf_invers
      data DE_PAO_OFF_Anf_invers: type=uint8
    IF_PAO_ON_Anf_invers
      data DE_PAO_ON_Anf_invers: type=uint8
    IF_Parken_aktives_System_02
      data DE_Parken_aktives_System_02: type=uint8
    IF_Perso_Kontonummer
      data DE_Perso_Kontonummer: type=uint8
    IF_Perso_Status
      data DE_Perso_Status: type=uint8
    IF_Perso_Steuerung
      data DE_Perso_Steuerung: type=uint8
    IF_Perso_Steuerungsparameter
      data DE_Perso_Steuerungsparameter: type=uint8
    IF_PreCrash_BFS_Pneumatik_ansteuern
      data DE_PreCrash_BFS_Pneumatik_ansteuern: type=boolean
    IF_PreCrash_Fenster_schliessen
      data DE_PreCrash_Fenster_schliessen: type=boolean
    IF_PreCrash_FS_Pneumatik_ansteuern
      data DE_PreCrash_FS_Pneumatik_ansteuern: type=boolean
    IF_RCTA_Kritikalitaetslevel_links
      data DE_RCTA_Kritikalitaetslevel_links: type=uint8
    IF_RCTA_Kritikalitaetslevel_rechts
      data DE_RCTA_Kritikalitaetslevel_rechts: type=uint8
    IF_RGB_Slave_01_IntErrorNvm
      data DE_RGB_Slave_01_IntErrorNvm: type=uint8
    IF_RGB_Slave_01_IntErrorRam
      data DE_RGB_Slave_01_IntErrorRam: type=uint8
    IF_RGB_Slave_01_IntErrorRom
      data DE_RGB_Slave_01_IntErrorRom: type=uint8
    IF_RGB_Slave_01_LedBlauOl
      data DE_RGB_Slave_01_LedBlauOl: type=uint8
    IF_RGB_Slave_01_LedBlauStg
      data DE_RGB_Slave_01_LedBlauStg: type=uint8
    IF_RGB_Slave_01_LedGruenOl
      data DE_RGB_Slave_01_LedGruenOl: type=uint8
    IF_RGB_Slave_01_LedGruenStg
      data DE_RGB_Slave_01_LedGruenStg: type=uint8
    IF_RGB_Slave_01_LedRotOl
      data DE_RGB_Slave_01_LedRotOl: type=uint8
    IF_RGB_Slave_01_LedRotStg
      data DE_RGB_Slave_01_LedRotStg: type=uint8
    IF_RGB_Slave_01_ResponseError
      data DE_RGB_Slave_01_ResponseError: type=boolean
    IF_RGB_Slave_01_TempState
      data DE_RGB_Slave_01_TempState: type=uint8
    IF_RGB_Slave_02_IntErrorNvm
      data DE_RGB_Slave_02_IntErrorNvm: type=uint8
    IF_RGB_Slave_02_IntErrorRam
      data DE_RGB_Slave_02_IntErrorRam: type=uint8
    IF_RGB_Slave_02_IntErrorRom
      data DE_RGB_Slave_02_IntErrorRom: type=uint8
    IF_RGB_Slave_02_LedBlauOl
      data DE_RGB_Slave_02_LedBlauOl: type=uint8
    IF_RGB_Slave_02_LedBlauStg
      data DE_RGB_Slave_02_LedBlauStg: type=uint8
    IF_RGB_Slave_02_LedGruenOl
      data DE_RGB_Slave_02_LedGruenOl: type=uint8
    IF_RGB_Slave_02_LedGruenStg
      data DE_RGB_Slave_02_LedGruenStg: type=uint8
    IF_RGB_Slave_02_LedRotOl
      data DE_RGB_Slave_02_LedRotOl: type=uint8
    IF_RGB_Slave_02_LedRotStg
      data DE_RGB_Slave_02_LedRotStg: type=uint8
    IF_RGB_Slave_02_ResponseError
      data DE_RGB_Slave_02_ResponseError: type=boolean
    IF_RGB_Slave_02_TempState
      data DE_RGB_Slave_02_TempState: type=uint8
    IF_RGB_Slave_03_IntErrorNvm
      data DE_RGB_Slave_03_IntErrorNvm: type=uint8
    IF_RGB_Slave_03_IntErrorRam
      data DE_RGB_Slave_03_IntErrorRam: type=uint8
    IF_RGB_Slave_03_IntErrorRom
      data DE_RGB_Slave_03_IntErrorRom: type=uint8
    IF_RGB_Slave_03_LedBlauOl
      data DE_RGB_Slave_03_LedBlauOl: type=uint8
    IF_RGB_Slave_03_LedBlauStg
      data DE_RGB_Slave_03_LedBlauStg: type=uint8
    IF_RGB_Slave_03_LedGruenOl
      data DE_RGB_Slave_03_LedGruenOl: type=uint8
    IF_RGB_Slave_03_LedGruenStg
      data DE_RGB_Slave_03_LedGruenStg: type=uint8
    IF_RGB_Slave_03_LedRotOl
      data DE_RGB_Slave_03_LedRotOl: type=uint8
    IF_RGB_Slave_03_LedRotStg
      data DE_RGB_Slave_03_LedRotStg: type=uint8
    IF_RGB_Slave_03_ResponseError
      data DE_RGB_Slave_03_ResponseError: type=boolean
    IF_RGB_Slave_03_TempState
      data DE_RGB_Slave_03_TempState: type=uint8
    IF_RGB_Slave_04_IntErrorNvm
      data DE_RGB_Slave_04_IntErrorNvm: type=uint8
    IF_RGB_Slave_04_IntErrorRam
      data DE_RGB_Slave_04_IntErrorRam: type=uint8
    IF_RGB_Slave_04_IntErrorRom
      data DE_RGB_Slave_04_IntErrorRom: type=uint8
    IF_RGB_Slave_04_LedBlauOl
      data DE_RGB_Slave_04_LedBlauOl: type=uint8
    IF_RGB_Slave_04_LedBlauStg
      data DE_RGB_Slave_04_LedBlauStg: type=uint8
    IF_RGB_Slave_04_LedGruenOl
      data DE_RGB_Slave_04_LedGruenOl: type=uint8
    IF_RGB_Slave_04_LedGruenStg
      data DE_RGB_Slave_04_LedGruenStg: type=uint8
    IF_RGB_Slave_04_LedRotOl
      data DE_RGB_Slave_04_LedRotOl: type=uint8
    IF_RGB_Slave_04_LedRotStg
      data DE_RGB_Slave_04_LedRotStg: type=uint8
    IF_RGB_Slave_04_ResponseError
      data DE_RGB_Slave_04_ResponseError: type=boolean
    IF_RGB_Slave_04_TempState
      data DE_RGB_Slave_04_TempState: type=uint8
    IF_RGB_Slave_05_IntErrorNvm
      data DE_RGB_Slave_05_IntErrorNvm: type=uint8
    IF_RGB_Slave_05_IntErrorRam
      data DE_RGB_Slave_05_IntErrorRam: type=uint8
    IF_RGB_Slave_05_IntErrorRom
      data DE_RGB_Slave_05_IntErrorRom: type=uint8
    IF_RGB_Slave_05_LedBlauOl
      data DE_RGB_Slave_05_LedBlauOl: type=uint8
    IF_RGB_Slave_05_LedBlauStg
      data DE_RGB_Slave_05_LedBlauStg: type=uint8
    IF_RGB_Slave_05_LedGruenOl
      data DE_RGB_Slave_05_LedGruenOl: type=uint8
    IF_RGB_Slave_05_LedGruenStg
      data DE_RGB_Slave_05_LedGruenStg: type=uint8
    IF_RGB_Slave_05_LedRotOl
      data DE_RGB_Slave_05_LedRotOl: type=uint8
    IF_RGB_Slave_05_LedRotStg
      data DE_RGB_Slave_05_LedRotStg: type=uint8
    IF_RGB_Slave_05_ResponseError
      data DE_RGB_Slave_05_ResponseError: type=boolean
    IF_RGB_Slave_05_TempState
      data DE_RGB_Slave_05_TempState: type=uint8
    IF_RGB_Slave_06_IntErrorNvm
      data DE_RGB_Slave_06_IntErrorNvm: type=uint8
    IF_RGB_Slave_06_IntErrorRam
      data DE_RGB_Slave_06_IntErrorRam: type=uint8
    IF_RGB_Slave_06_IntErrorRom
      data DE_RGB_Slave_06_IntErrorRom: type=uint8
    IF_RGB_Slave_06_LedBlauOl
      data DE_RGB_Slave_06_LedBlauOl: type=uint8
    IF_RGB_Slave_06_LedBlauStg
      data DE_RGB_Slave_06_LedBlauStg: type=uint8
    IF_RGB_Slave_06_LedGruenOl
      data DE_RGB_Slave_06_LedGruenOl: type=uint8
    IF_RGB_Slave_06_LedGruenStg
      data DE_RGB_Slave_06_LedGruenStg: type=uint8
    IF_RGB_Slave_06_LedRotOl
      data DE_RGB_Slave_06_LedRotOl: type=uint8
    IF_RGB_Slave_06_LedRotStg
      data DE_RGB_Slave_06_LedRotStg: type=uint8
    IF_RGB_Slave_06_ResponseError
      data DE_RGB_Slave_06_ResponseError: type=boolean
    IF_RGB_Slave_06_TempState
      data DE_RGB_Slave_06_TempState: type=uint8
    IF_RGB_Slave_07_IntErrorNvm
      data DE_RGB_Slave_07_IntErrorNvm: type=uint8
    IF_RGB_Slave_07_IntErrorRam
      data DE_RGB_Slave_07_IntErrorRam: type=uint8
    IF_RGB_Slave_07_IntErrorRom
      data DE_RGB_Slave_07_IntErrorRom: type=uint8
    IF_RGB_Slave_07_LedBlauOl
      data DE_RGB_Slave_07_LedBlauOl: type=uint8
    IF_RGB_Slave_07_LedBlauStg
      data DE_RGB_Slave_07_LedBlauStg: type=uint8
    IF_RGB_Slave_07_LedGruenOl
      data DE_RGB_Slave_07_LedGruenOl: type=uint8
    IF_RGB_Slave_07_LedGruenStg
      data DE_RGB_Slave_07_LedGruenStg: type=uint8
    IF_RGB_Slave_07_LedRotOl
      data DE_RGB_Slave_07_LedRotOl: type=uint8
    IF_RGB_Slave_07_LedRotStg
      data DE_RGB_Slave_07_LedRotStg: type=uint8
    IF_RGB_Slave_07_ResponseError
      data DE_RGB_Slave_07_ResponseError: type=boolean
    IF_RGB_Slave_07_TempState
      data DE_RGB_Slave_07_TempState: type=uint8
    IF_RGB_Slave_08_IntErrorNvm
      data DE_RGB_Slave_08_IntErrorNvm: type=uint8
    IF_RGB_Slave_08_IntErrorRam
      data DE_RGB_Slave_08_IntErrorRam: type=uint8
    IF_RGB_Slave_08_IntErrorRom
      data DE_RGB_Slave_08_IntErrorRom: type=uint8
    IF_RGB_Slave_08_LedBlauOl
      data DE_RGB_Slave_08_LedBlauOl: type=uint8
    IF_RGB_Slave_08_LedBlauStg
      data DE_RGB_Slave_08_LedBlauStg: type=uint8
    IF_RGB_Slave_08_LedGruenOl
      data DE_RGB_Slave_08_LedGruenOl: type=uint8
    IF_RGB_Slave_08_LedGruenStg
      data DE_RGB_Slave_08_LedGruenStg: type=uint8
    IF_RGB_Slave_08_LedRotOl
      data DE_RGB_Slave_08_LedRotOl: type=uint8
    IF_RGB_Slave_08_LedRotStg
      data DE_RGB_Slave_08_LedRotStg: type=uint8
    IF_RGB_Slave_08_ResponseError
      data DE_RGB_Slave_08_ResponseError: type=boolean
    IF_RGB_Slave_08_TempState
      data DE_RGB_Slave_08_TempState: type=uint8
    IF_RGB_Slave_09_IntErrorNvm
      data DE_RGB_Slave_09_IntErrorNvm: type=uint8
    IF_RGB_Slave_09_IntErrorRam
      data DE_RGB_Slave_09_IntErrorRam: type=uint8
    IF_RGB_Slave_09_IntErrorRom
      data DE_RGB_Slave_09_IntErrorRom: type=uint8
    IF_RGB_Slave_09_LedBlauOl
      data DE_RGB_Slave_09_LedBlauOl: type=uint8
    IF_RGB_Slave_09_LedBlauStg
      data DE_RGB_Slave_09_LedBlauStg: type=uint8
    IF_RGB_Slave_09_LedGruenOl
      data DE_RGB_Slave_09_LedGruenOl: type=uint8
    IF_RGB_Slave_09_LedGruenStg
      data DE_RGB_Slave_09_LedGruenStg: type=uint8
    IF_RGB_Slave_09_LedRotOl
      data DE_RGB_Slave_09_LedRotOl: type=uint8
    IF_RGB_Slave_09_LedRotStg
      data DE_RGB_Slave_09_LedRotStg: type=uint8
    IF_RGB_Slave_09_ResponseError
      data DE_RGB_Slave_09_ResponseError: type=boolean
    IF_RGB_Slave_09_TempState
      data DE_RGB_Slave_09_TempState: type=uint8
    IF_RGB_Slave_10_IntErrorNvm
      data DE_RGB_Slave_10_IntErrorNvm: type=uint8
    IF_RGB_Slave_10_IntErrorRam
      data DE_RGB_Slave_10_IntErrorRam: type=uint8
    IF_RGB_Slave_10_IntErrorRom
      data DE_RGB_Slave_10_IntErrorRom: type=uint8
    IF_RGB_Slave_10_LedBlauOl
      data DE_RGB_Slave_10_LedBlauOl: type=uint8
    IF_RGB_Slave_10_LedBlauStg
      data DE_RGB_Slave_10_LedBlauStg: type=uint8
    IF_RGB_Slave_10_LedGruenOl
      data DE_RGB_Slave_10_LedGruenOl: type=uint8
    IF_RGB_Slave_10_LedGruenStg
      data DE_RGB_Slave_10_LedGruenStg: type=uint8
    IF_RGB_Slave_10_LedRotOl
      data DE_RGB_Slave_10_LedRotOl: type=uint8
    IF_RGB_Slave_10_LedRotStg
      data DE_RGB_Slave_10_LedRotStg: type=uint8
    IF_RGB_Slave_10_ResponseError
      data DE_RGB_Slave_10_ResponseError: type=boolean
    IF_RGB_Slave_10_TempState
      data DE_RGB_Slave_10_TempState: type=uint8
    IF_RGB_Slave_11_IntErrorNvm
      data DE_RGB_Slave_11_IntErrorNvm: type=uint8
    IF_RGB_Slave_11_IntErrorRam
      data DE_RGB_Slave_11_IntErrorRam: type=uint8
    IF_RGB_Slave_11_IntErrorRom
      data DE_RGB_Slave_11_IntErrorRom: type=uint8
    IF_RGB_Slave_11_LedBlauOl
      data DE_RGB_Slave_11_LedBlauOl: type=uint8
    IF_RGB_Slave_11_LedBlauStg
      data DE_RGB_Slave_11_LedBlauStg: type=uint8
    IF_RGB_Slave_11_LedGruenOl
      data DE_RGB_Slave_11_LedGruenOl: type=uint8
    IF_RGB_Slave_11_LedGruenStg
      data DE_RGB_Slave_11_LedGruenStg: type=uint8
    IF_RGB_Slave_11_LedRotOl
      data DE_RGB_Slave_11_LedRotOl: type=uint8
    IF_RGB_Slave_11_LedRotStg
      data DE_RGB_Slave_11_LedRotStg: type=uint8
    IF_RGB_Slave_11_ResponseError
      data DE_RGB_Slave_11_ResponseError: type=boolean
    IF_RGB_Slave_11_TempState
      data DE_RGB_Slave_11_TempState: type=uint8
    IF_RGB_Slave_12_IntErrorNvm
      data DE_RGB_Slave_12_IntErrorNvm: type=uint8
    IF_RGB_Slave_12_IntErrorRam
      data DE_RGB_Slave_12_IntErrorRam: type=uint8
    IF_RGB_Slave_12_IntErrorRom
      data DE_RGB_Slave_12_IntErrorRom: type=uint8
    IF_RGB_Slave_12_LedBlauOl
      data DE_RGB_Slave_12_LedBlauOl: type=uint8
    IF_RGB_Slave_12_LedBlauStg
      data DE_RGB_Slave_12_LedBlauStg: type=uint8
    IF_RGB_Slave_12_LedGruenOl
      data DE_RGB_Slave_12_LedGruenOl: type=uint8
    IF_RGB_Slave_12_LedGruenStg
      data DE_RGB_Slave_12_LedGruenStg: type=uint8
    IF_RGB_Slave_12_LedRotOl
      data DE_RGB_Slave_12_LedRotOl: type=uint8
    IF_RGB_Slave_12_LedRotStg
      data DE_RGB_Slave_12_LedRotStg: type=uint8
    IF_RGB_Slave_12_ResponseError
      data DE_RGB_Slave_12_ResponseError: type=boolean
    IF_RGB_Slave_12_TempState
      data DE_RGB_Slave_12_TempState: type=uint8
    IF_RGB_Slave_13_IntErrorNvm
      data DE_RGB_Slave_13_IntErrorNvm: type=uint8
    IF_RGB_Slave_13_IntErrorRam
      data DE_RGB_Slave_13_IntErrorRam: type=uint8
    IF_RGB_Slave_13_IntErrorRom
      data DE_RGB_Slave_13_IntErrorRom: type=uint8
    IF_RGB_Slave_13_LedBlauOl
      data DE_RGB_Slave_13_LedBlauOl: type=uint8
    IF_RGB_Slave_13_LedBlauStg
      data DE_RGB_Slave_13_LedBlauStg: type=uint8
    IF_RGB_Slave_13_LedGruenOl
      data DE_RGB_Slave_13_LedGruenOl: type=uint8
    IF_RGB_Slave_13_LedGruenStg
      data DE_RGB_Slave_13_LedGruenStg: type=uint8
    IF_RGB_Slave_13_LedRotOl
      data DE_RGB_Slave_13_LedRotOl: type=uint8
    IF_RGB_Slave_13_LedRotStg
      data DE_RGB_Slave_13_LedRotStg: type=uint8
    IF_RGB_Slave_13_ResponseError
      data DE_RGB_Slave_13_ResponseError: type=boolean
    IF_RGB_Slave_13_TempState
      data DE_RGB_Slave_13_TempState: type=uint8
    IF_RGB_Slave_14_IntErrorNvm
      data DE_RGB_Slave_14_IntErrorNvm: type=uint8
    IF_RGB_Slave_14_IntErrorRam
      data DE_RGB_Slave_14_IntErrorRam: type=uint8
    IF_RGB_Slave_14_IntErrorRom
      data DE_RGB_Slave_14_IntErrorRom: type=uint8
    IF_RGB_Slave_14_LedBlauOl
      data DE_RGB_Slave_14_LedBlauOl: type=uint8
    IF_RGB_Slave_14_LedBlauStg
      data DE_RGB_Slave_14_LedBlauStg: type=uint8
    IF_RGB_Slave_14_LedGruenOl
      data DE_RGB_Slave_14_LedGruenOl: type=uint8
    IF_RGB_Slave_14_LedGruenStg
      data DE_RGB_Slave_14_LedGruenStg: type=uint8
    IF_RGB_Slave_14_LedRotOl
      data DE_RGB_Slave_14_LedRotOl: type=uint8
    IF_RGB_Slave_14_LedRotStg
      data DE_RGB_Slave_14_LedRotStg: type=uint8
    IF_RGB_Slave_14_ResponseError
      data DE_RGB_Slave_14_ResponseError: type=boolean
    IF_RGB_Slave_14_TempState
      data DE_RGB_Slave_14_TempState: type=uint8
    IF_RGB_Slave_15_IntErrorNvm
      data DE_RGB_Slave_15_IntErrorNvm: type=uint8
    IF_RGB_Slave_15_IntErrorRam
      data DE_RGB_Slave_15_IntErrorRam: type=uint8
    IF_RGB_Slave_15_IntErrorRom
      data DE_RGB_Slave_15_IntErrorRom: type=uint8
    IF_RGB_Slave_15_LedBlauOl
      data DE_RGB_Slave_15_LedBlauOl: type=uint8
    IF_RGB_Slave_15_LedBlauStg
      data DE_RGB_Slave_15_LedBlauStg: type=uint8
    IF_RGB_Slave_15_LedGruenOl
      data DE_RGB_Slave_15_LedGruenOl: type=uint8
    IF_RGB_Slave_15_LedGruenStg
      data DE_RGB_Slave_15_LedGruenStg: type=uint8
    IF_RGB_Slave_15_LedRotOl
      data DE_RGB_Slave_15_LedRotOl: type=uint8
    IF_RGB_Slave_15_LedRotStg
      data DE_RGB_Slave_15_LedRotStg: type=uint8
    IF_RGB_Slave_15_ResponseError
      data DE_RGB_Slave_15_ResponseError: type=boolean
    IF_RGB_Slave_15_TempState
      data DE_RGB_Slave_15_TempState: type=uint8
    IF_RHP_Fahrzeughupe_Anf
      data DE_RHP_Fahrzeughupe_Anf: type=boolean
    IF_RLS_02_BZ
      data DE_RLS_02_BZ: type=uint8
    IF_RLS_02_CRC
      data DE_RLS_02_CRC: type=uint8
    IF_RLS_CRC
      data DE_RLS_CRC: type=uint8
    IF_RLS_Qualifizierungsbit
      data DE_RLS_Qualifizierungsbit: type=boolean
    IF_RLS_ResponseError
      data DE_RLS_ResponseError: type=boolean
    IF_RLS_Vorfeldhelligkeit_Boost
      data DE_RLS_Vorfeldhelligkeit_Boost: type=uint8
    IF_RLS_Zaehler
      data DE_RLS_Zaehler: type=uint8
    IF_RS_AdaptierungError
      data DE_RS_AdaptierungError: type=boolean
    IF_RS_defekt
      data DE_RS_defekt: type=boolean
    IF_RS_Error
      data DE_RS_Error: type=boolean
    IF_RS_Regenfahrlicht
      data DE_RS_Regenfahrlicht: type=boolean
    IF_RS_Regenmenge
      data DE_RS_Regenmenge: type=uint8
    IF_RS_Schwall
      data DE_RS_Schwall: type=boolean
    IF_RS_Verbau
      data DE_RS_Verbau: type=boolean
    IF_RS_Verglasung_schliessen
      data DE_RS_Verglasung_schliessen: type=boolean
    IF_RS_versParklage_Wischer
      data DE_RS_versParklage_Wischer: type=boolean
    IF_RS_Wischergeschwindigkeit
      data DE_RS_Wischergeschwindigkeit: type=uint8
    IF_RV_Reinigung_Anf
      data DE_RV_Reinigung_Anf: type=boolean
    IF_SAL_01_BZ
      data DE_SAL_01_BZ: type=uint8
    IF_SAL_01_CRC
      data DE_SAL_01_CRC: type=uint8
    IF_SAL_Ambex_CH_state
      data DE_SAL_Ambex_CH_state: type=uint8
    IF_SAL_Ambex_CH_time
      data DE_SAL_Ambex_CH_time: type=uint8
    IF_SAL_Ambex_LH_state
      data DE_SAL_Ambex_LH_state: type=uint8
    IF_SAL_Ambex_LH_time
      data DE_SAL_Ambex_LH_time: type=uint8
    IF_SAL_Ambex_Lichtsensor_ch_lh_ein
      data DE_SAL_Ambex_Lichtsensor_ch_lh_ein: type=boolean
    IF_SAL_Blinkerzyklus_L
      data DE_SAL_Blinkerzyklus_L: type=boolean
    IF_SAL_Blinkerzyklus_R
      data DE_SAL_Blinkerzyklus_R: type=boolean
    IF_SAL_BLK_L_Anf
      data DE_SAL_BLK_L_Anf: type=boolean
    IF_SAL_BLK_R_Anf
      data DE_SAL_BLK_R_Anf: type=boolean
    IF_SAL_Bremszyklus
      data DE_SAL_Bremszyklus: type=boolean
    IF_SAL_BRL_Anf
      data DE_SAL_BRL_Anf: type=boolean
    IF_SAL_CH_Anf
      data DE_SAL_CH_Anf: type=boolean
    IF_SAL_HGB_Anf
      data DE_SAL_HGB_Anf: type=boolean
    IF_SAL_Kl_15
      data DE_SAL_Kl_15: type=boolean
    IF_SAL_Kl_15_vFzg
      data DE_SAL_Kl_15_vFzg: type=boolean
    IF_SAL_Kl_15_vFzg_S
      data DE_SAL_Kl_15_vFzg_S: type=boolean
    IF_SAL_KL_50
      data DE_SAL_KL_50: type=boolean
    IF_SAL_KL_50_5s
      data DE_SAL_KL_50_5s: type=boolean
    IF_SAL_Kl_75
      data DE_SAL_Kl_75: type=boolean
    IF_SAL_KL_75_vFzg
      data DE_SAL_KL_75_vFzg: type=boolean
    IF_SAL_KL_75a
      data DE_SAL_KL_75a: type=boolean
    IF_SAL_KL_75a_vFzg
      data DE_SAL_KL_75a_vFzg: type=boolean
    IF_SAL_KZL_Anf
      data DE_SAL_KZL_Anf: type=boolean
    IF_SAL_LDS_Abblendlicht_Anf
      data DE_SAL_LDS_Abblendlicht_Anf: type=boolean
    IF_SAL_LDS_Assistenzfahrlicht_Anf
      data DE_SAL_LDS_Assistenzfahrlicht_Anf: type=boolean
    IF_SAL_LDS_Nullstellung_Anf
      data DE_SAL_LDS_Nullstellung_Anf: type=boolean
    IF_SAL_LDS_Standlicht_Anf
      data DE_SAL_LDS_Standlicht_Anf: type=boolean
    IF_SAL_LH_Anf
      data DE_SAL_LH_Anf: type=boolean
    IF_SAL_li1_Blinker_Status
      data DE_SAL_li1_Blinker_Status: type=boolean
    IF_SAL_NSL_Anf
      data DE_SAL_NSL_Anf: type=boolean
    IF_SAL_PL_L_Anf
      data DE_SAL_PL_L_Anf: type=boolean
    IF_SAL_PL_R_Anf
      data DE_SAL_PL_R_Anf: type=boolean
    IF_SAL_re1_Blinker_Status
      data DE_SAL_re1_Blinker_Status: type=boolean
    IF_SAL_RFL_Anf
      data DE_SAL_RFL_Anf: type=boolean
    IF_SAL_SL_Anf
      data DE_SAL_SL_Anf: type=boolean
    IF_SAL_WBT_Bel
      data DE_SAL_WBT_Bel: type=boolean
    IF_SAM_01_BZ
      data DE_SAM_01_BZ: type=uint8
    IF_SAM_01_CRC
      data DE_SAM_01_CRC: type=uint8
    IF_SAM_Fehler_DC_LWR
      data DE_SAM_Fehler_DC_LWR: type=boolean
    IF_SAM_ORUData
      data DE_SAM_ORUData: type=uint64
    IF_SAM_ORUDataIndex
      data DE_SAM_ORUDataIndex: type=uint8
    IF_SC_PAO_OFF_Anf
      data DE_SC_PAO_OFF_Anf: type=uint8
    IF_SC_PAO_ON_Anf
      data DE_SC_PAO_ON_Anf: type=uint8
    IF_Schluesselnr_Personalisierung
      data DE_Schluesselnr_Personalisierung: type=uint8
    IF_Servicestellung_Wischer
      data DE_Servicestellung_Wischer: type=boolean
    IF_SI_BUS_01
      data DE_SI_BUS_01: type=boolean
    IF_SI_BUS_02
      data DE_SI_BUS_02: type=boolean
    IF_SI_BUS_03
      data DE_SI_BUS_03: type=boolean
    IF_SI_BUS_05
      data DE_SI_BUS_05: type=boolean
    IF_SI_BUS_06
      data DE_SI_BUS_06: type=boolean
    IF_SI_BUS_09
      data DE_SI_BUS_09: type=boolean
    IF_SI_BUS_10
      data DE_SI_BUS_10: type=boolean
    IF_SI_BUS_13
      data DE_SI_BUS_13: type=boolean
    IF_SI_BUS_14
      data DE_SI_BUS_14: type=boolean
    IF_SI_Bus_Identifikation
      data DE_SI_Bus_Identifikation: type=uint8
    IF_SI_NWDF
      data DE_SI_NWDF: type=boolean
    IF_SI_NWDF_gueltig
      data DE_SI_NWDF_gueltig: type=boolean
    IF_SI_P_Mode
      data DE_SI_P_Mode: type=boolean
    IF_SI_P_Mode_gueltig
      data DE_SI_P_Mode_gueltig: type=boolean
    IF_SI_QRS_Mode
      data DE_SI_QRS_Mode: type=boolean
    IF_SI_T_Mode
      data DE_SI_T_Mode: type=boolean
    IF_SI_T_Schutz
      data DE_SI_T_Schutz: type=boolean
    IF_SIL_Stufe_LED_li
      data DE_SIL_Stufe_LED_li: type=uint8
    IF_SIL_Stufe_LED_re
      data DE_SIL_Stufe_LED_re: type=uint8
    IF_SitzMem_HBFS_ORUData
      data DE_SitzMem_HBFS_ORUData: type=uint64
    IF_SitzMem_HBFS_ORUDataIndex
      data DE_SitzMem_HBFS_ORUDataIndex: type=uint8
    IF_SitzMem_HFS_ORUData
      data DE_SitzMem_HFS_ORUData: type=uint64
    IF_SitzMem_HFS_ORUDataIndex
      data DE_SitzMem_HFS_ORUDataIndex: type=uint8
    IF_SitzMemo_BFS_ORUData
      data DE_SitzMemo_BFS_ORUData: type=uint64
    IF_SitzMemo_BFS_ORUDataIndex
      data DE_SitzMemo_BFS_ORUDataIndex: type=uint8
    IF_SitzMemo_FS_ORUData
      data DE_SitzMemo_FS_ORUData: type=uint64
    IF_SitzMemo_FS_ORUDataIndex
      data DE_SitzMemo_FS_ORUDataIndex: type=uint8
    IF_SL2_APS_Taster
      data DE_SL2_APS_Taster: type=uint8
    IF_SL2_FAS_Profile_Taster
      data DE_SL2_FAS_Profile_Taster: type=uint8
    IF_SL2_ResponseError
      data DE_SL2_ResponseError: type=boolean
    IF_SL2_StatusSchalterleiste
      data DE_SL2_StatusSchalterleiste: type=uint8
    IF_SMLS_01_BZ
      data DE_SMLS_01_BZ: type=uint8
    IF_SMLS_01_CRC
      data DE_SMLS_01_CRC: type=uint8
    IF_SMLS_alt
      data DE_SMLS_alt: type=boolean
    IF_SMLS_Hupe
      data DE_SMLS_Hupe: type=boolean
    IF_SMLS_ORUData
      data DE_SMLS_ORUData: type=uint64
    IF_SMLS_ORUDataIndex
      data DE_SMLS_ORUDataIndex: type=uint8
    IF_SOK_FoD_BCM1_Req_Challenge
      data DE_SOK_FoD_BCM1_Req_Challenge: type=uint64
    IF_SOK_FoD_BCM1_Resp_Challenge
      data DE_SOK_FoD_BCM1_Resp_Challenge: type=uint64
    IF_SOK_KST_Challenge
      data DE_SOK_KST_Challenge: type=uint64
    IF_SOK_ungeschuetzte_Zeit
      data DE_SOK_ungeschuetzte_Zeit: type=uint64
    IF_SOK_ZV_HBFS_Challenge
      data DE_SOK_ZV_HBFS_Challenge: type=uint64
    IF_SOK_ZV_HFS_Challenge
      data DE_SOK_ZV_HFS_Challenge: type=uint64
    IF_SOK_ZV_HW_Challenge
      data DE_SOK_ZV_HW_Challenge: type=uint64
    IF_SOK_ZV_Rueck_HW_Challenge
      data DE_SOK_ZV_Rueck_HW_Challenge: type=uint64
    IF_Soll_Lehne_LLR_li_1
      data DE_Soll_Lehne_LLR_li_1: type=uint8
    IF_Soll_Lehne_LLR_li_2
      data DE_Soll_Lehne_LLR_li_2: type=uint8
    IF_Soll_Lehne_LLR_re_1
      data DE_Soll_Lehne_LLR_re_1: type=uint8
    IF_Soll_Lehne_LLR_re_2
      data DE_Soll_Lehne_LLR_re_2: type=uint8
    IF_Soll_Sitz_LLR_li_1
      data DE_Soll_Sitz_LLR_li_1: type=uint8
    IF_Soll_Sitz_LLR_li_2
      data DE_Soll_Sitz_LLR_li_2: type=uint8
    IF_Soll_Sitz_LLR_re_1
      data DE_Soll_Sitz_LLR_re_1: type=uint8
    IF_Soll_Sitz_LLR_re_2
      data DE_Soll_Sitz_LLR_re_2: type=uint8
    IF_SoSe_SunInt_2D_Li
      data DE_SoSe_SunInt_2D_Li: type=uint8
    IF_SoSe_SunInt_2D_Re
      data DE_SoSe_SunInt_2D_Re: type=uint8
    IF_SPR_Abschaltstufe
      data DE_SPR_Abschaltstufe: type=uint8
    IF_SPR_BFS_CodierPinError
      data DE_SPR_BFS_CodierPinError: type=boolean
    IF_SPR_BFS_Kompressor_elFehler
      data DE_SPR_BFS_Kompressor_elFehler: type=boolean
    IF_SPR_BFS_Leck_erkannt
      data DE_SPR_BFS_Leck_erkannt: type=boolean
    IF_SPR_BFS_Lokal_aktiv
      data DE_SPR_BFS_Lokal_aktiv: type=boolean
    IF_SPR_BFS_Lordose_hoch
      data DE_SPR_BFS_Lordose_hoch: type=boolean
    IF_SPR_BFS_Lordose_runter
      data DE_SPR_BFS_Lordose_runter: type=boolean
    IF_SPR_BFS_Lordose_vor
      data DE_SPR_BFS_Lordose_vor: type=boolean
    IF_SPR_BFS_Lordose_zurueck
      data DE_SPR_BFS_Lordose_zurueck: type=boolean
    IF_SPR_BFS_Massage_Dauer
      data DE_SPR_BFS_Massage_Dauer: type=uint8
    IF_SPR_BFS_Massage_Int
      data DE_SPR_BFS_Massage_Int: type=uint8
    IF_SPR_BFS_Massage_Intens_Lehne
      data DE_SPR_BFS_Massage_Intens_Lehne: type=uint8
    IF_SPR_BFS_Massage_Intens_Sitz
      data DE_SPR_BFS_Massage_Intens_Sitz: type=uint8
    IF_SPR_BFS_Massage_Prg
      data DE_SPR_BFS_Massage_Prg: type=uint8
    IF_SPR_BFS_Massage_Prg_erweitert
      data DE_SPR_BFS_Massage_Prg_erweitert: type=uint8
    IF_SPR_BFS_MassageStatus
      data DE_SPR_BFS_MassageStatus: type=boolean
    IF_SPR_BFS_Massagetaster_inv
      data DE_SPR_BFS_Massagetaster_inv: type=boolean
    IF_SPR_BFS_MuFu_Fkt_vor
      data DE_SPR_BFS_MuFu_Fkt_vor: type=boolean
    IF_SPR_BFS_MuFu_Fkt_zurueck
      data DE_SPR_BFS_MuFu_Fkt_zurueck: type=boolean
    IF_SPR_BFS_PopUp_Request
      data DE_SPR_BFS_PopUp_Request: type=boolean
    IF_SPR_BFS_ResponseError
      data DE_SPR_BFS_ResponseError: type=boolean
    IF_SPR_BFS_SG_defekt
      data DE_SPR_BFS_SG_defekt: type=boolean
    IF_SPR_BFS_SWL_vor
      data DE_SPR_BFS_SWL_vor: type=boolean
    IF_SPR_BFS_SWL_zurueck
      data DE_SPR_BFS_SWL_zurueck: type=boolean
    IF_SPR_BFS_Systemtest_Status
      data DE_SPR_BFS_Systemtest_Status: type=uint8
    IF_SPR_BFS_Tasterfehler_Massage
      data DE_SPR_BFS_Tasterfehler_Massage: type=boolean
    IF_SPR_BFS_Tasterfehler_Mufu_auf_ab
      data DE_SPR_BFS_Tasterfehler_Mufu_auf_ab: type=boolean
    IF_SPR_BFS_Tasterfehler_Mufu_Ring
      data DE_SPR_BFS_Tasterfehler_Mufu_Ring: type=boolean
    IF_SPR_BFS_Tasterfehler_Mufu_v_z
      data DE_SPR_BFS_Tasterfehler_Mufu_v_z: type=boolean
    IF_SPR_BFS_Teller_inv
      data DE_SPR_BFS_Teller_inv: type=boolean
    IF_SPR_BFS_Ueberspannung
      data DE_SPR_BFS_Ueberspannung: type=boolean
    IF_SPR_BFS_Unterspannung
      data DE_SPR_BFS_Unterspannung: type=boolean
    IF_SPR_BFS_Verstellung_aktiv
      data DE_SPR_BFS_Verstellung_aktiv: type=boolean
    IF_SPR_BFS_Wellness_Status
      data DE_SPR_BFS_Wellness_Status: type=boolean
    IF_SPR_BFS_Wippe_inv
      data DE_SPR_BFS_Wippe_inv: type=boolean
    IF_SPR_FS_CodierPinError
      data DE_SPR_FS_CodierPinError: type=boolean
    IF_SPR_FS_Kompressor_elFehler
      data DE_SPR_FS_Kompressor_elFehler: type=boolean
    IF_SPR_FS_Leck_erkannt
      data DE_SPR_FS_Leck_erkannt: type=boolean
    IF_SPR_FS_Lokal_aktiv
      data DE_SPR_FS_Lokal_aktiv: type=boolean
    IF_SPR_FS_Lordose_hoch
      data DE_SPR_FS_Lordose_hoch: type=boolean
    IF_SPR_FS_Lordose_runter
      data DE_SPR_FS_Lordose_runter: type=boolean
    IF_SPR_FS_Lordose_vor
      data DE_SPR_FS_Lordose_vor: type=boolean
    IF_SPR_FS_Lordose_zurueck
      data DE_SPR_FS_Lordose_zurueck: type=boolean
    IF_SPR_FS_Massage_Dauer
      data DE_SPR_FS_Massage_Dauer: type=uint8
    IF_SPR_FS_Massage_Int
      data DE_SPR_FS_Massage_Int: type=uint8
    IF_SPR_FS_Massage_Intens_Lehne
      data DE_SPR_FS_Massage_Intens_Lehne: type=uint8
    IF_SPR_FS_Massage_Intens_Sitz
      data DE_SPR_FS_Massage_Intens_Sitz: type=uint8
    IF_SPR_FS_Massage_Prg
      data DE_SPR_FS_Massage_Prg: type=uint8
    IF_SPR_FS_Massage_Prg_erweitert
      data DE_SPR_FS_Massage_Prg_erweitert: type=uint8
    IF_SPR_FS_MassageStatus
      data DE_SPR_FS_MassageStatus: type=boolean
    IF_SPR_FS_Massagetaster_inv
      data DE_SPR_FS_Massagetaster_inv: type=boolean
    IF_SPR_FS_MuFu_Fkt_vor
      data DE_SPR_FS_MuFu_Fkt_vor: type=boolean
    IF_SPR_FS_MuFu_Fkt_zurueck
      data DE_SPR_FS_MuFu_Fkt_zurueck: type=boolean
    IF_SPR_FS_PopUp_Request
      data DE_SPR_FS_PopUp_Request: type=boolean
    IF_SPR_FS_ResponseError
      data DE_SPR_FS_ResponseError: type=boolean
    IF_SPR_FS_SG_defekt
      data DE_SPR_FS_SG_defekt: type=boolean
    IF_SPR_FS_SWL_vor
      data DE_SPR_FS_SWL_vor: type=boolean
    IF_SPR_FS_SWL_zurueck
      data DE_SPR_FS_SWL_zurueck: type=boolean
    IF_SPR_FS_Systemtest_Status
      data DE_SPR_FS_Systemtest_Status: type=uint8
    IF_SPR_FS_Tasterfehler_Massage
      data DE_SPR_FS_Tasterfehler_Massage: type=boolean
    IF_SPR_FS_Tasterfehler_Mufu_auf_ab
      data DE_SPR_FS_Tasterfehler_Mufu_auf_ab: type=boolean
    IF_SPR_FS_Tasterfehler_Mufu_Ring
      data DE_SPR_FS_Tasterfehler_Mufu_Ring: type=boolean
    IF_SPR_FS_Tasterfehler_Mufu_v_z
      data DE_SPR_FS_Tasterfehler_Mufu_v_z: type=boolean
    IF_SPR_FS_Teller_inv
      data DE_SPR_FS_Teller_inv: type=boolean
    IF_SPR_FS_Ueberspannung
      data DE_SPR_FS_Ueberspannung: type=boolean
    IF_SPR_FS_Unterspannung
      data DE_SPR_FS_Unterspannung: type=boolean
    IF_SPR_FS_Verstellung_aktiv
      data DE_SPR_FS_Verstellung_aktiv: type=boolean
    IF_SPR_FS_Wellness_Status
      data DE_SPR_FS_Wellness_Status: type=boolean
    IF_SPR_FS_Wippe_inv
      data DE_SPR_FS_Wippe_inv: type=boolean
    IF_SRA_Sequenz_Status
      data DE_SRA_Sequenz_Status: type=boolean
    IF_SRL1_ORUData
      data DE_SRL1_ORUData: type=uint64
    IF_SRL1_ORUDataIndex
      data DE_SRL1_ORUDataIndex: type=uint8
    IF_SRL2_ORUData
      data DE_SRL2_ORUData: type=uint64
    IF_SRL2_ORUDataIndex
      data DE_SRL2_ORUDataIndex: type=uint8
    IF_SRL3_ORUData
      data DE_SRL3_ORUData: type=uint64
    IF_SRL3_ORUDataIndex
      data DE_SRL3_ORUDataIndex: type=uint8
    IF_SRL4_ORUData
      data DE_SRL4_ORUData: type=uint64
    IF_SRL4_ORUDataIndex
      data DE_SRL4_ORUDataIndex: type=uint8
    IF_SRL5_ORUData
      data DE_SRL5_ORUData: type=uint64
    IF_SRL5_ORUDataIndex
      data DE_SRL5_ORUDataIndex: type=uint8
    IF_SRL6_ORUData
      data DE_SRL6_ORUData: type=uint64
    IF_SRL6_ORUDataIndex
      data DE_SRL6_ORUDataIndex: type=uint8
    IF_SRL_HL_01_BZ
      data DE_SRL_HL_01_BZ: type=uint8
    IF_SRL_HL_01_CRC
      data DE_SRL_HL_01_CRC: type=uint8
    IF_SRL_HR_01_BZ
      data DE_SRL_HR_01_BZ: type=uint8
    IF_SRL_HR_01_CRC
      data DE_SRL_HR_01_CRC: type=uint8
    IF_SRL_SL_01_BZ
      data DE_SRL_SL_01_BZ: type=uint8
    IF_SRL_SL_01_CRC
      data DE_SRL_SL_01_CRC: type=uint8
    IF_SRL_SR_01_BZ
      data DE_SRL_SR_01_BZ: type=uint8
    IF_SRL_SR_01_CRC
      data DE_SRL_SR_01_CRC: type=uint8
    IF_SRL_VL_01_BZ
      data DE_SRL_VL_01_BZ: type=uint8
    IF_SRL_VL_01_CRC
      data DE_SRL_VL_01_CRC: type=uint8
    IF_SRL_VR_01_BZ
      data DE_SRL_VR_01_BZ: type=uint8
    IF_SRL_VR_01_CRC
      data DE_SRL_VR_01_CRC: type=uint8
    IF_Stellgliedtest_LRH
      data DE_Stellgliedtest_LRH: type=uint8
    IF_STSG_HBFS_AD_oeffnen_Anf
      data DE_STSG_HBFS_AD_oeffnen_Anf: type=boolean
    IF_STSG_HBFS_Bew_auf
      data DE_STSG_HBFS_Bew_auf: type=boolean
    IF_STSG_HBFS_Bew_zu
      data DE_STSG_HBFS_Bew_zu: type=boolean
    IF_STSG_HBFS_BTF
      data DE_STSG_HBFS_BTF: type=boolean
    IF_STSG_HBFS_entriegeln_anfordern
      data DE_STSG_HBFS_entriegeln_anfordern: type=boolean
    IF_STSG_HBFS_LKKS_Bereich
      data DE_STSG_HBFS_LKKS_Bereich: type=uint8
    IF_STSG_HBFS_ORUData
      data DE_STSG_HBFS_ORUData: type=uint64
    IF_STSG_HBFS_ORUDataIndex
      data DE_STSG_HBFS_ORUDataIndex: type=uint8
    IF_STSG_HBFS_ST_deaktivieren
      data DE_STSG_HBFS_ST_deaktivieren: type=boolean
    IF_STSG_HBFS_TAT
      data DE_STSG_HBFS_TAT: type=boolean
    IF_STSG_HFS_AD_oeffnen_Anf
      data DE_STSG_HFS_AD_oeffnen_Anf: type=boolean
    IF_STSG_HFS_Bew_auf
      data DE_STSG_HFS_Bew_auf: type=boolean
    IF_STSG_HFS_Bew_zu
      data DE_STSG_HFS_Bew_zu: type=boolean
    IF_STSG_HFS_BTF
      data DE_STSG_HFS_BTF: type=boolean
    IF_STSG_HFS_entriegeln_anforderen
      data DE_STSG_HFS_entriegeln_anforderen: type=boolean
    IF_STSG_HFS_LKKS_Bereich
      data DE_STSG_HFS_LKKS_Bereich: type=uint8
    IF_STSG_HFS_ORUData
      data DE_STSG_HFS_ORUData: type=uint64
    IF_STSG_HFS_ORUDataIndex
      data DE_STSG_HFS_ORUDataIndex: type=uint8
    IF_STSG_HFS_ST_deaktivieren
      data DE_STSG_HFS_ST_deaktivieren: type=boolean
    IF_STSG_HFS_TAT
      data DE_STSG_HFS_TAT: type=boolean
    IF_TSG_BFS_ORUData
      data DE_TSG_BFS_ORUData: type=uint64
    IF_TSG_BFS_ORUDataIndex
      data DE_TSG_BFS_ORUDataIndex: type=uint8
    IF_TSG_FHe01_void1
      data DE_TSG_FHe01_void1: type=boolean
    IF_TSG_FHSG_MST_Jahr_k
      data DE_TSG_FHSG_MST_Jahr_k: type=uint8
    IF_TSG_FHSG_MST_KM_Stand_1
      data DE_TSG_FHSG_MST_KM_Stand_1: type=uint16
    IF_TSG_FHSG_MST_KM_Stand_2
      data DE_TSG_FHSG_MST_KM_Stand_2: type=uint8
    IF_TSG_FHSG_MST_Minute_k
      data DE_TSG_FHSG_MST_Minute_k: type=uint8
    IF_TSG_FHSG_MST_Monat_k
      data DE_TSG_FHSG_MST_Monat_k: type=uint8
    IF_TSG_FHSG_MST_Sekunde_k
      data DE_TSG_FHSG_MST_Sekunde_k: type=uint8
    IF_TSG_FHSG_MST_Stunde_k
      data DE_TSG_FHSG_MST_Stunde_k: type=uint8
    IF_TSG_FHSG_MST_Tag_k
      data DE_TSG_FHSG_MST_Tag_k: type=uint8
    IF_TSG_FHSG_MST_Time_Indication_Bit
      data DE_TSG_FHSG_MST_Time_Indication_Bit: type=boolean
    IF_TSG_FHSG_MST_TSG_Seite
      data DE_TSG_FHSG_MST_TSG_Seite: type=boolean
    IF_TSG_FHSG_MST_Verlernzaehler_k
      data DE_TSG_FHSG_MST_Verlernzaehler_k: type=uint8
    IF_TSG_FHSG_void_1
      data DE_TSG_FHSG_void_1: type=uint8
    IF_TSG_FHSG_void_7
      data DE_TSG_FHSG_void_7: type=boolean
    IF_TSG_FS_ORUData
      data DE_TSG_FS_ORUData: type=uint64
    IF_TSG_FS_ORUDataIndex
      data DE_TSG_FS_ORUDataIndex: type=uint8
    IF_TSG_FT_02_BZ
      data DE_TSG_FT_02_BZ: type=uint8
    IF_TSG_FT_02_CRC
      data DE_TSG_FT_02_CRC: type=uint8
    IF_TSG_HBFS_02_BZ
      data DE_TSG_HBFS_02_BZ: type=uint8
    IF_TSG_HBFS_02_CRC
      data DE_TSG_HBFS_02_CRC: type=uint8
    IF_TSG_HBFS_ORUData
      data DE_TSG_HBFS_ORUData: type=uint64
    IF_TSG_HBFS_ORUDataIndex
      data DE_TSG_HBFS_ORUDataIndex: type=uint8
    IF_TSG_HFS_02_BZ
      data DE_TSG_HFS_02_BZ: type=uint8
    IF_TSG_HFS_02_CRC
      data DE_TSG_HFS_02_CRC: type=uint8
    IF_TSG_HFS_ORUData
      data DE_TSG_HFS_ORUData: type=uint64
    IF_TSG_HFS_ORUDataIndex
      data DE_TSG_HFS_ORUDataIndex: type=uint8
    IF_Tuerkontakt_Innenlicht_Status
      data DE_Tuerkontakt_Innenlicht_Status: type=boolean
    IF_Tuerkontakt_Innenlicht_Taste
      data DE_Tuerkontakt_Innenlicht_Taste: type=boolean
    IF_UGDO_Buttons
      data DE_UGDO_Buttons: type=uint8
    IF_UGDO_Failure_Antenne
      data DE_UGDO_Failure_Antenne: type=boolean
    IF_UGDO_Failure_Codierung
      data DE_UGDO_Failure_Codierung: type=boolean
    IF_UGDO_Failure_Hardware
      data DE_UGDO_Failure_Hardware: type=boolean
    IF_UGDO_Function_01
      data DE_UGDO_Function_01: type=uint8
    IF_UGDO_LED_Code_01
      data DE_UGDO_LED_Code_01: type=uint8
    IF_UGDO_ResponseError
      data DE_UGDO_ResponseError: type=boolean
    IF_UGDO_Switchboard
      data DE_UGDO_Switchboard: type=uint8
    IF_UH_Jahr
      data DE_UH_Jahr: type=uint8
    IF_UH_Minute
      data DE_UH_Minute: type=uint8
    IF_UH_Monat
      data DE_UH_Monat: type=uint8
    IF_UH_Sekunde
      data DE_UH_Sekunde: type=uint8
    IF_UH_Stunde
      data DE_UH_Stunde: type=uint8
    IF_UH_Tag
      data DE_UH_Tag: type=uint8
    IF_UHF_01_Data
      data DE_UHF_01_Data: type=uint64
    IF_UHF_01_Datenlaenge
      data DE_UHF_01_Datenlaenge: type=uint16
    IF_UHF_01_Status
      data DE_UHF_01_Status: type=boolean
    IF_UHF_01_Typ
      data DE_UHF_01_Typ: type=boolean
    IF_UHF_01_Zaehler
      data DE_UHF_01_Zaehler: type=uint8
    IF_UHF_02_Data
      data DE_UHF_02_Data: type=uint64
    IF_UHF_02_Zaehler
      data DE_UHF_02_Zaehler: type=uint8
    IF_UHF_03_Data
      data DE_UHF_03_Data: type=uint64
    IF_UHF_03_Zaehler
      data DE_UHF_03_Zaehler: type=uint8
    IF_UHF_04_Data
      data DE_UHF_04_Data: type=uint64
    IF_UHF_04_Zaehler
      data DE_UHF_04_Zaehler: type=uint8
    IF_UHF_05_Data
      data DE_UHF_05_Data: type=uint64
    IF_UHF_05_Zaehler
      data DE_UHF_05_Zaehler: type=uint8
    IF_UHF_06_Data
      data DE_UHF_06_Data: type=uint64
    IF_UHF_06_Zaehler
      data DE_UHF_06_Zaehler: type=uint8
    IF_UHF_07_Data
      data DE_UHF_07_Data: type=uint64
    IF_UHF_07_Zaehler
      data DE_UHF_07_Zaehler: type=uint8
    IF_UHF_08_Data
      data DE_UHF_08_Data: type=uint64
    IF_UHF_08_Zaehler
      data DE_UHF_08_Zaehler: type=uint8
    IF_UHF_FFB_Funkschluesseltyp
      data DE_UHF_FFB_Funkschluesseltyp: type=uint8
    IF_UHF_FFB_SKC_anlernen
      data DE_UHF_FFB_SKC_anlernen: type=boolean
    IF_UHF_Konfig_Auswahl_Kanal
      data DE_UHF_Konfig_Auswahl_Kanal: type=uint8
    IF_UHF_Konfig_Auswahl_Kessymodus
      data DE_UHF_Konfig_Auswahl_Kessymodus: type=uint8
    IF_UHF_Konfig_Auswahl_naechst_Kanal
      data DE_UHF_Konfig_Auswahl_naechst_Kanal: type=uint8
    IF_UHF_Konfig_FFB_Freigabe
      data DE_UHF_Konfig_FFB_Freigabe: type=boolean
    IF_UHF_Konfig_Kanal_Umschaltzeit
      data DE_UHF_Konfig_Kanal_Umschaltzeit: type=uint8
    IF_UHF_Konfig_Praeambellaenge
      data DE_UHF_Konfig_Praeambellaenge: type=uint8
    IF_UHF_Konfig_Zaehler
      data DE_UHF_Konfig_Zaehler: type=uint8
    IF_UHF_Sensor_01_Data
      data DE_UHF_Sensor_01_Data: type=uint64
    IF_UHF_Sensor_01_Datenlaenge
      data DE_UHF_Sensor_01_Datenlaenge: type=uint16
    IF_UHF_Sensor_01_Status
      data DE_UHF_Sensor_01_Status: type=boolean
    IF_UHF_Sensor_01_Typ
      data DE_UHF_Sensor_01_Typ: type=boolean
    IF_UHF_Sensor_01_Zaehler
      data DE_UHF_Sensor_01_Zaehler: type=uint8
    IF_UHF_Sensor_02_Data
      data DE_UHF_Sensor_02_Data: type=uint64
    IF_UHF_Sensor_02_Zaehler
      data DE_UHF_Sensor_02_Zaehler: type=uint8
    IF_UHF_Sensor_03_Data
      data DE_UHF_Sensor_03_Data: type=uint64
    IF_UHF_Sensor_03_Zaehler
      data DE_UHF_Sensor_03_Zaehler: type=uint8
    IF_UHF_Sensor_04_Data
      data DE_UHF_Sensor_04_Data: type=uint64
    IF_UHF_Sensor_04_Zaehler
      data DE_UHF_Sensor_04_Zaehler: type=uint8
    IF_UHF_Sensor_05_Data
      data DE_UHF_Sensor_05_Data: type=uint64
    IF_UHF_Sensor_05_Zaehler
      data DE_UHF_Sensor_05_Zaehler: type=uint8
    IF_UHF_Sensor_06_Data
      data DE_UHF_Sensor_06_Data: type=uint64
    IF_UHF_Sensor_06_Zaehler
      data DE_UHF_Sensor_06_Zaehler: type=uint8
    IF_UHF_Sensor_07_Data
      data DE_UHF_Sensor_07_Data: type=uint64
    IF_UHF_Sensor_07_Zaehler
      data DE_UHF_Sensor_07_Zaehler: type=uint8
    IF_UHF_Sensor_08_Data
      data DE_UHF_Sensor_08_Data: type=uint64
    IF_UHF_Sensor_08_Zaehler
      data DE_UHF_Sensor_08_Zaehler: type=uint8
    IF_UHF_Sensor_RSSI_Wert_IDGeber1
      data DE_UHF_Sensor_RSSI_Wert_IDGeber1: type=uint8
    IF_UHF_Sensor_RSSI_Wert_IDGeber2
      data DE_UHF_Sensor_RSSI_Wert_IDGeber2: type=uint8
    IF_UHF_Sensor_RSSI_Wert_IDGeber3
      data DE_UHF_Sensor_RSSI_Wert_IDGeber3: type=uint8
    IF_UHF_Sensor_RSSI_Wert_IDGeber4
      data DE_UHF_Sensor_RSSI_Wert_IDGeber4: type=uint8
    IF_UHF_Sensor_RSSI_Wert_IDGeber5
      data DE_UHF_Sensor_RSSI_Wert_IDGeber5: type=uint8
    IF_UHF_Sensor_RSSI_Wert_IDGeber6
      data DE_UHF_Sensor_RSSI_Wert_IDGeber6: type=uint8
    IF_UHF_Sensor_RSSI_Wert_IDGeber7
      data DE_UHF_Sensor_RSSI_Wert_IDGeber7: type=uint8
    IF_UHF_Sensor_RSSI_Wert_IDGeber8
      data DE_UHF_Sensor_RSSI_Wert_IDGeber8: type=uint8
    IF_UHF_TranspID_01
      data DE_UHF_TranspID_01: type=uint32
    IF_UHF_TranspID_02
      data DE_UHF_TranspID_02: type=uint32
    IF_UHF_TranspID_03
      data DE_UHF_TranspID_03: type=uint32
    IF_UHF_TranspID_04
      data DE_UHF_TranspID_04: type=uint32
    IF_UHF_TranspID_05
      data DE_UHF_TranspID_05: type=uint32
    IF_UHF_TranspID_06
      data DE_UHF_TranspID_06: type=uint32
    IF_UHF_TranspID_07
      data DE_UHF_TranspID_07: type=uint32
    IF_UHF_TranspID_08
      data DE_UHF_TranspID_08: type=uint32
    IF_Verbauposition_LLR_li
      data DE_Verbauposition_LLR_li: type=boolean
    IF_Verbauposition_LLR_re
      data DE_Verbauposition_LLR_re: type=boolean
    IF_Verglasung_offen
      data DE_Verglasung_offen: type=boolean
    IF_VIN_01_MUX
      data DE_VIN_01_MUX: type=uint8
    IF_VIN_1
      data DE_VIN_1: type=uint8
    IF_VIN_10
      data DE_VIN_10: type=uint8
    IF_VIN_11
      data DE_VIN_11: type=uint8
    IF_VIN_12
      data DE_VIN_12: type=uint8
    IF_VIN_13
      data DE_VIN_13: type=uint8
    IF_VIN_14
      data DE_VIN_14: type=uint8
    IF_VIN_15
      data DE_VIN_15: type=uint8
    IF_VIN_16
      data DE_VIN_16: type=uint8
    IF_VIN_17
      data DE_VIN_17: type=uint8
    IF_VIN_2
      data DE_VIN_2: type=uint8
    IF_VIN_3
      data DE_VIN_3: type=uint8
    IF_VIN_4
      data DE_VIN_4: type=uint8
    IF_VIN_5
      data DE_VIN_5: type=uint8
    IF_VIN_6
      data DE_VIN_6: type=uint8
    IF_VIN_7
      data DE_VIN_7: type=uint8
    IF_VIN_8
      data DE_VIN_8: type=uint8
    IF_VIN_9
      data DE_VIN_9: type=uint8
    IF_VIP_Sensor_betaetigt
      data DE_VIP_Sensor_betaetigt: type=boolean
    IF_VIP_Sensor_STSG_HBFS_betaetigt
      data DE_VIP_Sensor_STSG_HBFS_betaetigt: type=boolean
    IF_VIP_Sensor_STSG_HFS_betaetigt
      data DE_VIP_Sensor_STSG_HFS_betaetigt: type=boolean
    IF_VMM_02_BZ
      data DE_VMM_02_BZ: type=uint8
    IF_VMM_02_CRC
      data DE_VMM_02_CRC: type=uint8
    IF_Waschen_vorne_aktiv
      data DE_Waschen_vorne_aktiv: type=boolean
    IF_Wendelage_oben_Wischer
      data DE_Wendelage_oben_Wischer: type=boolean
    IF_Wendelage_unten_Wischer
      data DE_Wendelage_unten_Wischer: type=boolean
    IF_WFS_ID_Geb_autorisiert_in_Kl15
      data DE_WFS_ID_Geb_autorisiert_in_Kl15: type=boolean
    IF_WFS_Schluessel_Fahrberecht
      data DE_WFS_Schluessel_Fahrberecht: type=uint8
    IF_WH_Frontwaschen
      data DE_WH_Frontwaschen: type=boolean
    IF_WH_Heckintervall
      data DE_WH_Heckintervall: type=boolean
    IF_WH_Heckwaschen
      data DE_WH_Heckwaschen: type=boolean
    IF_WH_Intervall
      data DE_WH_Intervall: type=boolean
    IF_WH_Intervallstufen
      data DE_WH_Intervallstufen: type=uint8
    IF_WH_MFA_Fehler
      data DE_WH_MFA_Fehler: type=boolean
    IF_WH_Tippwischen
      data DE_WH_Tippwischen: type=boolean
    IF_WH_Tipwischen
      data DE_WH_Tipwischen: type=boolean
    IF_WH_Wischer_Fehler
      data DE_WH_Wischer_Fehler: type=boolean
    IF_WH_WischerStufe1
      data DE_WH_WischerStufe1: type=boolean
    IF_WH_WischerStufe1_invers
      data DE_WH_WischerStufe1_invers: type=boolean
    IF_WH_WischerStufe2
      data DE_WH_WischerStufe2: type=boolean
    IF_WH_WischerStufe2_invers
      data DE_WH_WischerStufe2_invers: type=boolean
    IF_Wischer1_Error
      data DE_Wischer1_Error: type=boolean
    IF_Wischer1_ErrorGueltigkeit
      data DE_Wischer1_ErrorGueltigkeit: type=boolean
    IF_Wischer1_Ueberlast
      data DE_Wischer1_Ueberlast: type=boolean
    IF_Wischer1_Wischgeschwindigkeit
      data DE_Wischer1_Wischgeschwindigkeit: type=uint8
    IF_Wischer2_Error
      data DE_Wischer2_Error: type=boolean
    IF_Wischer2_ErrorGueltigkeit
      data DE_Wischer2_ErrorGueltigkeit: type=boolean
    IF_Wischer2_Ueberlast
      data DE_Wischer2_Ueberlast: type=boolean
    IF_Wischer_aktiv
      data DE_Wischer_aktiv: type=boolean
    IF_Wischer_Parklage
      data DE_Wischer_Parklage: type=boolean
    IF_Wischer_ResponseError
      data DE_Wischer_ResponseError: type=boolean
    IF_Wischer_Servicestellung
      data DE_Wischer_Servicestellung: type=boolean
    IF_Wischer_vorne_aktiv
      data DE_Wischer_vorne_aktiv: type=boolean
    IF_Wischer_vorne_blockiert
      data DE_Wischer_vorne_blockiert: type=boolean
    IF_Wischer_vorne_defekt
      data DE_Wischer_vorne_defekt: type=boolean
    IF_Wischer_vorne_Normal
      data DE_Wischer_vorne_Normal: type=boolean
    IF_Wischer_vorne_Parklage
      data DE_Wischer_vorne_Parklage: type=boolean
    IF_Wischer_vorne_Schnell
      data DE_Wischer_vorne_Schnell: type=boolean
    IF_Wischer_Wendelage
      data DE_Wischer_Wendelage: type=boolean
    IF_Wischer_WH_PopUp_Anf
      data DE_Wischer_WH_PopUp_Anf: type=uint8
    IF_Wischer_WH_Typ
      data DE_Wischer_WH_Typ: type=uint8
    IF_Wischzykluszaehler
      data DE_Wischzykluszaehler: type=uint16
    IF_WWS2_aktiv
      data DE_WWS2_aktiv: type=boolean
    IF_WWS2_Error
      data DE_WWS2_Error: type=boolean
    IF_WWS2_ErrorGueltigkeit
      data DE_WWS2_ErrorGueltigkeit: type=boolean
    IF_WWS2_Parklage
      data DE_WWS2_Parklage: type=boolean
    IF_WWS2_Position_Wischerarm
      data DE_WWS2_Position_Wischerarm: type=uint8
    IF_WWS2_ResponseError
      data DE_WWS2_ResponseError: type=boolean
    IF_WWS2_Servicestellung
      data DE_WWS2_Servicestellung: type=boolean
    IF_WWS2_Ueberlast
      data DE_WWS2_Ueberlast: type=boolean
    IF_WWS2_Wendelage
      data DE_WWS2_Wendelage: type=boolean
    IF_WWS_DebugData
      data DE_WWS_DebugData: type=uint8
    IF_WWS_Position_Wischerarm
      data DE_WWS_Position_Wischerarm: type=uint8
    IF_WWS_Produktionsmodus
      data DE_WWS_Produktionsmodus: type=boolean
    IF_WWS_Produktionsmodus_Status
      data DE_WWS_Produktionsmodus_Status: type=boolean
    IF_WWS_Wischgeschwindigkeit
      data DE_WWS_Wischgeschwindigkeit: type=uint8
    IF_WWSs_01_alt
      data DE_WWSs_01_alt: type=boolean
    IF_ZAS_Kl_15
      data DE_ZAS_Kl_15: type=boolean
    IF_ZAS_Kl_S
      data DE_ZAS_Kl_S: type=boolean
    IF_ZFH_HBFS_AutoHoch
      data DE_ZFH_HBFS_AutoHoch: type=boolean
    IF_ZFH_HBFS_AutoTief
      data DE_ZFH_HBFS_AutoTief: type=boolean
    IF_ZFH_HBFS_ManHoch
      data DE_ZFH_HBFS_ManHoch: type=boolean
    IF_ZFH_HBFS_ManTief
      data DE_ZFH_HBFS_ManTief: type=boolean
    IF_ZFH_HFS_AutoHoch
      data DE_ZFH_HFS_AutoHoch: type=boolean
    IF_ZFH_HFS_AutoTief
      data DE_ZFH_HFS_AutoTief: type=boolean
    IF_ZFH_HFS_ManHoch
      data DE_ZFH_HFS_ManHoch: type=boolean
    IF_ZFH_HFS_ManTief
      data DE_ZFH_HFS_ManTief: type=boolean
    IF_ZFH_zentral_auf
      data DE_ZFH_zentral_auf: type=boolean
    IF_ZFH_zentral_zu
      data DE_ZFH_zentral_zu: type=boolean
    IF_ZV_04_BZ
      data DE_ZV_04_BZ: type=uint8
    IF_ZV_04_CRC
      data DE_ZV_04_CRC: type=uint8
    IF_ZV_Anf_Challenge_Auth
      data DE_ZV_Anf_Challenge_Auth: type=boolean
    IF_ZV_auf_BT
      data DE_ZV_auf_BT: type=boolean
    IF_ZV_auf_FT
      data DE_ZV_auf_FT: type=boolean
    IF_ZV_auf_Funk
      data DE_ZV_auf_Funk: type=boolean
    IF_ZV_auf_Kessy
      data DE_ZV_auf_Kessy: type=boolean
    IF_ZV_Bedienstelle_auf
      data DE_ZV_Bedienstelle_auf: type=uint8
    IF_ZV_BT_offen
      data DE_ZV_BT_offen: type=boolean
    IF_ZV_DWA_Einfachhorn_Anf
      data DE_ZV_DWA_Einfachhorn_Anf: type=boolean
    IF_ZV_DWA_Einfachhorn_Takt
      data DE_ZV_DWA_Einfachhorn_Takt: type=boolean
    IF_ZV_Einfachhorn_Anf
      data DE_ZV_Einfachhorn_Anf: type=boolean
    IF_ZV_Einfachhorn_Takt
      data DE_ZV_Einfachhorn_Takt: type=boolean
    IF_ZV_FT_offen
      data DE_ZV_FT_offen: type=boolean
    IF_ZV_gesafet_extern_ist
      data DE_ZV_gesafet_extern_ist: type=boolean
    IF_ZV_gesafet_extern_soll
      data DE_ZV_gesafet_extern_soll: type=boolean
    IF_ZV_HBFS_entriegeln
      data DE_ZV_HBFS_entriegeln: type=boolean
    IF_ZV_HBFS_entriegeln_Auth
      data DE_ZV_HBFS_entriegeln_Auth: type=boolean
    IF_ZV_HBFS_entsafen_Auth
      data DE_ZV_HBFS_entsafen_Auth: type=boolean
    IF_ZV_HBFS_offen
      data DE_ZV_HBFS_offen: type=boolean
    IF_ZV_HBFS_verriegeln
      data DE_ZV_HBFS_verriegeln: type=boolean
    IF_ZV_HD_offen
      data DE_ZV_HD_offen: type=boolean
    IF_ZV_Heckeinzelentriegelung
      data DE_ZV_Heckeinzelentriegelung: type=boolean
    IF_ZV_HFS_entriegeln
      data DE_ZV_HFS_entriegeln: type=boolean
    IF_ZV_HFS_entriegeln_Auth
      data DE_ZV_HFS_entriegeln_Auth: type=boolean
    IF_ZV_HFS_entsafen_Auth
      data DE_ZV_HFS_entsafen_Auth: type=boolean
    IF_ZV_HFS_offen
      data DE_ZV_HFS_offen: type=boolean
    IF_ZV_HFS_verriegeln
      data DE_ZV_HFS_verriegeln: type=boolean
    IF_ZV_Hupe_Anf
      data DE_ZV_Hupe_Anf: type=boolean
    IF_ZV_Hupe_Takt
      data DE_ZV_Hupe_Takt: type=boolean
    IF_ZV_HW_Motor_Lock_HK
      data DE_ZV_HW_Motor_Lock_HK: type=boolean
    IF_ZV_HW_Motor_Lock_HK_Auth
      data DE_ZV_HW_Motor_Lock_HK_Auth: type=boolean
    IF_ZV_HW_Motor_Safe_Hinten
      data DE_ZV_HW_Motor_Safe_Hinten: type=boolean
    IF_ZV_ist_Zustand_verfuegbar
      data DE_ZV_ist_Zustand_verfuegbar: type=boolean
    IF_ZV_Ladeklappe_VerEntriegeln
      data DE_ZV_Ladeklappe_VerEntriegeln: type=uint8
    IF_ZV_LadeklappenStatus
      data DE_ZV_LadeklappenStatus: type=boolean
    IF_ZV_Laderaumabd_elektr_aktiviert
      data DE_ZV_Laderaumabd_elektr_aktiviert: type=boolean
    IF_ZV_Schluessel_Zugang
      data DE_ZV_Schluessel_Zugang: type=uint8
    IF_ZV_Status_Cargolock
      data DE_ZV_Status_Cargolock: type=boolean
    IF_ZV_STSG_HBFS_Anf
      data DE_ZV_STSG_HBFS_Anf: type=boolean
    IF_ZV_STSG_HFS_Anf
      data DE_ZV_STSG_HFS_Anf: type=boolean
    IF_ZV_verriegelt_extern_ist
      data DE_ZV_verriegelt_extern_ist: type=boolean
    IF_ZV_verriegelt_extern_soll
      data DE_ZV_verriegelt_extern_soll: type=boolean
    IF_ZV_verriegelt_intern_ist
      data DE_ZV_verriegelt_intern_ist: type=boolean
    IF_ZV_verriegelt_intern_soll
      data DE_ZV_verriegelt_intern_soll: type=boolean
    IF_ZV_zentral_entsafen
      data DE_ZV_zentral_entsafen: type=boolean
    IF_ZV_zentral_safen
      data DE_ZV_zentral_safen: type=boolean
    IF_ZV_zu_Funk
      data DE_ZV_zu_Funk: type=boolean
    IF_ZV_zu_Kessy
      data DE_ZV_zu_Kessy: type=boolean
package /ComponentTypes
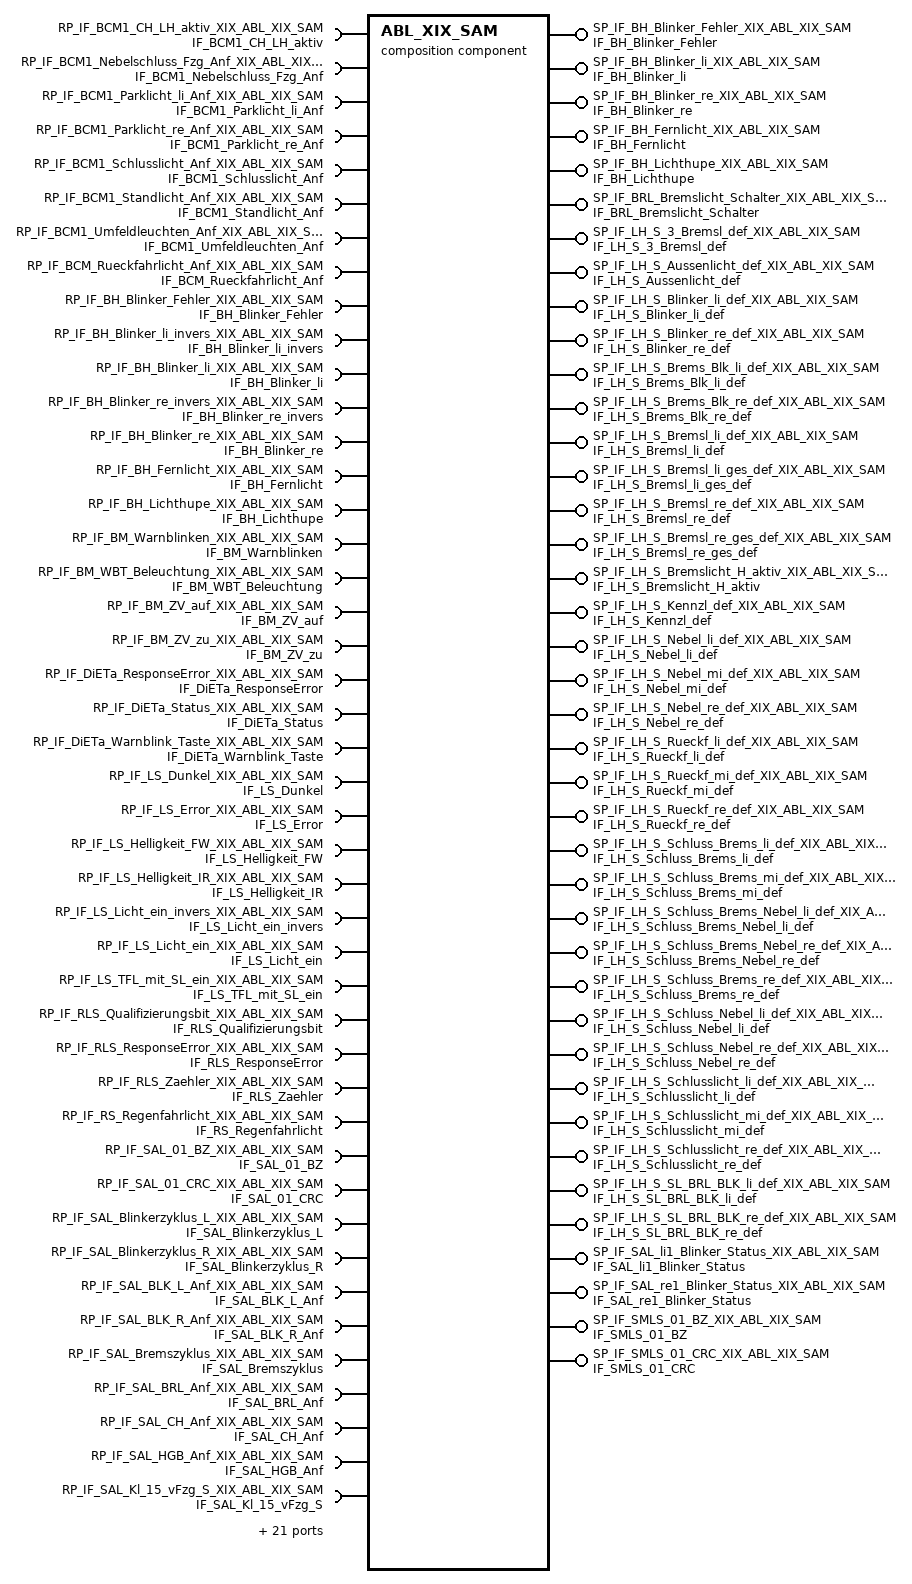
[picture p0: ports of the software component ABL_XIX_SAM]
  composition sw component type ABL_XIX_SAM
    40 x provide port:
      SP_IF_BH_Blinker_Fehler_XIX_ABL_XIX_SAM: provided-interface=IF_BH_Blinker_Fehler
      SP_IF_BH_Blinker_li_XIX_ABL_XIX_SAM: provided-interface=IF_BH_Blinker_li
      SP_IF_BH_Blinker_re_XIX_ABL_XIX_SAM: provided-interface=IF_BH_Blinker_re
      SP_IF_BH_Fernlicht_XIX_ABL_XIX_SAM: provided-interface=IF_BH_Fernlicht
      SP_IF_BH_Lichthupe_XIX_ABL_XIX_SAM: provided-interface=IF_BH_Lichthupe
      SP_IF_BRL_Bremslicht_Schalter_XIX_ABL_XIX_SAM: provided-interface=IF_BRL_Bremslicht_Schalter
      SP_IF_LH_S_3_Bremsl_def_XIX_ABL_XIX_SAM: provided-interface=IF_LH_S_3_Bremsl_def
      SP_IF_LH_S_Aussenlicht_def_XIX_ABL_XIX_SAM: provided-interface=IF_LH_S_Aussenlicht_def
      SP_IF_LH_S_Blinker_li_def_XIX_ABL_XIX_SAM: provided-interface=IF_LH_S_Blinker_li_def
      SP_IF_LH_S_Blinker_re_def_XIX_ABL_XIX_SAM: provided-interface=IF_LH_S_Blinker_re_def
      SP_IF_LH_S_Brems_Blk_li_def_XIX_ABL_XIX_SAM: provided-interface=IF_LH_S_Brems_Blk_li_def
      SP_IF_LH_S_Brems_Blk_re_def_XIX_ABL_XIX_SAM: provided-interface=IF_LH_S_Brems_Blk_re_def
      SP_IF_LH_S_Bremsl_li_def_XIX_ABL_XIX_SAM: provided-interface=IF_LH_S_Bremsl_li_def
      SP_IF_LH_S_Bremsl_li_ges_def_XIX_ABL_XIX_SAM: provided-interface=IF_LH_S_Bremsl_li_ges_def
      SP_IF_LH_S_Bremsl_re_def_XIX_ABL_XIX_SAM: provided-interface=IF_LH_S_Bremsl_re_def
      SP_IF_LH_S_Bremsl_re_ges_def_XIX_ABL_XIX_SAM: provided-interface=IF_LH_S_Bremsl_re_ges_def
      SP_IF_LH_S_Bremslicht_H_aktiv_XIX_ABL_XIX_SAM: provided-interface=IF_LH_S_Bremslicht_H_aktiv
      SP_IF_LH_S_Kennzl_def_XIX_ABL_XIX_SAM: provided-interface=IF_LH_S_Kennzl_def
      SP_IF_LH_S_Nebel_li_def_XIX_ABL_XIX_SAM: provided-interface=IF_LH_S_Nebel_li_def
      SP_IF_LH_S_Nebel_mi_def_XIX_ABL_XIX_SAM: provided-interface=IF_LH_S_Nebel_mi_def
      SP_IF_LH_S_Nebel_re_def_XIX_ABL_XIX_SAM: provided-interface=IF_LH_S_Nebel_re_def
      SP_IF_LH_S_Rueckf_li_def_XIX_ABL_XIX_SAM: provided-interface=IF_LH_S_Rueckf_li_def
      SP_IF_LH_S_Rueckf_mi_def_XIX_ABL_XIX_SAM: provided-interface=IF_LH_S_Rueckf_mi_def
      SP_IF_LH_S_Rueckf_re_def_XIX_ABL_XIX_SAM: provided-interface=IF_LH_S_Rueckf_re_def
      SP_IF_LH_S_Schluss_Brems_li_def_XIX_ABL_XIX_SAM: provided-interface=IF_LH_S_Schluss_Brems_li_def
      SP_IF_LH_S_Schluss_Brems_mi_def_XIX_ABL_XIX_SAM: provided-interface=IF_LH_S_Schluss_Brems_mi_def
      SP_IF_LH_S_Schluss_Brems_Nebel_li_def_XIX_ABL_XIX_SAM: provided-interface=IF_LH_S_Schluss_Brems_Nebel_li_def
      SP_IF_LH_S_Schluss_Brems_Nebel_re_def_XIX_ABL_XIX_SAM: provided-interface=IF_LH_S_Schluss_Brems_Nebel_re_def
      SP_IF_LH_S_Schluss_Brems_re_def_XIX_ABL_XIX_SAM: provided-interface=IF_LH_S_Schluss_Brems_re_def
      SP_IF_LH_S_Schluss_Nebel_li_def_XIX_ABL_XIX_SAM: provided-interface=IF_LH_S_Schluss_Nebel_li_def
      SP_IF_LH_S_Schluss_Nebel_re_def_XIX_ABL_XIX_SAM: provided-interface=IF_LH_S_Schluss_Nebel_re_def
      SP_IF_LH_S_Schlusslicht_li_def_XIX_ABL_XIX_SAM: provided-interface=IF_LH_S_Schlusslicht_li_def
      SP_IF_LH_S_Schlusslicht_mi_def_XIX_ABL_XIX_SAM: provided-interface=IF_LH_S_Schlusslicht_mi_def
      SP_IF_LH_S_Schlusslicht_re_def_XIX_ABL_XIX_SAM: provided-interface=IF_LH_S_Schlusslicht_re_def
      SP_IF_LH_S_SL_BRL_BLK_li_def_XIX_ABL_XIX_SAM: provided-interface=IF_LH_S_SL_BRL_BLK_li_def
      SP_IF_LH_S_SL_BRL_BLK_re_def_XIX_ABL_XIX_SAM: provided-interface=IF_LH_S_SL_BRL_BLK_re_def
      SP_IF_SAL_li1_Blinker_Status_XIX_ABL_XIX_SAM: provided-interface=IF_SAL_li1_Blinker_Status
      SP_IF_SAL_re1_Blinker_Status_XIX_ABL_XIX_SAM: provided-interface=IF_SAL_re1_Blinker_Status
      SP_IF_SMLS_01_BZ_XIX_ABL_XIX_SAM: provided-interface=IF_SMLS_01_BZ
      SP_IF_SMLS_01_CRC_XIX_ABL_XIX_SAM: provided-interface=IF_SMLS_01_CRC
    65 x require port:
      RP_IF_BCM1_CH_LH_aktiv_XIX_ABL_XIX_SAM: required-interface=IF_BCM1_CH_LH_aktiv
      RP_IF_BCM1_Nebelschluss_Fzg_Anf_XIX_ABL_XIX_SAM: required-interface=IF_BCM1_Nebelschluss_Fzg_Anf
      RP_IF_BCM1_Parklicht_li_Anf_XIX_ABL_XIX_SAM: required-interface=IF_BCM1_Parklicht_li_Anf
      RP_IF_BCM1_Parklicht_re_Anf_XIX_ABL_XIX_SAM: required-interface=IF_BCM1_Parklicht_re_Anf
      RP_IF_BCM1_Schlusslicht_Anf_XIX_ABL_XIX_SAM: required-interface=IF_BCM1_Schlusslicht_Anf
      RP_IF_BCM1_Standlicht_Anf_XIX_ABL_XIX_SAM: required-interface=IF_BCM1_Standlicht_Anf
      RP_IF_BCM1_Umfeldleuchten_Anf_XIX_ABL_XIX_SAM: required-interface=IF_BCM1_Umfeldleuchten_Anf
      RP_IF_BCM_Rueckfahrlicht_Anf_XIX_ABL_XIX_SAM: required-interface=IF_BCM_Rueckfahrlicht_Anf
      RP_IF_BH_Blinker_Fehler_XIX_ABL_XIX_SAM: required-interface=IF_BH_Blinker_Fehler
      RP_IF_BH_Blinker_li_invers_XIX_ABL_XIX_SAM: required-interface=IF_BH_Blinker_li_invers
      RP_IF_BH_Blinker_li_XIX_ABL_XIX_SAM: required-interface=IF_BH_Blinker_li
      RP_IF_BH_Blinker_re_invers_XIX_ABL_XIX_SAM: required-interface=IF_BH_Blinker_re_invers
      RP_IF_BH_Blinker_re_XIX_ABL_XIX_SAM: required-interface=IF_BH_Blinker_re
      RP_IF_BH_Fernlicht_XIX_ABL_XIX_SAM: required-interface=IF_BH_Fernlicht
      RP_IF_BH_Lichthupe_XIX_ABL_XIX_SAM: required-interface=IF_BH_Lichthupe
      RP_IF_BM_Warnblinken_XIX_ABL_XIX_SAM: required-interface=IF_BM_Warnblinken
      RP_IF_BM_WBT_Beleuchtung_XIX_ABL_XIX_SAM: required-interface=IF_BM_WBT_Beleuchtung
      RP_IF_BM_ZV_auf_XIX_ABL_XIX_SAM: required-interface=IF_BM_ZV_auf
      RP_IF_BM_ZV_zu_XIX_ABL_XIX_SAM: required-interface=IF_BM_ZV_zu
      RP_IF_DiETa_ResponseError_XIX_ABL_XIX_SAM: required-interface=IF_DiETa_ResponseError
      RP_IF_DiETa_Status_XIX_ABL_XIX_SAM: required-interface=IF_DiETa_Status
      RP_IF_DiETa_Warnblink_Taste_XIX_ABL_XIX_SAM: required-interface=IF_DiETa_Warnblink_Taste
      RP_IF_LS_Dunkel_XIX_ABL_XIX_SAM: required-interface=IF_LS_Dunkel
      RP_IF_LS_Error_XIX_ABL_XIX_SAM: required-interface=IF_LS_Error
      RP_IF_LS_Helligkeit_FW_XIX_ABL_XIX_SAM: required-interface=IF_LS_Helligkeit_FW
      RP_IF_LS_Helligkeit_IR_XIX_ABL_XIX_SAM: required-interface=IF_LS_Helligkeit_IR
      RP_IF_LS_Licht_ein_invers_XIX_ABL_XIX_SAM: required-interface=IF_LS_Licht_ein_invers
      RP_IF_LS_Licht_ein_XIX_ABL_XIX_SAM: required-interface=IF_LS_Licht_ein
      RP_IF_LS_TFL_mit_SL_ein_XIX_ABL_XIX_SAM: required-interface=IF_LS_TFL_mit_SL_ein
      RP_IF_RLS_Qualifizierungsbit_XIX_ABL_XIX_SAM: required-interface=IF_RLS_Qualifizierungsbit
      RP_IF_RLS_ResponseError_XIX_ABL_XIX_SAM: required-interface=IF_RLS_ResponseError
      RP_IF_RLS_Zaehler_XIX_ABL_XIX_SAM: required-interface=IF_RLS_Zaehler
      RP_IF_RS_Regenfahrlicht_XIX_ABL_XIX_SAM: required-interface=IF_RS_Regenfahrlicht
      RP_IF_SAL_01_BZ_XIX_ABL_XIX_SAM: required-interface=IF_SAL_01_BZ
      RP_IF_SAL_01_CRC_XIX_ABL_XIX_SAM: required-interface=IF_SAL_01_CRC
      RP_IF_SAL_Blinkerzyklus_L_XIX_ABL_XIX_SAM: required-interface=IF_SAL_Blinkerzyklus_L
      RP_IF_SAL_Blinkerzyklus_R_XIX_ABL_XIX_SAM: required-interface=IF_SAL_Blinkerzyklus_R
      RP_IF_SAL_BLK_L_Anf_XIX_ABL_XIX_SAM: required-interface=IF_SAL_BLK_L_Anf
      RP_IF_SAL_BLK_R_Anf_XIX_ABL_XIX_SAM: required-interface=IF_SAL_BLK_R_Anf
      RP_IF_SAL_Bremszyklus_XIX_ABL_XIX_SAM: required-interface=IF_SAL_Bremszyklus
      RP_IF_SAL_BRL_Anf_XIX_ABL_XIX_SAM: required-interface=IF_SAL_BRL_Anf
      RP_IF_SAL_CH_Anf_XIX_ABL_XIX_SAM: required-interface=IF_SAL_CH_Anf
      RP_IF_SAL_HGB_Anf_XIX_ABL_XIX_SAM: required-interface=IF_SAL_HGB_Anf
      RP_IF_SAL_Kl_15_vFzg_S_XIX_ABL_XIX_SAM: required-interface=IF_SAL_Kl_15_vFzg_S
      RP_IF_SAL_Kl_15_vFzg_XIX_ABL_XIX_SAM: required-interface=IF_SAL_Kl_15_vFzg
      RP_IF_SAL_Kl_15_XIX_ABL_XIX_SAM: required-interface=IF_SAL_Kl_15
      RP_IF_SAL_KL_50_5s_XIX_ABL_XIX_SAM: required-interface=IF_SAL_KL_50_5s
      RP_IF_SAL_KL_50_XIX_ABL_XIX_SAM: required-interface=IF_SAL_KL_50
      RP_IF_SAL_KL_75_vFzg_XIX_ABL_XIX_SAM: required-interface=IF_SAL_KL_75_vFzg
      RP_IF_SAL_Kl_75_XIX_ABL_XIX_SAM: required-interface=IF_SAL_Kl_75
      RP_IF_SAL_KL_75a_vFzg_XIX_ABL_XIX_SAM: required-interface=IF_SAL_KL_75a_vFzg
      RP_IF_SAL_KL_75a_XIX_ABL_XIX_SAM: required-interface=IF_SAL_KL_75a
      RP_IF_SAL_KZL_Anf_XIX_ABL_XIX_SAM: required-interface=IF_SAL_KZL_Anf
      RP_IF_SAL_LDS_Abblendlicht_Anf_XIX_ABL_XIX_SAM: required-interface=IF_SAL_LDS_Abblendlicht_Anf
      RP_IF_SAL_LDS_Assistenzfahrlicht_Anf_XIX_ABL_XIX_SAM: required-interface=IF_SAL_LDS_Assistenzfahrlicht_Anf
      RP_IF_SAL_LDS_Nullstellung_Anf_XIX_ABL_XIX_SAM: required-interface=IF_SAL_LDS_Nullstellung_Anf
      RP_IF_SAL_LDS_Standlicht_Anf_XIX_ABL_XIX_SAM: required-interface=IF_SAL_LDS_Standlicht_Anf
      RP_IF_SAL_LH_Anf_XIX_ABL_XIX_SAM: required-interface=IF_SAL_LH_Anf
      RP_IF_SAL_NSL_Anf_XIX_ABL_XIX_SAM: required-interface=IF_SAL_NSL_Anf
      RP_IF_SAL_PL_L_Anf_XIX_ABL_XIX_SAM: required-interface=IF_SAL_PL_L_Anf
      RP_IF_SAL_PL_R_Anf_XIX_ABL_XIX_SAM: required-interface=IF_SAL_PL_R_Anf
      RP_IF_SAL_RFL_Anf_XIX_ABL_XIX_SAM: required-interface=IF_SAL_RFL_Anf
      RP_IF_SAL_SL_Anf_XIX_ABL_XIX_SAM: required-interface=IF_SAL_SL_Anf
      RP_IF_SAL_WBT_Bel_XIX_ABL_XIX_SAM: required-interface=IF_SAL_WBT_Bel
      RP_IF_SI_BUS_09_XIX_ABL_XIX_SAM: required-interface=IF_SI_BUS_09
  composition sw component type Basis_Klima_XIX_SAM
    require port RP_IF_OPS_ComfortReadyStatus_XIX_Basis_Klima_XIX_SAM: required-interface=IF_OPS_ComfortReadyStatus
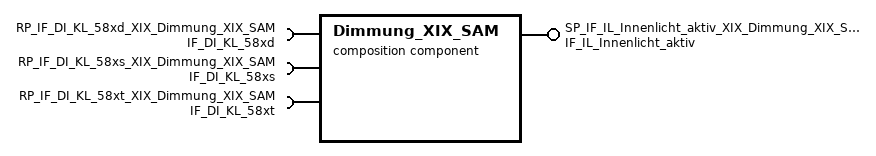
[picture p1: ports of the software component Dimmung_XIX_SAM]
  composition sw component type Dimmung_XIX_SAM
    provide port SP_IF_IL_Innenlicht_aktiv_XIX_Dimmung_XIX_SAM: provided-interface=IF_IL_Innenlicht_aktiv
    require port RP_IF_DI_KL_58xd_XIX_Dimmung_XIX_SAM: required-interface=IF_DI_KL_58xd
    require port RP_IF_DI_KL_58xs_XIX_Dimmung_XIX_SAM: required-interface=IF_DI_KL_58xs
    require port RP_IF_DI_KL_58xt_XIX_Dimmung_XIX_SAM: required-interface=IF_DI_KL_58xt
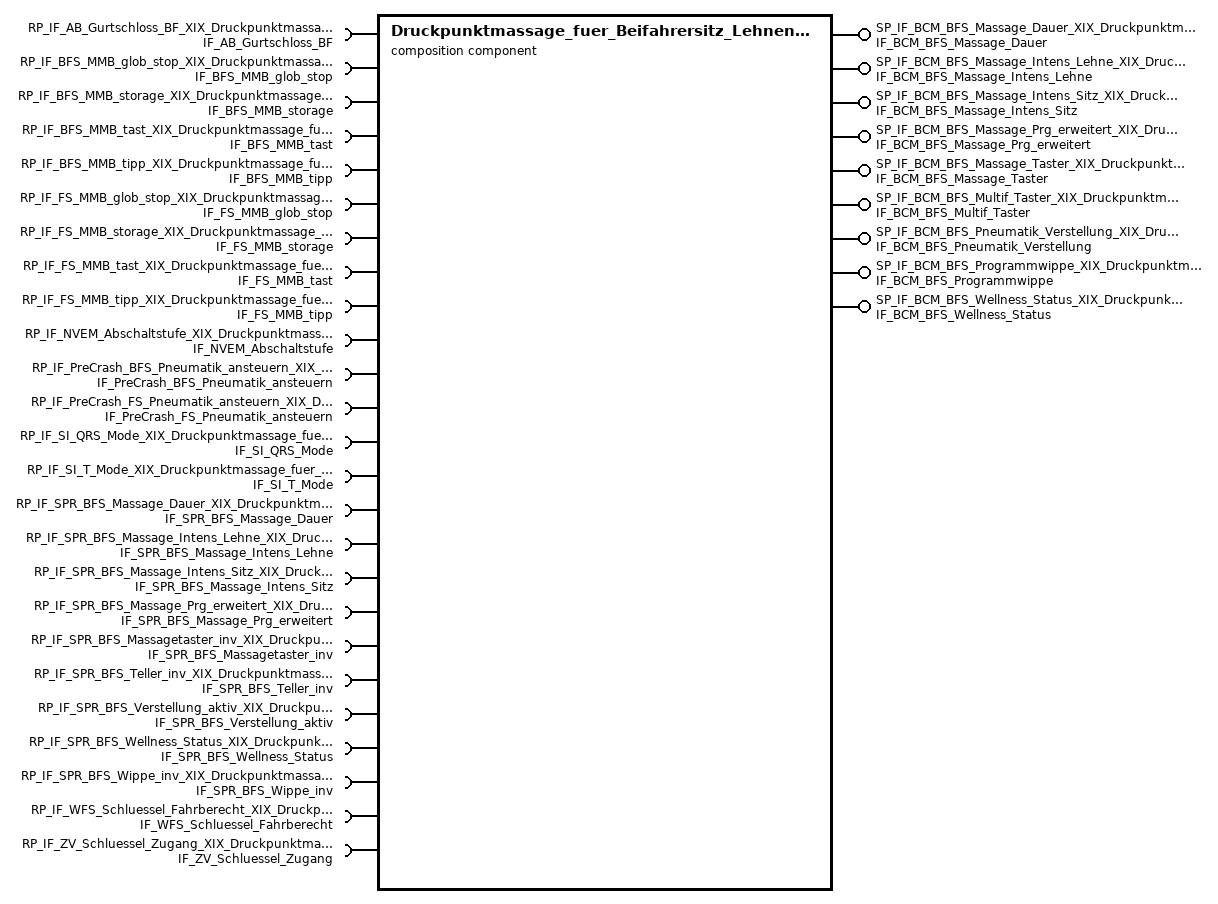
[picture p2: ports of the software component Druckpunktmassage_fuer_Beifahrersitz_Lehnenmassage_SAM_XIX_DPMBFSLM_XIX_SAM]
  composition sw component type Druckpunktmassage_fuer_Beifahrersitz_Lehnenmassage_SAM_XIX_DPMBFSLM_XIX_SAM
    9 x provide port:
      SP_IF_BCM_BFS_Massage_Dauer_XIX_Druckpunktmassage_fuer_Beifahrersitz_Lehnenmassage_SAM_XIX_DPMBFSLM_XIX_SAM: provided-interface=IF_BCM_BFS_Massage_Dauer
      SP_IF_BCM_BFS_Massage_Intens_Lehne_XIX_Druckpunktmassage_fuer_Beifahrersitz_Lehnenmassage_SAM_XIX_DPMBFSLM_XIX_SAM: provided-interface=IF_BCM_BFS_Massage_Intens_Lehne
      SP_IF_BCM_BFS_Massage_Intens_Sitz_XIX_Druckpunktmassage_fuer_Beifahrersitz_Lehnenmassage_SAM_XIX_DPMBFSLM_XIX_SAM: provided-interface=IF_BCM_BFS_Massage_Intens_Sitz
      SP_IF_BCM_BFS_Massage_Prg_erweitert_XIX_Druckpunktmassage_fuer_Beifahrersitz_Lehnenmassage_SAM_XIX_DPMBFSLM_XIX_SAM: provided-interface=IF_BCM_BFS_Massage_Prg_erweitert
      SP_IF_BCM_BFS_Massage_Taster_XIX_Druckpunktmassage_fuer_Beifahrersitz_Lehnenmassage_SAM_XIX_DPMBFSLM_XIX_SAM: provided-interface=IF_BCM_BFS_Massage_Taster
      SP_IF_BCM_BFS_Multif_Taster_XIX_Druckpunktmassage_fuer_Beifahrersitz_Lehnenmassage_SAM_XIX_DPMBFSLM_XIX_SAM: provided-interface=IF_BCM_BFS_Multif_Taster
      SP_IF_BCM_BFS_Pneumatik_Verstellung_XIX_Druckpunktmassage_fuer_Beifahrersitz_Lehnenmassage_SAM_XIX_DPMBFSLM_XIX_SAM: provided-interface=IF_BCM_BFS_Pneumatik_Verstellung
      SP_IF_BCM_BFS_Programmwippe_XIX_Druckpunktmassage_fuer_Beifahrersitz_Lehnenmassage_SAM_XIX_DPMBFSLM_XIX_SAM: provided-interface=IF_BCM_BFS_Programmwippe
      SP_IF_BCM_BFS_Wellness_Status_XIX_Druckpunktmassage_fuer_Beifahrersitz_Lehnenmassage_SAM_XIX_DPMBFSLM_XIX_SAM: provided-interface=IF_BCM_BFS_Wellness_Status
    25 x require port:
      RP_IF_AB_Gurtschloss_BF_XIX_Druckpunktmassage_fuer_Beifahrersitz_Lehnenmassage_SAM_XIX_DPMBFSLM_XIX_SAM: required-interface=IF_AB_Gurtschloss_BF
      RP_IF_BFS_MMB_glob_stop_XIX_Druckpunktmassage_fuer_Beifahrersitz_Lehnenmassage_SAM_XIX_DPMBFSLM_XIX_SAM: required-interface=IF_BFS_MMB_glob_stop
      RP_IF_BFS_MMB_storage_XIX_Druckpunktmassage_fuer_Beifahrersitz_Lehnenmassage_SAM_XIX_DPMBFSLM_XIX_SAM: required-interface=IF_BFS_MMB_storage
      RP_IF_BFS_MMB_tast_XIX_Druckpunktmassage_fuer_Beifahrersitz_Lehnenmassage_SAM_XIX_DPMBFSLM_XIX_SAM: required-interface=IF_BFS_MMB_tast
      RP_IF_BFS_MMB_tipp_XIX_Druckpunktmassage_fuer_Beifahrersitz_Lehnenmassage_SAM_XIX_DPMBFSLM_XIX_SAM: required-interface=IF_BFS_MMB_tipp
      RP_IF_FS_MMB_glob_stop_XIX_Druckpunktmassage_fuer_Beifahrersitz_Lehnenmassage_SAM_XIX_DPMBFSLM_XIX_SAM: required-interface=IF_FS_MMB_glob_stop
      RP_IF_FS_MMB_storage_XIX_Druckpunktmassage_fuer_Beifahrersitz_Lehnenmassage_SAM_XIX_DPMBFSLM_XIX_SAM: required-interface=IF_FS_MMB_storage
      RP_IF_FS_MMB_tast_XIX_Druckpunktmassage_fuer_Beifahrersitz_Lehnenmassage_SAM_XIX_DPMBFSLM_XIX_SAM: required-interface=IF_FS_MMB_tast
      RP_IF_FS_MMB_tipp_XIX_Druckpunktmassage_fuer_Beifahrersitz_Lehnenmassage_SAM_XIX_DPMBFSLM_XIX_SAM: required-interface=IF_FS_MMB_tipp
      RP_IF_NVEM_Abschaltstufe_XIX_Druckpunktmassage_fuer_Beifahrersitz_Lehnenmassage_SAM_XIX_DPMBFSLM_XIX_SAM: required-interface=IF_NVEM_Abschaltstufe
      RP_IF_PreCrash_BFS_Pneumatik_ansteuern_XIX_Druckpunktmassage_fuer_Beifahrersitz_Lehnenmassage_SAM_XIX_DPMBFSLM_XIX_SAM: required-interface=IF_PreCrash_BFS_Pneumatik_ansteuern
      RP_IF_PreCrash_FS_Pneumatik_ansteuern_XIX_Druckpunktmassage_fuer_Beifahrersitz_Lehnenmassage_SAM_XIX_DPMBFSLM_XIX_SAM: required-interface=IF_PreCrash_FS_Pneumatik_ansteuern
      RP_IF_SI_QRS_Mode_XIX_Druckpunktmassage_fuer_Beifahrersitz_Lehnenmassage_SAM_XIX_DPMBFSLM_XIX_SAM: required-interface=IF_SI_QRS_Mode
      RP_IF_SI_T_Mode_XIX_Druckpunktmassage_fuer_Beifahrersitz_Lehnenmassage_SAM_XIX_DPMBFSLM_XIX_SAM: required-interface=IF_SI_T_Mode
      RP_IF_SPR_BFS_Massage_Dauer_XIX_Druckpunktmassage_fuer_Beifahrersitz_Lehnenmassage_SAM_XIX_DPMBFSLM_XIX_SAM: required-interface=IF_SPR_BFS_Massage_Dauer
      RP_IF_SPR_BFS_Massage_Intens_Lehne_XIX_Druckpunktmassage_fuer_Beifahrersitz_Lehnenmassage_SAM_XIX_DPMBFSLM_XIX_SAM: required-interface=IF_SPR_BFS_Massage_Intens_Lehne
      RP_IF_SPR_BFS_Massage_Intens_Sitz_XIX_Druckpunktmassage_fuer_Beifahrersitz_Lehnenmassage_SAM_XIX_DPMBFSLM_XIX_SAM: required-interface=IF_SPR_BFS_Massage_Intens_Sitz
      RP_IF_SPR_BFS_Massage_Prg_erweitert_XIX_Druckpunktmassage_fuer_Beifahrersitz_Lehnenmassage_SAM_XIX_DPMBFSLM_XIX_SAM: required-interface=IF_SPR_BFS_Massage_Prg_erweitert
      RP_IF_SPR_BFS_Massagetaster_inv_XIX_Druckpunktmassage_fuer_Beifahrersitz_Lehnenmassage_SAM_XIX_DPMBFSLM_XIX_SAM: required-interface=IF_SPR_BFS_Massagetaster_inv
      RP_IF_SPR_BFS_Teller_inv_XIX_Druckpunktmassage_fuer_Beifahrersitz_Lehnenmassage_SAM_XIX_DPMBFSLM_XIX_SAM: required-interface=IF_SPR_BFS_Teller_inv
      RP_IF_SPR_BFS_Verstellung_aktiv_XIX_Druckpunktmassage_fuer_Beifahrersitz_Lehnenmassage_SAM_XIX_DPMBFSLM_XIX_SAM: required-interface=IF_SPR_BFS_Verstellung_aktiv
      RP_IF_SPR_BFS_Wellness_Status_XIX_Druckpunktmassage_fuer_Beifahrersitz_Lehnenmassage_SAM_XIX_DPMBFSLM_XIX_SAM: required-interface=IF_SPR_BFS_Wellness_Status
      RP_IF_SPR_BFS_Wippe_inv_XIX_Druckpunktmassage_fuer_Beifahrersitz_Lehnenmassage_SAM_XIX_DPMBFSLM_XIX_SAM: required-interface=IF_SPR_BFS_Wippe_inv
      RP_IF_WFS_Schluessel_Fahrberecht_XIX_Druckpunktmassage_fuer_Beifahrersitz_Lehnenmassage_SAM_XIX_DPMBFSLM_XIX_SAM: required-interface=IF_WFS_Schluessel_Fahrberecht
      RP_IF_ZV_Schluessel_Zugang_XIX_Druckpunktmassage_fuer_Beifahrersitz_Lehnenmassage_SAM_XIX_DPMBFSLM_XIX_SAM: required-interface=IF_ZV_Schluessel_Zugang
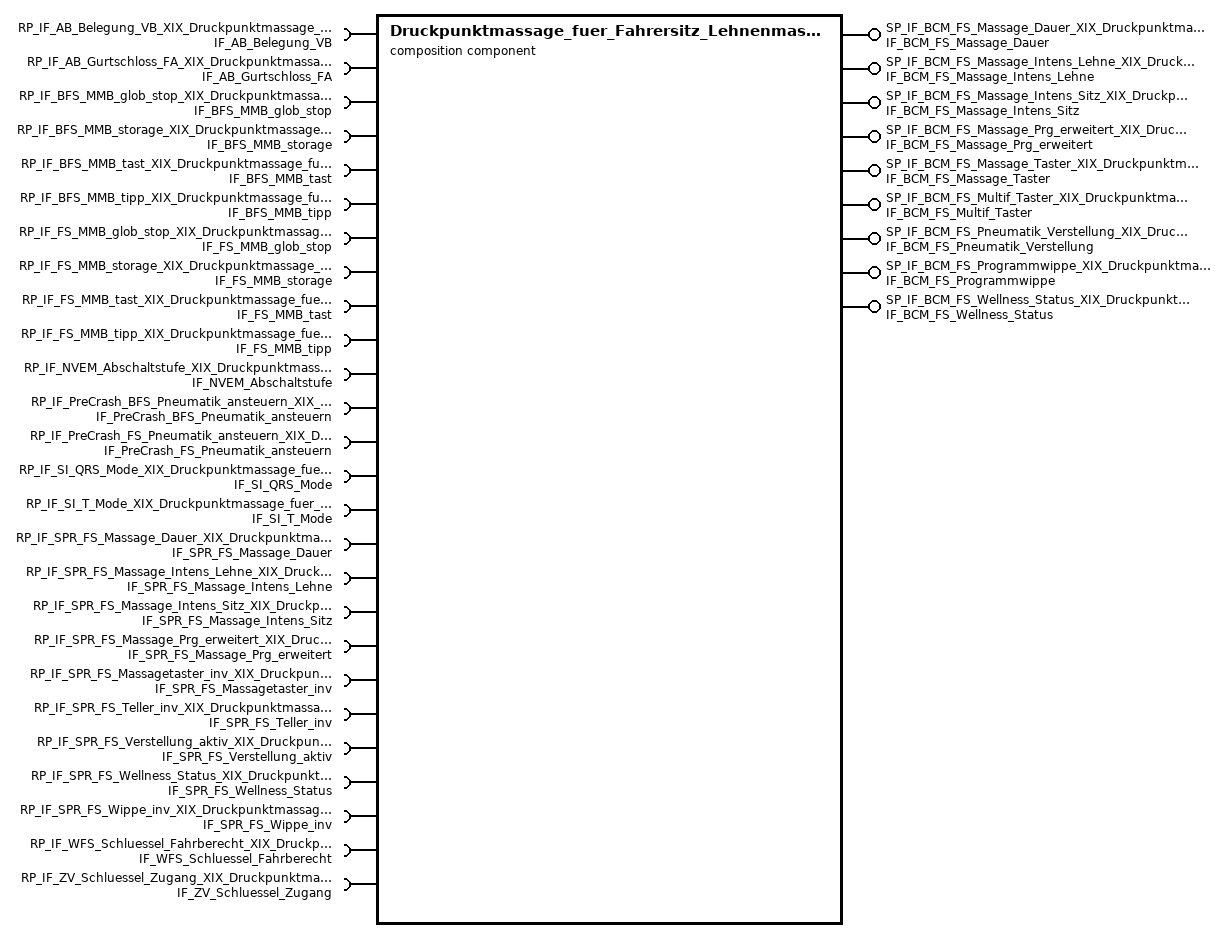
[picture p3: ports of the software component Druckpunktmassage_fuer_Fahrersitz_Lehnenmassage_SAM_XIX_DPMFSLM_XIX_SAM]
  composition sw component type Druckpunktmassage_fuer_Fahrersitz_Lehnenmassage_SAM_XIX_DPMFSLM_XIX_SAM
    9 x provide port:
      SP_IF_BCM_FS_Massage_Dauer_XIX_Druckpunktmassage_fuer_Fahrersitz_Lehnenmassage_SAM_XIX_DPMFSLM_XIX_SAM: provided-interface=IF_BCM_FS_Massage_Dauer
      SP_IF_BCM_FS_Massage_Intens_Lehne_XIX_Druckpunktmassage_fuer_Fahrersitz_Lehnenmassage_SAM_XIX_DPMFSLM_XIX_SAM: provided-interface=IF_BCM_FS_Massage_Intens_Lehne
      SP_IF_BCM_FS_Massage_Intens_Sitz_XIX_Druckpunktmassage_fuer_Fahrersitz_Lehnenmassage_SAM_XIX_DPMFSLM_XIX_SAM: provided-interface=IF_BCM_FS_Massage_Intens_Sitz
      SP_IF_BCM_FS_Massage_Prg_erweitert_XIX_Druckpunktmassage_fuer_Fahrersitz_Lehnenmassage_SAM_XIX_DPMFSLM_XIX_SAM: provided-interface=IF_BCM_FS_Massage_Prg_erweitert
      SP_IF_BCM_FS_Massage_Taster_XIX_Druckpunktmassage_fuer_Fahrersitz_Lehnenmassage_SAM_XIX_DPMFSLM_XIX_SAM: provided-interface=IF_BCM_FS_Massage_Taster
      SP_IF_BCM_FS_Multif_Taster_XIX_Druckpunktmassage_fuer_Fahrersitz_Lehnenmassage_SAM_XIX_DPMFSLM_XIX_SAM: provided-interface=IF_BCM_FS_Multif_Taster
      SP_IF_BCM_FS_Pneumatik_Verstellung_XIX_Druckpunktmassage_fuer_Fahrersitz_Lehnenmassage_SAM_XIX_DPMFSLM_XIX_SAM: provided-interface=IF_BCM_FS_Pneumatik_Verstellung
      SP_IF_BCM_FS_Programmwippe_XIX_Druckpunktmassage_fuer_Fahrersitz_Lehnenmassage_SAM_XIX_DPMFSLM_XIX_SAM: provided-interface=IF_BCM_FS_Programmwippe
      SP_IF_BCM_FS_Wellness_Status_XIX_Druckpunktmassage_fuer_Fahrersitz_Lehnenmassage_SAM_XIX_DPMFSLM_XIX_SAM: provided-interface=IF_BCM_FS_Wellness_Status
    26 x require port:
      RP_IF_AB_Belegung_VB_XIX_Druckpunktmassage_fuer_Fahrersitz_Lehnenmassage_SAM_XIX_DPMFSLM_XIX_SAM: required-interface=IF_AB_Belegung_VB
      RP_IF_AB_Gurtschloss_FA_XIX_Druckpunktmassage_fuer_Fahrersitz_Lehnenmassage_SAM_XIX_DPMFSLM_XIX_SAM: required-interface=IF_AB_Gurtschloss_FA
      RP_IF_BFS_MMB_glob_stop_XIX_Druckpunktmassage_fuer_Fahrersitz_Lehnenmassage_SAM_XIX_DPMFSLM_XIX_SAM: required-interface=IF_BFS_MMB_glob_stop
      RP_IF_BFS_MMB_storage_XIX_Druckpunktmassage_fuer_Fahrersitz_Lehnenmassage_SAM_XIX_DPMFSLM_XIX_SAM: required-interface=IF_BFS_MMB_storage
      RP_IF_BFS_MMB_tast_XIX_Druckpunktmassage_fuer_Fahrersitz_Lehnenmassage_SAM_XIX_DPMFSLM_XIX_SAM: required-interface=IF_BFS_MMB_tast
      RP_IF_BFS_MMB_tipp_XIX_Druckpunktmassage_fuer_Fahrersitz_Lehnenmassage_SAM_XIX_DPMFSLM_XIX_SAM: required-interface=IF_BFS_MMB_tipp
      RP_IF_FS_MMB_glob_stop_XIX_Druckpunktmassage_fuer_Fahrersitz_Lehnenmassage_SAM_XIX_DPMFSLM_XIX_SAM: required-interface=IF_FS_MMB_glob_stop
      RP_IF_FS_MMB_storage_XIX_Druckpunktmassage_fuer_Fahrersitz_Lehnenmassage_SAM_XIX_DPMFSLM_XIX_SAM: required-interface=IF_FS_MMB_storage
      RP_IF_FS_MMB_tast_XIX_Druckpunktmassage_fuer_Fahrersitz_Lehnenmassage_SAM_XIX_DPMFSLM_XIX_SAM: required-interface=IF_FS_MMB_tast
      RP_IF_FS_MMB_tipp_XIX_Druckpunktmassage_fuer_Fahrersitz_Lehnenmassage_SAM_XIX_DPMFSLM_XIX_SAM: required-interface=IF_FS_MMB_tipp
      RP_IF_NVEM_Abschaltstufe_XIX_Druckpunktmassage_fuer_Fahrersitz_Lehnenmassage_SAM_XIX_DPMFSLM_XIX_SAM: required-interface=IF_NVEM_Abschaltstufe
      RP_IF_PreCrash_BFS_Pneumatik_ansteuern_XIX_Druckpunktmassage_fuer_Fahrersitz_Lehnenmassage_SAM_XIX_DPMFSLM_XIX_SAM: required-interface=IF_PreCrash_BFS_Pneumatik_ansteuern
      RP_IF_PreCrash_FS_Pneumatik_ansteuern_XIX_Druckpunktmassage_fuer_Fahrersitz_Lehnenmassage_SAM_XIX_DPMFSLM_XIX_SAM: required-interface=IF_PreCrash_FS_Pneumatik_ansteuern
      RP_IF_SI_QRS_Mode_XIX_Druckpunktmassage_fuer_Fahrersitz_Lehnenmassage_SAM_XIX_DPMFSLM_XIX_SAM: required-interface=IF_SI_QRS_Mode
      RP_IF_SI_T_Mode_XIX_Druckpunktmassage_fuer_Fahrersitz_Lehnenmassage_SAM_XIX_DPMFSLM_XIX_SAM: required-interface=IF_SI_T_Mode
      RP_IF_SPR_FS_Massage_Dauer_XIX_Druckpunktmassage_fuer_Fahrersitz_Lehnenmassage_SAM_XIX_DPMFSLM_XIX_SAM: required-interface=IF_SPR_FS_Massage_Dauer
      RP_IF_SPR_FS_Massage_Intens_Lehne_XIX_Druckpunktmassage_fuer_Fahrersitz_Lehnenmassage_SAM_XIX_DPMFSLM_XIX_SAM: required-interface=IF_SPR_FS_Massage_Intens_Lehne
      RP_IF_SPR_FS_Massage_Intens_Sitz_XIX_Druckpunktmassage_fuer_Fahrersitz_Lehnenmassage_SAM_XIX_DPMFSLM_XIX_SAM: required-interface=IF_SPR_FS_Massage_Intens_Sitz
      RP_IF_SPR_FS_Massage_Prg_erweitert_XIX_Druckpunktmassage_fuer_Fahrersitz_Lehnenmassage_SAM_XIX_DPMFSLM_XIX_SAM: required-interface=IF_SPR_FS_Massage_Prg_erweitert
      RP_IF_SPR_FS_Massagetaster_inv_XIX_Druckpunktmassage_fuer_Fahrersitz_Lehnenmassage_SAM_XIX_DPMFSLM_XIX_SAM: required-interface=IF_SPR_FS_Massagetaster_inv
      RP_IF_SPR_FS_Teller_inv_XIX_Druckpunktmassage_fuer_Fahrersitz_Lehnenmassage_SAM_XIX_DPMFSLM_XIX_SAM: required-interface=IF_SPR_FS_Teller_inv
      RP_IF_SPR_FS_Verstellung_aktiv_XIX_Druckpunktmassage_fuer_Fahrersitz_Lehnenmassage_SAM_XIX_DPMFSLM_XIX_SAM: required-interface=IF_SPR_FS_Verstellung_aktiv
      RP_IF_SPR_FS_Wellness_Status_XIX_Druckpunktmassage_fuer_Fahrersitz_Lehnenmassage_SAM_XIX_DPMFSLM_XIX_SAM: required-interface=IF_SPR_FS_Wellness_Status
      RP_IF_SPR_FS_Wippe_inv_XIX_Druckpunktmassage_fuer_Fahrersitz_Lehnenmassage_SAM_XIX_DPMFSLM_XIX_SAM: required-interface=IF_SPR_FS_Wippe_inv
      RP_IF_WFS_Schluessel_Fahrberecht_XIX_Druckpunktmassage_fuer_Fahrersitz_Lehnenmassage_SAM_XIX_DPMFSLM_XIX_SAM: required-interface=IF_WFS_Schluessel_Fahrberecht
      RP_IF_ZV_Schluessel_Zugang_XIX_Druckpunktmassage_fuer_Fahrersitz_Lehnenmassage_SAM_XIX_DPMFSLM_XIX_SAM: required-interface=IF_ZV_Schluessel_Zugang
